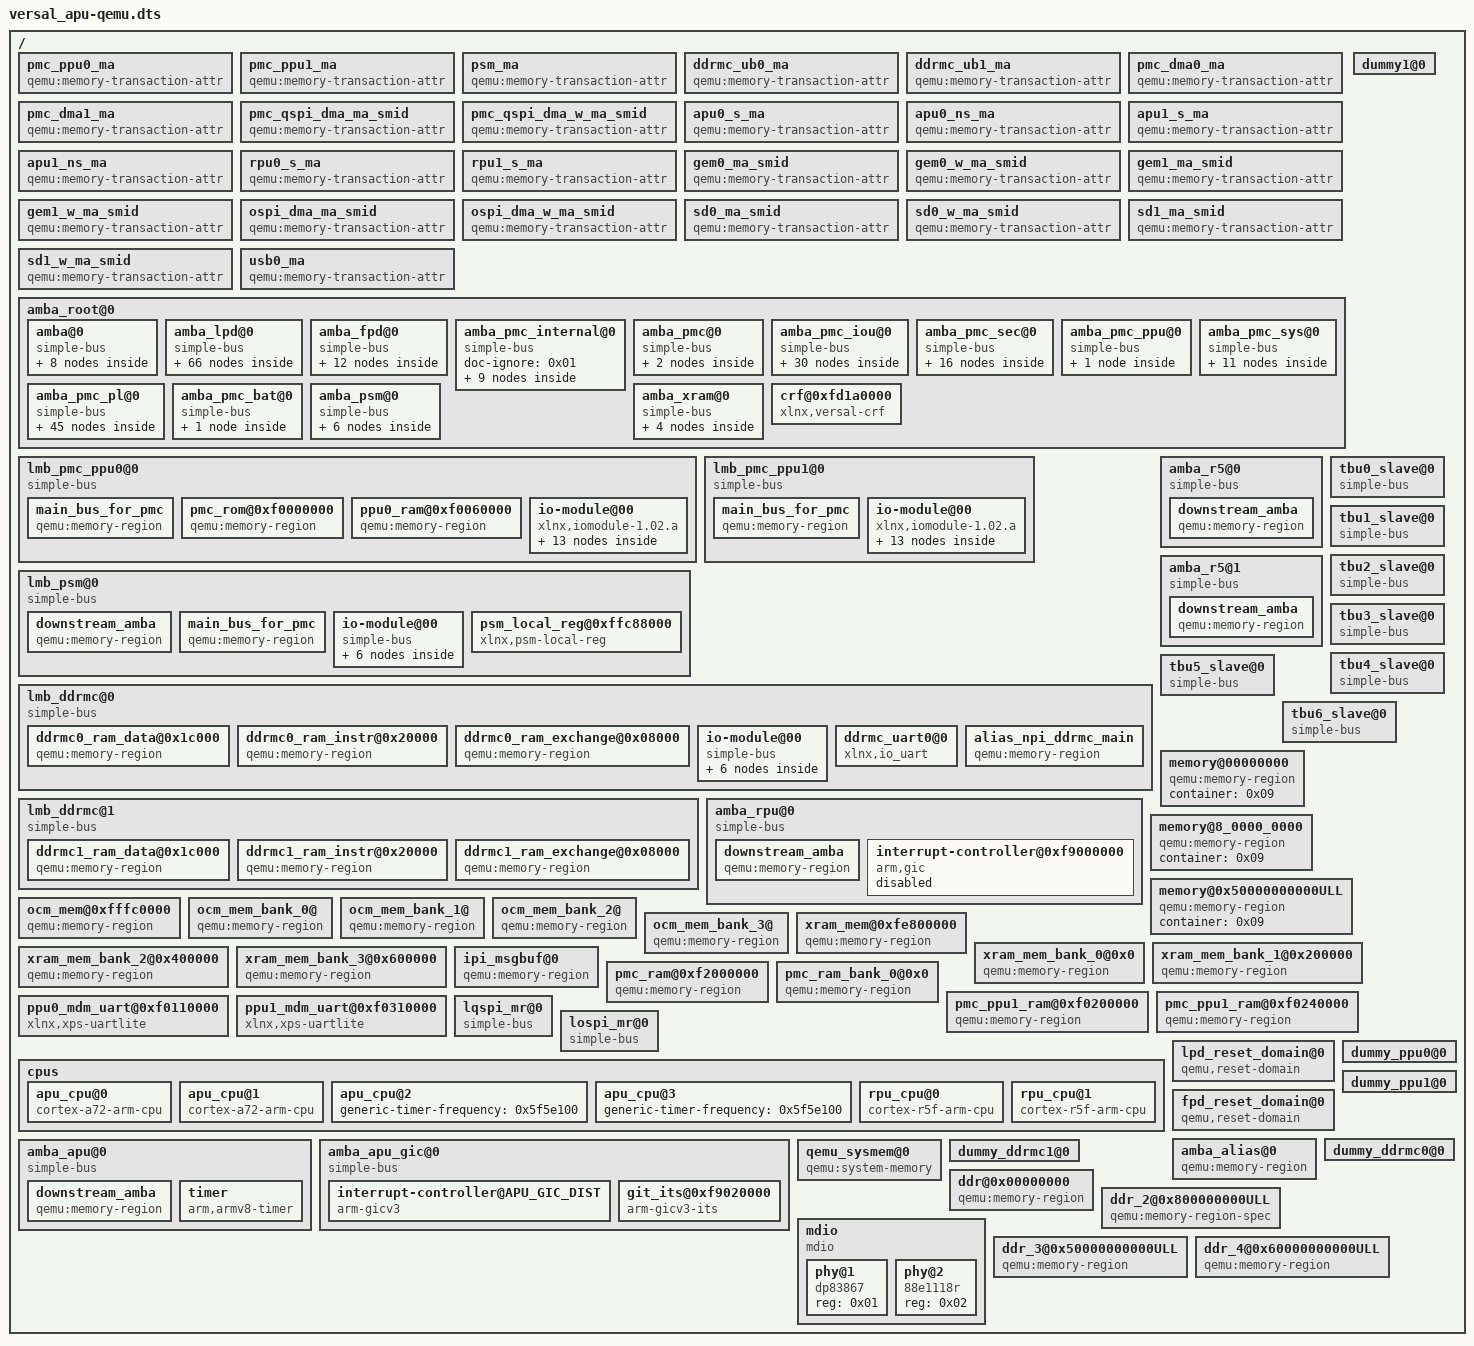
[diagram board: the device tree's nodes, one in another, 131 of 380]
/*
 * Copyright (c) 2025, Advanced Micro Devices, Inc.
 *
 * SPDX-License-Identifier: Apache-2.0
 */

/*
 * NOTE: QEMU EMULATION CONFIGURATION FILE
 *
 * This Device Tree Source (DTS) file is used EXCLUSIVELY for QEMU emulation
 * configuration. It is NOT used by any Zephyr device drivers.
 *
 * Purpose:
 * --------
 * This file provides hardware description for QEMU to emulate the AMD Versal
 * APU platform. QEMU uses this DTS to configure its internal models for:
 *   - Memory regions and address maps
 *   - Interrupt controllers (GIC)
 *   - UART, timers, and other peripherals
 *   - CPU topology and clusters
 *   - Memory transaction attributes
 *   - Inter-processor communication channels
 *
 * File Usage:
 * -----------
 * This file is typically used as:
 *   qemu-system-aarch64 -M arm-generic-fdt -hw-dtb versal_apu-qemu.dtb ...
 *
 * Maintenance Notes:
 * ------------------
 * - Keep this file synchronized with QEMU's AMD Versal machine model
 * - Do not add Zephyr-specific properties here
 * - For Zephyr driver configuration, modify versal_apu.dts instead
 *
 */

/dts-v1/;

/ {
	#address-cells = <0x02>;
	#size-cells = <0x02>;
	#priority-cells = <0x01>;

	pmc_ppu0_ma {
		doc-ignore = <0x01>;
		compatible = "qemu:memory-transaction-attr";
		secure = <0x01>;
		requester-id = <0x246>;
		phandle = <0x8e>;
	};

	pmc_ppu1_ma {
		doc-ignore = <0x01>;
		compatible = "qemu:memory-transaction-attr";
		secure = <0x01>;
		requester-id = <0x247>;
		phandle = <0x8f>;
	};

	psm_ma {
		doc-ignore = <0x01>;
		compatible = "qemu:memory-transaction-attr";
		secure = <0x01>;
		requester-id = <0x238>;
		phandle = <0x90>;
	};

	ddrmc_ub0_ma {
		doc-ignore = <0x01>;
		compatible = "qemu:memory-transaction-attr";
		secure = <0x01>;
		requester-id = <0x00>;
		phandle = <0x91>;
	};

	ddrmc_ub1_ma {
		doc-ignore = <0x01>;
		compatible = "qemu:memory-transaction-attr";
		secure = <0x01>;
		requester-id = <0x00>;
		phandle = <0x92>;
	};

	pmc_dma0_ma {
		doc-ignore = <0x01>;
		compatible = "qemu:memory-transaction-attr";
		secure = <0x01>;
		requester-id = <0x248>;
		phandle = <0x48>;
	};

	pmc_dma1_ma {
		doc-ignore = <0x01>;
		compatible = "qemu:memory-transaction-attr";
		secure = <0x01>;
		requester-id = <0x24b>;
		phandle = <0x49>;
	};

	pmc_qspi_dma_ma_smid {
		doc-ignore = <0x01>;
		compatible = "qemu:memory-transaction-attr";
		requester-id = <0x244>;
		phandle = <0x3d>;
	};

	pmc_qspi_dma_w_ma_smid {
		doc-ignore = <0x01>;
		compatible = "qemu:memory-transaction-attr";
		requester-id = <0x244>;
		phandle = <0x3a>;
	};

	apu0_s_ma {
		doc-ignore = <0x01>;
		compatible = "qemu:memory-transaction-attr";
		secure = <0x01>;
		requester-id = <0x260>;
		phandle = <0x84>;
	};

	apu0_ns_ma {
		doc-ignore = <0x01>;
		compatible = "qemu:memory-transaction-attr";
		secure = <0x00>;
		requester-id = <0x260>;
		phandle = <0x85>;
	};

	apu1_s_ma {
		doc-ignore = <0x01>;
		compatible = "qemu:memory-transaction-attr";
		secure = <0x01>;
		requester-id = <0x261>;
		phandle = <0x86>;
	};

	apu1_ns_ma {
		doc-ignore = <0x01>;
		compatible = "qemu:memory-transaction-attr";
		secure = <0x00>;
		requester-id = <0x261>;
		phandle = <0x87>;
	};

	rpu0_s_ma {
		doc-ignore = <0x01>;
		compatible = "qemu:memory-transaction-attr";
		secure = <0x01>;
		requester-id = <0x200>;
		phandle = <0x88>;
	};

	rpu1_s_ma {
		doc-ignore = <0x01>;
		compatible = "qemu:memory-transaction-attr";
		secure = <0x01>;
		requester-id = <0x204>;
		phandle = <0x89>;
	};

	gem0_ma_smid {
		doc-ignore = <0x01>;
		compatible = "qemu:memory-transaction-attr";
		requester-id = <0x234>;
		phandle = <0x17>;
	};

	gem0_w_ma_smid {
		doc-ignore = <0x01>;
		compatible = "qemu:memory-transaction-attr";
		requester-id = <0x234>;
		phandle = <0x18>;
	};

	gem1_ma_smid {
		doc-ignore = <0x01>;
		compatible = "qemu:memory-transaction-attr";
		requester-id = <0x235>;
		phandle = <0x1c>;
	};

	gem1_w_ma_smid {
		doc-ignore = <0x01>;
		compatible = "qemu:memory-transaction-attr";
		requester-id = <0x235>;
		phandle = <0x1d>;
	};

	ospi_dma_ma_smid {
		doc-ignore = <0x01>;
		compatible = "qemu:memory-transaction-attr";
		requester-id = <0x245>;
		phandle = <0x41>;
	};

	ospi_dma_w_ma_smid {
		doc-ignore = <0x01>;
		compatible = "qemu:memory-transaction-attr";
		requester-id = <0x245>;
		phandle = <0x3b>;
	};

	sd0_ma_smid {
		doc-ignore = <0x01>;
		compatible = "qemu:memory-transaction-attr";
		requester-id = <0x242>;
		phandle = <0x36>;
	};

	sd0_w_ma_smid {
		doc-ignore = <0x01>;
		compatible = "qemu:memory-transaction-attr";
		requester-id = <0x242>;
		phandle = <0x37>;
	};

	sd1_ma_smid {
		doc-ignore = <0x01>;
		compatible = "qemu:memory-transaction-attr";
		requester-id = <0x243>;
		phandle = <0x38>;
	};

	sd1_w_ma_smid {
		doc-ignore = <0x01>;
		compatible = "qemu:memory-transaction-attr";
		requester-id = <0x243>;
		phandle = <0x39>;
	};

	usb0_ma {
		doc-ignore = <0x01>;
		compatible = "qemu:memory-transaction-attr";
		secure = <0x00>;
		requester-id = <0x230>;
		phandle = <0x23>;
	};

	amba_root@0 {
		#address-cells = <0x02>;
		#size-cells = <0x02>;
		#priority-cells = <0x01>;
		#interrupt-cells = <0x01>;
		interrupt-map-mask = <0x00 0x00 0xffff>;
		interrupt-map = <0x00 0x00 0x00 0x01 0x00 0x00 0x04
				 0x00 0x00 0x01 0x01 0x00 0x01 0x04 0x00 0x00 0x02 0x01 0x00 0x02
				 0x04 0x00 0x00 0x03 0x01 0x00 0x03 0x04 0x00 0x00 0x04 0x01 0x00
				 0x04 0x04 0x00 0x00 0x05 0x01 0x00 0x05 0x04 0x00 0x00 0x06 0x01
				 0x00 0x06 0x04 0x00 0x00 0x07 0x01 0x00 0x07 0x04 0x00 0x00 0x08
				 0x01 0x00 0x08 0x04 0x00 0x00 0x09 0x01 0x00 0x09 0x04 0x00 0x00
				 0x09 0x01 0x00 0x09 0x04 0x00 0x00 0x09 0x01 0x00 0x09 0x04 0x00
				 0x00 0x09 0x01 0x00 0x09 0x04 0x00 0x00 0x09 0x01 0x00 0x09 0x04
				 0x00 0x00 0x09 0x01 0x00 0x09 0x04 0x00 0x00 0x09 0x01 0x00 0x09
				 0x04 0x00 0x00 0x09 0x01 0x00 0x09 0x04 0x00 0x00 0x0a 0x01 0x00
				 0x0a 0x04 0x00 0x00 0x0a 0x01 0x00 0x0a 0x04 0x00 0x00 0x0a 0x01
				 0x00 0x0a 0x04 0x00 0x00 0x0a 0x01 0x00 0x0a 0x04 0x00 0x00 0x0a
				 0x01 0x00 0x0a 0x04 0x00 0x00 0x0a 0x01 0x00 0x0a 0x04 0x00 0x00
				 0x0a 0x01 0x00 0x0a 0x04 0x00 0x00 0x0a 0x01 0x00 0x0a 0x04 0x00
				 0x00 0x0a 0x01 0x00 0x0a 0x04 0x00 0x00 0x0a 0x01 0x00 0x0a 0x04
				 0x00 0x00 0x0b 0x01 0x00 0x0b 0x04 0x00 0x00 0x0c 0x01 0x00 0x0c
				 0x04 0x00 0x00 0x0d 0x01 0x00 0x0d 0x04 0x00 0x00 0x0e 0x01 0x00
				 0x0e 0x04 0x00 0x00 0x0f 0x01 0x00 0x0f 0x04 0x00 0x00 0x10 0x01
				 0x00 0x10 0x04 0x00 0x00 0x11 0x01 0x00 0x11 0x04 0x00 0x00 0x12
				 0x01 0x00 0x12 0x04 0x00 0x00 0x13 0x01 0x00 0x13 0x04 0x00 0x00
				 0x14 0x01 0x00 0x14 0x04 0x00 0x00 0x15 0x01 0x00 0x15 0x04 0x00
				 0x00 0x16 0x01 0x00 0x16 0x04 0x00 0x00 0x17 0x01 0x00 0x17 0x04
				 0x00 0x00 0x18 0x01 0x00 0x18 0x04 0x00 0x00 0x19 0x01 0x00 0x19
				 0x04 0x00 0x00 0x1a 0x01 0x00 0x1a 0x04 0x00 0x00 0x1b 0x01 0x00
				 0x1b 0x04 0x00 0x00 0x1c 0x01 0x00 0x1c 0x04 0x00 0x00 0x1d 0x01
				 0x00 0x1d 0x04 0x00 0x00 0x1e 0x01 0x00 0x1e 0x04 0x00 0x00 0x1f
				 0x01 0x00 0x1f 0x04 0x00 0x00 0x20 0x01 0x00 0x20 0x04 0x00 0x00
				 0x21 0x01 0x00 0x21 0x04 0x00 0x00 0x22 0x01 0x00 0x22 0x04 0x00
				 0x00 0x23 0x01 0x00 0x23 0x04 0x00 0x00 0x24 0x01 0x00 0x24 0x04
				 0x00 0x00 0x25 0x01 0x00 0x25 0x04 0x00 0x00 0x26 0x01 0x00 0x26
				 0x04 0x00 0x00 0x27 0x01 0x00 0x27 0x04 0x00 0x00 0x28 0x01 0x00
				 0x28 0x04 0x00 0x00 0x29 0x01 0x00 0x29 0x04 0x00 0x00 0x2a 0x01
				 0x00 0x2a 0x04 0x00 0x00 0x2b 0x01 0x00 0x2b 0x04 0x00 0x00 0x2c
				 0x01 0x00 0x2c 0x04 0x00 0x00 0x2d 0x01 0x00 0x2d 0x04 0x00 0x00
				 0x2e 0x01 0x00 0x2e 0x04 0x00 0x00 0x2f 0x01 0x00 0x2f 0x04 0x00
				 0x00 0x30 0x01 0x00 0x30 0x04 0x00 0x00 0x31 0x01 0x00 0x31 0x04
				 0x00 0x00 0x32 0x01 0x00 0x32 0x04 0x00 0x00 0x33 0x01 0x00 0x33
				 0x04 0x00 0x00 0x34 0x01 0x00 0x34 0x04 0x00 0x00 0x35 0x01 0x00
				 0x35 0x04 0x00 0x00 0x36 0x01 0x00 0x36 0x04 0x00 0x00 0x37 0x01
				 0x00 0x37 0x04 0x00 0x00 0x38 0x01 0x00 0x38 0x04 0x00 0x00 0x39
				 0x01 0x00 0x39 0x04 0x00 0x00 0x3a 0x01 0x00 0x3a 0x04 0x00 0x00
				 0x3b 0x01 0x00 0x3b 0x04 0x00 0x00 0x3c 0x01 0x00 0x3c 0x04 0x00
				 0x00 0x3d 0x01 0x00 0x3d 0x04 0x00 0x00 0x3e 0x01 0x00 0x3e 0x04
				 0x00 0x00 0x3f 0x01 0x00 0x3f 0x04 0x00 0x00 0x40 0x01 0x00 0x40
				 0x04 0x00 0x00 0x41 0x01 0x00 0x41 0x04 0x00 0x00 0x42 0x01 0x00
				 0x42 0x04 0x00 0x00 0x43 0x01 0x00 0x43 0x04 0x00 0x00 0x44 0x01
				 0x00 0x44 0x04 0x00 0x00 0x45 0x01 0x00 0x45 0x04 0x00 0x00 0x46
				 0x01 0x00 0x46 0x04 0x00 0x00 0x47 0x01 0x00 0x47 0x04 0x00 0x00
				 0x48 0x01 0x00 0x48 0x04 0x00 0x00 0x49 0x01 0x00 0x49 0x04 0x00
				 0x00 0x4a 0x01 0x00 0x4a 0x04 0x00 0x00 0x4b 0x01 0x00 0x4b 0x04
				 0x00 0x00 0x4c 0x01 0x00 0x4c 0x04 0x00 0x00 0x4d 0x01 0x00 0x4d
				 0x04 0x00 0x00 0x4e 0x01 0x00 0x4e 0x04 0x00 0x00 0x4f 0x01 0x00
				 0x4f 0x04 0x00 0x00 0x50 0x01 0x00 0x50 0x04 0x00 0x00 0x51 0x01
				 0x00 0x51 0x04 0x00 0x00 0x52 0x01 0x00 0x52 0x04 0x00 0x00 0x53
				 0x01 0x00 0x53 0x04 0x00 0x00 0x54 0x01 0x00 0x54 0x04 0x00 0x00
				 0x55 0x01 0x00 0x55 0x04 0x00 0x00 0x56 0x01 0x00 0x56 0x04 0x00
				 0x00 0x57 0x01 0x00 0x57 0x04 0x00 0x00 0x58 0x01 0x00 0x58 0x04
				 0x00 0x00 0x59 0x01 0x00 0x59 0x04 0x00 0x00 0x5a 0x01 0x00 0x5a
				 0x04 0x00 0x00 0x5b 0x01 0x00 0x5b 0x04 0x00 0x00 0x5c 0x01 0x00
				 0x5c 0x04 0x00 0x00 0x5d 0x01 0x00 0x5d 0x04 0x00 0x00 0x5e 0x01
				 0x00 0x5e 0x04 0x00 0x00 0x5f 0x01 0x00 0x5f 0x04 0x00 0x00 0x60
				 0x01 0x00 0x60 0x04 0x00 0x00 0x61 0x01 0x00 0x61 0x04 0x00 0x00
				 0x62 0x01 0x00 0x62 0x04 0x00 0x00 0x63 0x01 0x00 0x63 0x04 0x00
				 0x00 0x64 0x01 0x00 0x64 0x04 0x00 0x00 0x64 0x01 0x00 0x64 0x04
				 0x00 0x00 0x64 0x01 0x00 0x64 0x04 0x00 0x00 0x64 0x01 0x00 0x64
				 0x04 0x00 0x00 0x64 0x01 0x00 0x64 0x04 0x00 0x00 0x64 0x01 0x00
				 0x64 0x04 0x00 0x00 0x64 0x01 0x00 0x64 0x04 0x00 0x00 0x65 0x01
				 0x00 0x65 0x04 0x00 0x00 0x66 0x01 0x00 0x66 0x04 0x00 0x00 0x67
				 0x01 0x00 0x67 0x04 0x00 0x00 0x68 0x01 0x00 0x68 0x04 0x00 0x00
				 0x69 0x01 0x00 0x69 0x04 0x00 0x00 0x6a 0x01 0x00 0x6a 0x04 0x00
				 0x00 0x6b 0x01 0x00 0x6b 0x04 0x00 0x00 0x6c 0x01 0x00 0x6c 0x04
				 0x00 0x00 0x6d 0x01 0x00 0x6d 0x04 0x00 0x00 0x6e 0x01 0x00 0x6e
				 0x04 0x00 0x00 0x6f 0x01 0x00 0x6f 0x04 0x00 0x00 0x70 0x01 0x00
				 0x70 0x04 0x00 0x00 0x71 0x01 0x00 0x71 0x04 0x00 0x00 0x72 0x01
				 0x00 0x72 0x04 0x00 0x00 0x73 0x01 0x00 0x73 0x04 0x00 0x00 0x74
				 0x01 0x00 0x74 0x04 0x00 0x00 0x75 0x01 0x00 0x75 0x04 0x00 0x00
				 0x76 0x01 0x00 0x76 0x04 0x00 0x00 0x77 0x01 0x00 0x77 0x04 0x00
				 0x00 0x77 0x01 0x00 0x77 0x04 0x00 0x00 0x78 0x01 0x00 0x78 0x04
				 0x00 0x00 0x79 0x01 0x00 0x79 0x04 0x00 0x00 0x79 0x01 0x00 0x79
				 0x04 0x00 0x00 0x79 0x01 0x00 0x79 0x04 0x00 0x00 0x79 0x01 0x00
				 0x79 0x04 0x00 0x00 0x79 0x01 0x00 0x79 0x04 0x00 0x00 0x79 0x01
				 0x00 0x79 0x04 0x00 0x00 0x79 0x01 0x00 0x79 0x04 0x00 0x00 0x79
				 0x01 0x00 0x79 0x04 0x00 0x00 0x79 0x01 0x00 0x79 0x04 0x00 0x00
				 0x7a 0x01 0x00 0x7a 0x04 0x00 0x00 0x7b 0x01 0x00 0x7b 0x04 0x00
				 0x00 0x7c 0x01 0x00 0x7c 0x04 0x00 0x00 0x7d 0x01 0x00 0x7d 0x04
				 0x00 0x00 0x7e 0x01 0x00 0x7e 0x04 0x00 0x00 0x7f 0x01 0x00 0x7f
				 0x04 0x00 0x00 0x80 0x01 0x00 0x80 0x04 0x00 0x00 0x81 0x01 0x00
				 0x81 0x04 0x00 0x00 0x82 0x01 0x00 0x82 0x04 0x00 0x00 0x83 0x01
				 0x00 0x83 0x04 0x00 0x00 0x84 0x01 0x00 0x84 0x04 0x00 0x00 0x84
				 0x01 0x00 0x84 0x04 0x00 0x00 0x85 0x01 0x00 0x85 0x04 0x00 0x00
				 0x86 0x01 0x00 0x86 0x04 0x00 0x00 0x87 0x01 0x00 0x87 0x04 0x00
				 0x00 0x88 0x01 0x00 0x88 0x04 0x00 0x00 0x89 0x01 0x00 0x89 0x04
				 0x00 0x00 0x8a 0x01 0x00 0x8a 0x04 0x00 0x00 0x8b 0x01 0x00 0x8b
				 0x04 0x00 0x00 0x8c 0x01 0x00 0x8c 0x04 0x00 0x00 0x8d 0x01 0x00
				 0x8d 0x04 0x00 0x00 0x8e 0x01 0x00 0x8e 0x04 0x00 0x00 0x8f 0x01
				 0x00 0x8f 0x04 0x00 0x00 0x90 0x01 0x00 0x90 0x04 0x00 0x00 0x91
				 0x01 0x00 0x91 0x04 0x00 0x00 0x92 0x01 0x00 0x92 0x04 0x00 0x00
				 0x93 0x01 0x00 0x93 0x04 0x00 0x00 0x94 0x01 0x00 0x94 0x04 0x00
				 0x00 0x95 0x01 0x00 0x95 0x04 0x00 0x00 0x96 0x01 0x00 0x96 0x04
				 0x00 0x00 0x97 0x01 0x00 0x97 0x04 0x00 0x00 0x98 0x01 0x00 0x98
				 0x04 0x00 0x00 0x99 0x01 0x00 0x99 0x04 0x00 0x00 0x9a 0x01 0x00
				 0x9a 0x04 0x00 0x00 0x9b 0x01 0x00 0x9b 0x04 0x00 0x00 0x9c 0x01
				 0x00 0x9c 0x04 0x00 0x00 0x9d 0x01 0x00 0x9d 0x04 0x00 0x00 0x9e
				 0x01 0x00 0x9e 0x04 0x00 0x00 0xa0 0x01 0x00 0xa0 0x04 0x00 0x00
				 0x00 0x02 0x00 0x00 0x04 0x00 0x00 0x01 0x02 0x00 0x01 0x04 0x00
				 0x00 0x02 0x02 0x00 0x02 0x04 0x00 0x00 0x03 0x02 0x00 0x03 0x04
				 0x00 0x00 0x04 0x02 0x00 0x04 0x04 0x00 0x00 0x05 0x02 0x00 0x05
				 0x04 0x00 0x00 0x06 0x02 0x00 0x06 0x04 0x00 0x00 0x07 0x02 0x00
				 0x07 0x04 0x00 0x00 0x08 0x02 0x00 0x08 0x04 0x00 0x00 0x09 0x02
				 0x00 0x09 0x04 0x00 0x00 0x09 0x02 0x00 0x09 0x04 0x00 0x00 0x09
				 0x02 0x00 0x09 0x04 0x00 0x00 0x09 0x02 0x00 0x09 0x04 0x00 0x00
				 0x09 0x02 0x00 0x09 0x04 0x00 0x00 0x09 0x02 0x00 0x09 0x04 0x00
				 0x00 0x09 0x02 0x00 0x09 0x04 0x00 0x00 0x09 0x02 0x00 0x09 0x04
				 0x00 0x00 0x0a 0x02 0x00 0x0a 0x04 0x00 0x00 0x0a 0x02 0x00 0x0a
				 0x04 0x00 0x00 0x0a 0x02 0x00 0x0a 0x04 0x00 0x00 0x0a 0x02 0x00
				 0x0a 0x04 0x00 0x00 0x0a 0x02 0x00 0x0a 0x04 0x00 0x00 0x0a 0x02
				 0x00 0x0a 0x04 0x00 0x00 0x0a 0x02 0x00 0x0a 0x04 0x00 0x00 0x0a
				 0x02 0x00 0x0a 0x04 0x00 0x00 0x0a 0x02 0x00 0x0a 0x04 0x00 0x00
				 0x0a 0x02 0x00 0x0a 0x04 0x00 0x00 0x0a 0x02 0x00 0x0a 0x04 0x00
				 0x00 0x0b 0x02 0x00 0x0b 0x04 0x00 0x00 0x0c 0x02 0x00 0x0c 0x04
				 0x00 0x00 0x0d 0x02 0x00 0x0d 0x04 0x00 0x00 0x0e 0x02 0x00 0x0e
				 0x04 0x00 0x00 0x0f 0x02 0x00 0x0f 0x04 0x00 0x00 0x10 0x02 0x00
				 0x10 0x04 0x00 0x00 0x11 0x02 0x00 0x11 0x04 0x00 0x00 0x12 0x02
				 0x00 0x12 0x04 0x00 0x00 0x13 0x02 0x00 0x13 0x04 0x00 0x00 0x14
				 0x02 0x00 0x14 0x04 0x00 0x00 0x15 0x02 0x00 0x15 0x04 0x00 0x00
				 0x16 0x02 0x00 0x16 0x04 0x00 0x00 0x17 0x02 0x00 0x17 0x04 0x00
				 0x00 0x18 0x02 0x00 0x18 0x04 0x00 0x00 0x19 0x02 0x00 0x19 0x04
				 0x00 0x00 0x1a 0x02 0x00 0x1a 0x04 0x00 0x00 0x1b 0x02 0x00 0x1b
				 0x04 0x00 0x00 0x1c 0x02 0x00 0x1c 0x04 0x00 0x00 0x1d 0x02 0x00
				 0x1d 0x04 0x00 0x00 0x1e 0x02 0x00 0x1e 0x04 0x00 0x00 0x1f 0x02
				 0x00 0x1f 0x04 0x00 0x00 0x20 0x02 0x00 0x20 0x04 0x00 0x00 0x21
				 0x02 0x00 0x21 0x04 0x00 0x00 0x22 0x02 0x00 0x22 0x04 0x00 0x00
				 0x23 0x02 0x00 0x23 0x04 0x00 0x00 0x24 0x02 0x00 0x24 0x04 0x00
				 0x00 0x25 0x02 0x00 0x25 0x04 0x00 0x00 0x26 0x02 0x00 0x26 0x04
				 0x00 0x00 0x27 0x02 0x00 0x27 0x04 0x00 0x00 0x28 0x02 0x00 0x28
				 0x04 0x00 0x00 0x29 0x02 0x00 0x29 0x04 0x00 0x00 0x2a 0x02 0x00
				 0x2a 0x04 0x00 0x00 0x2b 0x02 0x00 0x2b 0x04 0x00 0x00 0x2c 0x02
				 0x00 0x2c 0x04 0x00 0x00 0x2d 0x02 0x00 0x2d 0x04 0x00 0x00 0x2e
				 0x02 0x00 0x2e 0x04 0x00 0x00 0x2f 0x02 0x00 0x2f 0x04 0x00 0x00
				 0x30 0x02 0x00 0x30 0x04 0x00 0x00 0x31 0x02 0x00 0x31 0x04 0x00
				 0x00 0x32 0x02 0x00 0x32 0x04 0x00 0x00 0x33 0x02 0x00 0x33 0x04
				 0x00 0x00 0x34 0x02 0x00 0x34 0x04 0x00 0x00 0x35 0x02 0x00 0x35
				 0x04 0x00 0x00 0x36 0x02 0x00 0x36 0x04 0x00 0x00 0x37 0x02 0x00
				 0x37 0x04 0x00 0x00 0x38 0x02 0x00 0x38 0x04 0x00 0x00 0x39 0x02
				 0x00 0x39 0x04 0x00 0x00 0x3a 0x02 0x00 0x3a 0x04 0x00 0x00 0x3b
				 0x02 0x00 0x3b 0x04 0x00 0x00 0x3c 0x02 0x00 0x3c 0x04 0x00 0x00
				 0x3d 0x02 0x00 0x3d 0x04 0x00 0x00 0x3e 0x02 0x00 0x3e 0x04 0x00
				 0x00 0x3f 0x02 0x00 0x3f 0x04 0x00 0x00 0x40 0x02 0x00 0x40 0x04
				 0x00 0x00 0x41 0x02 0x00 0x41 0x04 0x00 0x00 0x42 0x02 0x00 0x42
				 0x04 0x00 0x00 0x43 0x02 0x00 0x43 0x04 0x00 0x00 0x44 0x02 0x00
				 0x44 0x04 0x00 0x00 0x45 0x02 0x00 0x45 0x04 0x00 0x00 0x46 0x02
				 0x00 0x46 0x04 0x00 0x00 0x47 0x02 0x00 0x47 0x04 0x00 0x00 0x48
				 0x02 0x00 0x48 0x04 0x00 0x00 0x49 0x02 0x00 0x49 0x04 0x00 0x00
				 0x4a 0x02 0x00 0x4a 0x04 0x00 0x00 0x4b 0x02 0x00 0x4b 0x04 0x00
				 0x00 0x4c 0x02 0x00 0x4c 0x04 0x00 0x00 0x4d 0x02 0x00 0x4d 0x04
				 0x00 0x00 0x4e 0x02 0x00 0x4e 0x04 0x00 0x00 0x4f 0x02 0x00 0x4f
				 0x04 0x00 0x00 0x50 0x02 0x00 0x50 0x04 0x00 0x00 0x51 0x02 0x00
				 0x51 0x04 0x00 0x00 0x52 0x02 0x00 0x52 0x04 0x00 0x00 0x53 0x02
				 0x00 0x53 0x04 0x00 0x00 0x54 0x02 0x00 0x54 0x04 0x00 0x00 0x55
				 0x02 0x00 0x55 0x04 0x00 0x00 0x56 0x02 0x00 0x56 0x04 0x00 0x00
				 0x57 0x02 0x00 0x57 0x04 0x00 0x00 0x58 0x02 0x00 0x58 0x04 0x00
				 0x00 0x59 0x02 0x00 0x59 0x04 0x00 0x00 0x5a 0x02 0x00 0x5a 0x04
				 0x00 0x00 0x5b 0x02 0x00 0x5b 0x04 0x00 0x00 0x5c 0x02 0x00 0x5c
				 0x04 0x00 0x00 0x5d 0x02 0x00 0x5d 0x04 0x00 0x00 0x5e 0x02 0x00
				 0x5e 0x04 0x00 0x00 0x5f 0x02 0x00 0x5f 0x04 0x00 0x00 0x60 0x02
				 0x00 0x60 0x04 0x00 0x00 0x61 0x02 0x00 0x61 0x04 0x00 0x00 0x62
				 0x02 0x00 0x62 0x04 0x00 0x00 0x63 0x02 0x00 0x63 0x04 0x00 0x00
				 0x64 0x02 0x00 0x64 0x04 0x00 0x00 0x64 0x02 0x00 0x64 0x04 0x00
				 0x00 0x64 0x02 0x00 0x64 0x04 0x00 0x00 0x64 0x02 0x00 0x64 0x04
				 0x00 0x00 0x64 0x02 0x00 0x64 0x04 0x00 0x00 0x64 0x02 0x00 0x64
				 0x04 0x00 0x00 0x64 0x02 0x00 0x64 0x04 0x00 0x00 0x65 0x02 0x00
				 0x65 0x04 0x00 0x00 0x66 0x02 0x00 0x66 0x04 0x00 0x00 0x67 0x02
				 0x00 0x67 0x04 0x00 0x00 0x68 0x02 0x00 0x68 0x04 0x00 0x00 0x69
				 0x02 0x00 0x69 0x04 0x00 0x00 0x6a 0x02 0x00 0x6a 0x04 0x00 0x00
				 0x6b 0x02 0x00 0x6b 0x04 0x00 0x00 0x6c 0x02 0x00 0x6c 0x04 0x00
				 0x00 0x6d 0x02 0x00 0x6d 0x04 0x00 0x00 0x6e 0x02 0x00 0x6e 0x04
				 0x00 0x00 0x6f 0x02 0x00 0x6f 0x04 0x00 0x00 0x70 0x02 0x00 0x70
				 0x04 0x00 0x00 0x71 0x02 0x00 0x71 0x04 0x00 0x00 0x72 0x02 0x00
				 0x72 0x04 0x00 0x00 0x73 0x02 0x00 0x73 0x04 0x00 0x00 0x74 0x02
				 0x00 0x74 0x04 0x00 0x00 0x75 0x02 0x00 0x75 0x04 0x00 0x00 0x76
				 0x02 0x00 0x76 0x04 0x00 0x00 0x77 0x02 0x00 0x77 0x04 0x00 0x00
				 0x77 0x02 0x00 0x77 0x04 0x00 0x00 0x78 0x02 0x00 0x78 0x04 0x00
				 0x00 0x79 0x02 0x00 0x79 0x04 0x00 0x00 0x79 0x02 0x00 0x79 0x04
				 0x00 0x00 0x79 0x02 0x00 0x79 0x04 0x00 0x00 0x79 0x02 0x00 0x79
				 0x04 0x00 0x00 0x79 0x02 0x00 0x79 0x04 0x00 0x00 0x79 0x02 0x00
				 0x79 0x04 0x00 0x00 0x79 0x02 0x00 0x79 0x04 0x00 0x00 0x79 0x02
				 0x00 0x79 0x04 0x00 0x00 0x79 0x02 0x00 0x79 0x04 0x00 0x00 0x7a
				 0x02 0x00 0x7a 0x04 0x00 0x00 0x7b 0x02 0x00 0x7b 0x04 0x00 0x00
				 0x7c 0x02 0x00 0x7c 0x04 0x00 0x00 0x7d 0x02 0x00 0x7d 0x04 0x00
				 0x00 0x7e 0x02 0x00 0x7e 0x04 0x00 0x00 0x7f 0x02 0x00 0x7f 0x04
				 0x00 0x00 0x80 0x02 0x00 0x80 0x04 0x00 0x00 0x81 0x02 0x00 0x81
				 0x04 0x00 0x00 0x82 0x02 0x00 0x82 0x04 0x00 0x00 0x83 0x02 0x00
				 0x83 0x04 0x00 0x00 0x84 0x02 0x00 0x84 0x04 0x00 0x00 0x84 0x02
				 0x00 0x84 0x04 0x00 0x00 0x85 0x02 0x00 0x85 0x04 0x00 0x00 0x86
				 0x02 0x00 0x86 0x04 0x00 0x00 0x87 0x02 0x00 0x87 0x04 0x00 0x00
				 0x88 0x02 0x00 0x88 0x04 0x00 0x00 0x89 0x02 0x00 0x89 0x04 0x00
				 0x00 0x8a 0x02 0x00 0x8a 0x04 0x00 0x00 0x8b 0x02 0x00 0x8b 0x04
				 0x00 0x00 0x8c 0x02 0x00 0x8c 0x04 0x00 0x00 0x8d 0x02 0x00 0x8d
				 0x04 0x00 0x00 0x8e 0x02 0x00 0x8e 0x04 0x00 0x00 0x8f 0x02 0x00
				 0x8f 0x04 0x00 0x00 0x90 0x02 0x00 0x90 0x04 0x00 0x00 0x91 0x02
				 0x00 0x91 0x04 0x00 0x00 0x92 0x02 0x00 0x92 0x04 0x00 0x00 0x93
				 0x02 0x00 0x93 0x04 0x00 0x00 0x94 0x02 0x00 0x94 0x04 0x00 0x00
				 0x95 0x02 0x00 0x95 0x04 0x00 0x00 0x96 0x02 0x00 0x96 0x04 0x00
				 0x00 0x97 0x02 0x00 0x97 0x04 0x00 0x00 0x98 0x02 0x00 0x98 0x04
				 0x00 0x00 0x99 0x02 0x00 0x99 0x04 0x00 0x00 0x9a 0x02 0x00 0x9a
				 0x04 0x00 0x00 0x9b 0x02 0x00 0x9b 0x04 0x00 0x00 0x9c 0x02 0x00
				 0x9c 0x04 0x00 0x00 0x9d 0x02 0x00 0x9d 0x04 0x00 0x00 0x9e 0x02
				 0x00 0x9e 0x04 0x00 0x00 0xa0 0x02 0x00 0xa0 0x04 0x00 0x00 0x00
				 0x03 0x00 0x00 0x04 0x00 0x00 0x01 0x03 0x00 0x01 0x04 0x00 0x00
				 0x02 0x03 0x00 0x02 0x04 0x00 0x00 0x03 0x03 0x00 0x03 0x04 0x00
				 0x00 0x04 0x03 0x00 0x04 0x04 0x00 0x00 0x05 0x03 0x00 0x05 0x04
				 0x00 0x00 0x06 0x03 0x00 0x06 0x04 0x00 0x00 0x07 0x03 0x00 0x07
				 0x04 0x00 0x00 0x08 0x03 0x00 0x08 0x04 0x00 0x00 0x09 0x03 0x00
				 0x09 0x04 0x00 0x00 0x09 0x03 0x00 0x09 0x04 0x00 0x00 0x09 0x03
				 0x00 0x09 0x04 0x00 0x00 0x09 0x03 0x00 0x09 0x04 0x00 0x00 0x09
				 0x03 0x00 0x09 0x04 0x00 0x00 0x09 0x03 0x00 0x09 0x04 0x00 0x00
				 0x09 0x03 0x00 0x09 0x04 0x00 0x00 0x09 0x03 0x00 0x09 0x04 0x00
				 0x00 0x0a 0x03 0x00 0x0a 0x04 0x00 0x00 0x0a 0x03 0x00 0x0a 0x04
				 0x00 0x00 0x0a 0x03 0x00 0x0a 0x04 0x00 0x00 0x0a 0x03 0x00 0x0a
				 0x04 0x00 0x00 0x0a 0x03 0x00 0x0a 0x04 0x00 0x00 0x0a 0x03 0x00
				 0x0a 0x04 0x00 0x00 0x0a 0x03 0x00 0x0a 0x04 0x00 0x00 0x0a 0x03
				 0x00 0x0a 0x04 0x00 0x00 0x0a 0x03 0x00 0x0a 0x04 0x00 0x00 0x0a
				 0x03 0x00 0x0a 0x04 0x00 0x00 0x0a 0x03 0x00 0x0a 0x04 0x00 0x00
				 0x0b 0x03 0x00 0x0b 0x04 0x00 0x00 0x0c 0x03 0x00 0x0c 0x04 0x00
				 0x00 0x0d 0x03 0x00 0x0d 0x04 0x00 0x00 0x0e 0x03 0x00 0x0e 0x04
				 0x00 0x00 0x0f 0x03 0x00 0x0f 0x04 0x00 0x00 0x10 0x03 0x00 0x10
				 0x04 0x00 0x00 0x11 0x03 0x00 0x11 0x04 0x00 0x00 0x12 0x03 0x00
				 0x12 0x04 0x00 0x00 0x13 0x03 0x00 0x13 0x04 0x00 0x00 0x14 0x03
				 0x00 0x14 0x04 0x00 0x00 0x15 0x03 0x00 0x15 0x04 0x00 0x00 0x16
				 0x03 0x00 0x16 0x04 0x00 0x00 0x17 0x03 0x00 0x17 0x04 0x00 0x00
				 0x18 0x03 0x00 0x18 0x04 0x00 0x00 0x19 0x03 0x00 0x19 0x04 0x00
				 0x00 0x1a 0x03 0x00 0x1a 0x04 0x00 0x00 0x1b 0x03 0x00 0x1b 0x04
				 0x00 0x00 0x1c 0x03 0x00 0x1c 0x04 0x00 0x00 0x1d 0x03 0x00 0x1d
				 0x04 0x00 0x00 0x1e 0x03 0x00 0x1e 0x04 0x00 0x00 0x1f 0x03 0x00
				 0x1f 0x04 0x00 0x00 0x20 0x03 0x00 0x20 0x04 0x00 0x00 0x21 0x03
				 0x00 0x21 0x04 0x00 0x00 0x22 0x03 0x00 0x22 0x04 0x00 0x00 0x23
				 0x03 0x00 0x23 0x04 0x00 0x00 0x24 0x03 0x00 0x24 0x04 0x00 0x00
				 0x25 0x03 0x00 0x25 0x04 0x00 0x00 0x26 0x03 0x00 0x26 0x04 0x00
				 0x00 0x27 0x03 0x00 0x27 0x04 0x00 0x00 0x28 0x03 0x00 0x28 0x04
				 0x00 0x00 0x29 0x03 0x00 0x29 0x04 0x00 0x00 0x2a 0x03 0x00 0x2a
				 0x04 0x00 0x00 0x2b 0x03 0x00 0x2b 0x04 0x00 0x00 0x2c 0x03 0x00
				 0x2c 0x04 0x00 0x00 0x2d 0x03 0x00 0x2d 0x04 0x00 0x00 0x2e 0x03
				 0x00 0x2e 0x04 0x00 0x00 0x2f 0x03 0x00 0x2f 0x04 0x00 0x00 0x30
				 0x03 0x00 0x30 0x04 0x00 0x00 0x31 0x03 0x00 0x31 0x04 0x00 0x00
				 0x32 0x03 0x00 0x32 0x04 0x00 0x00 0x33 0x03 0x00 0x33 0x04 0x00
				 0x00 0x34 0x03 0x00 0x34 0x04 0x00 0x00 0x35 0x03 0x00 0x35 0x04
				 0x00 0x00 0x36 0x03 0x00 0x36 0x04 0x00 0x00 0x37 0x03 0x00 0x37
				 0x04 0x00 0x00 0x38 0x03 0x00 0x38 0x04 0x00 0x00 0x39 0x03 0x00
				 0x39 0x04 0x00 0x00 0x3a 0x03 0x00 0x3a 0x04 0x00 0x00 0x3b 0x03
				 0x00 0x3b 0x04 0x00 0x00 0x3c 0x03 0x00 0x3c 0x04 0x00 0x00 0x3d
				 0x03 0x00 0x3d 0x04 0x00 0x00 0x3e 0x03 0x00 0x3e 0x04 0x00 0x00
				 0x3f 0x03 0x00 0x3f 0x04 0x00 0x00 0x40 0x03 0x00 0x40 0x04 0x00
				 0x00 0x41 0x03 0x00 0x41 0x04 0x00 0x00 0x42 0x03 0x00 0x42 0x04
				 0x00 0x00 0x43 0x03 0x00 0x43 0x04 0x00 0x00 0x44 0x03 0x00 0x44
				 0x04 0x00 0x00 0x45 0x03 0x00 0x45 0x04 0x00 0x00 0x46 0x03 0x00
				 0x46 0x04 0x00 0x00 0x47 0x03 0x00 0x47 0x04 0x00 0x00 0x48 0x03
				 0x00 0x48 0x04 0x00 0x00 0x49 0x03 0x00 0x49 0x04 0x00 0x00 0x4a
				 0x03 0x00 0x4a 0x04 0x00 0x00 0x4b 0x03 0x00 0x4b 0x04 0x00 0x00
				 0x4c 0x03 0x00 0x4c 0x04 0x00 0x00 0x4d 0x03 0x00 0x4d 0x04 0x00
				 0x00 0x4e 0x03 0x00 0x4e 0x04 0x00 0x00 0x4f 0x03 0x00 0x4f 0x04
				 0x00 0x00 0x50 0x03 0x00 0x50 0x04 0x00 0x00 0x51 0x03 0x00 0x51
				 0x04 0x00 0x00 0x52 0x03 0x00 0x52 0x04 0x00 0x00 0x53 0x03 0x00
				 0x53 0x04 0x00 0x00 0x54 0x03 0x00 0x54 0x04 0x00 0x00 0x55 0x03
				 0x00 0x55 0x04 0x00 0x00 0x56 0x03 0x00 0x56 0x04 0x00 0x00 0x57
				 0x03 0x00 0x57 0x04 0x00 0x00 0x58 0x03 0x00 0x58 0x04 0x00 0x00
				 0x59 0x03 0x00 0x59 0x04 0x00 0x00 0x5a 0x03 0x00 0x5a 0x04 0x00
				 0x00 0x5b 0x03 0x00 0x5b 0x04 0x00 0x00 0x5c 0x03 0x00 0x5c 0x04
				 0x00 0x00 0x5d 0x03 0x00 0x5d 0x04 0x00 0x00 0x5e 0x03 0x00 0x5e
				 0x04 0x00 0x00 0x5f 0x03 0x00 0x5f 0x04 0x00 0x00 0x60 0x03 0x00
				 0x60 0x04 0x00 0x00 0x61 0x03 0x00 0x61 0x04 0x00 0x00 0x62 0x03
				 0x00 0x62 0x04 0x00 0x00 0x63 0x03 0x00 0x63 0x04 0x00 0x00 0x64
				 0x03 0x00 0x64 0x04 0x00 0x00 0x64 0x03 0x00 0x64 0x04 0x00 0x00
				 0x64 0x03 0x00 0x64 0x04 0x00 0x00 0x64 0x03 0x00 0x64 0x04 0x00
				 0x00 0x64 0x03 0x00 0x64 0x04 0x00 0x00 0x64 0x03 0x00 0x64 0x04
				 0x00 0x00 0x64 0x03 0x00 0x64 0x04 0x00 0x00 0x65 0x03 0x00 0x65
				 0x04 0x00 0x00 0x66 0x03 0x00 0x66 0x04 0x00 0x00 0x67 0x03 0x00
				 0x67 0x04 0x00 0x00 0x68 0x03 0x00 0x68 0x04 0x00 0x00 0x69 0x03
				 0x00 0x69 0x04 0x00 0x00 0x6a 0x03 0x00 0x6a 0x04 0x00 0x00 0x6b
				 0x03 0x00 0x6b 0x04 0x00 0x00 0x6c 0x03 0x00 0x6c 0x04 0x00 0x00
				 0x6d 0x03 0x00 0x6d 0x04 0x00 0x00 0x6e 0x03 0x00 0x6e 0x04 0x00
				 0x00 0x6f 0x03 0x00 0x6f 0x04 0x00 0x00 0x70 0x03 0x00 0x70 0x04
				 0x00 0x00 0x71 0x03 0x00 0x71 0x04 0x00 0x00 0x72 0x03 0x00 0x72
				 0x04 0x00 0x00 0x73 0x03 0x00 0x73 0x04 0x00 0x00 0x74 0x03 0x00
				 0x74 0x04 0x00 0x00 0x75 0x03 0x00 0x75 0x04 0x00 0x00 0x76 0x03
				 0x00 0x76 0x04 0x00 0x00 0x77 0x03 0x00 0x77 0x04 0x00 0x00 0x77
				 0x03 0x00 0x77 0x04 0x00 0x00 0x78 0x03 0x00 0x78 0x04 0x00 0x00
				 0x79 0x03 0x00 0x79 0x04 0x00 0x00 0x79 0x03 0x00 0x79 0x04 0x00
				 0x00 0x79 0x03 0x00 0x79 0x04 0x00 0x00 0x79 0x03 0x00 0x79 0x04
				 0x00 0x00 0x79 0x03 0x00 0x79 0x04 0x00 0x00 0x79 0x03 0x00 0x79
				 0x04 0x00 0x00 0x79 0x03 0x00 0x79 0x04 0x00 0x00 0x79 0x03 0x00
				 0x79 0x04 0x00 0x00 0x79 0x03 0x00 0x79 0x04 0x00 0x00 0x7a 0x03
				 0x00 0x7a 0x04 0x00 0x00 0x7b 0x03 0x00 0x7b 0x04 0x00 0x00 0x7c
				 0x03 0x00 0x7c 0x04 0x00 0x00 0x7d 0x03 0x00 0x7d 0x04 0x00 0x00
				 0x7e 0x03 0x00 0x7e 0x04 0x00 0x00 0x7f 0x03 0x00 0x7f 0x04 0x00
				 0x00 0x80 0x03 0x00 0x80 0x04 0x00 0x00 0x81 0x03 0x00 0x81 0x04
				 0x00 0x00 0x82 0x03 0x00 0x82 0x04 0x00 0x00 0x83 0x03 0x00 0x83
				 0x04 0x00 0x00 0x84 0x03 0x00 0x84 0x04 0x00 0x00 0x84 0x03 0x00
				 0x84 0x04 0x00 0x00 0x85 0x03 0x00 0x85 0x04 0x00 0x00 0x86 0x03
				 0x00 0x86 0x04 0x00 0x00 0x87 0x03 0x00 0x87 0x04 0x00 0x00 0x88
				 0x03 0x00 0x88 0x04 0x00 0x00 0x89 0x03 0x00 0x89 0x04 0x00 0x00
				 0x8a 0x03 0x00 0x8a 0x04 0x00 0x00 0x8b 0x03 0x00 0x8b 0x04 0x00
				 0x00 0x8c 0x03 0x00 0x8c 0x04 0x00 0x00 0x8d 0x03 0x00 0x8d 0x04
				 0x00 0x00 0x8e 0x03 0x00 0x8e 0x04 0x00 0x00 0x8f 0x03 0x00 0x8f
				 0x04 0x00 0x00 0x90 0x03 0x00 0x90 0x04 0x00 0x00 0x91 0x03 0x00
				 0x91 0x04 0x00 0x00 0x92 0x03 0x00 0x92 0x04 0x00 0x00 0x93 0x03
				 0x00 0x93 0x04 0x00 0x00 0x94 0x03 0x00 0x94 0x04 0x00 0x00 0x95
				 0x03 0x00 0x95 0x04 0x00 0x00 0x96 0x03 0x00 0x96 0x04 0x00 0x00
				 0x97 0x03 0x00 0x97 0x04 0x00 0x00 0x98 0x03 0x00 0x98 0x04 0x00
				 0x00 0x99 0x03 0x00 0x99 0x04 0x00 0x00 0x9a 0x03 0x00 0x9a 0x04
				 0x00 0x00 0x9b 0x03 0x00 0x9b 0x04 0x00 0x00 0x9c 0x03 0x00 0x9c
				 0x04 0x00 0x00 0x9d 0x03 0x00 0x9d 0x04 0x00 0x00 0x9e 0x03 0x00
				 0x9e 0x04 0x00 0x00 0xa0 0x03 0x00 0xa0 0x04 0x00 0x00 0x00 0x04
				 0x00 0x00 0x04 0x00 0x00 0x01 0x04 0x00 0x01 0x04 0x00 0x00 0x02
				 0x04 0x00 0x02 0x04 0x00 0x00 0x03 0x04 0x00 0x03 0x04 0x00 0x00
				 0x04 0x04 0x00 0x04 0x04 0x00 0x00 0x05 0x04 0x00 0x05 0x04 0x00
				 0x00 0x06 0x04 0x00 0x06 0x04 0x00 0x00 0x07 0x04 0x00 0x07 0x04
				 0x00 0x00 0x08 0x04 0x00 0x08 0x04 0x00 0x00 0x09 0x04 0x00 0x09
				 0x04 0x00 0x00 0x09 0x04 0x00 0x09 0x04 0x00 0x00 0x09 0x04 0x00
				 0x09 0x04 0x00 0x00 0x09 0x04 0x00 0x09 0x04 0x00 0x00 0x09 0x04
				 0x00 0x09 0x04 0x00 0x00 0x09 0x04 0x00 0x09 0x04 0x00 0x00 0x09
				 0x04 0x00 0x09 0x04 0x00 0x00 0x09 0x04 0x00 0x09 0x04 0x00 0x00
				 0x0a 0x04 0x00 0x0a 0x04 0x00 0x00 0x0a 0x04 0x00 0x0a 0x04 0x00
				 0x00 0x0a 0x04 0x00 0x0a 0x04 0x00 0x00 0x0a 0x04 0x00 0x0a 0x04
				 0x00 0x00 0x0a 0x04 0x00 0x0a 0x04 0x00 0x00 0x0a 0x04 0x00 0x0a
				 0x04 0x00 0x00 0x0a 0x04 0x00 0x0a 0x04 0x00 0x00 0x0a 0x04 0x00
				 0x0a 0x04 0x00 0x00 0x0a 0x04 0x00 0x0a 0x04 0x00 0x00 0x0a 0x04
				 0x00 0x0a 0x04 0x00 0x00 0x0a 0x04 0x00 0x0a 0x04 0x00 0x00 0x0b
				 0x04 0x00 0x0b 0x04 0x00 0x00 0x0c 0x04 0x00 0x0c 0x04 0x00 0x00
				 0x0d 0x04 0x00 0x0d 0x04 0x00 0x00 0x0e 0x04 0x00 0x0e 0x04 0x00
				 0x00 0x0f 0x04 0x00 0x0f 0x04 0x00 0x00 0x10 0x04 0x00 0x10 0x04
				 0x00 0x00 0x11 0x04 0x00 0x11 0x04 0x00 0x00 0x12 0x04 0x00 0x12
				 0x04 0x00 0x00 0x13 0x04 0x00 0x13 0x04 0x00 0x00 0x14 0x04 0x00
				 0x14 0x04 0x00 0x00 0x15 0x04 0x00 0x15 0x04 0x00 0x00 0x16 0x04
				 0x00 0x16 0x04 0x00 0x00 0x17 0x04 0x00 0x17 0x04 0x00 0x00 0x18
				 0x04 0x00 0x18 0x04 0x00 0x00 0x19 0x04 0x00 0x19 0x04 0x00 0x00
				 0x1a 0x04 0x00 0x1a 0x04 0x00 0x00 0x1b 0x04 0x00 0x1b 0x04 0x00
				 0x00 0x1c 0x04 0x00 0x1c 0x04 0x00 0x00 0x1d 0x04 0x00 0x1d 0x04
				 0x00 0x00 0x1e 0x04 0x00 0x1e 0x04 0x00 0x00 0x1f 0x04 0x00 0x1f
				 0x04 0x00 0x00 0x20 0x04 0x00 0x20 0x04 0x00 0x00 0x21 0x04 0x00
				 0x21 0x04 0x00 0x00 0x22 0x04 0x00 0x22 0x04 0x00 0x00 0x23 0x04
				 0x00 0x23 0x04 0x00 0x00 0x24 0x04 0x00 0x24 0x04 0x00 0x00 0x25
				 0x04 0x00 0x25 0x04 0x00 0x00 0x26 0x04 0x00 0x26 0x04 0x00 0x00
				 0x27 0x04 0x00 0x27 0x04 0x00 0x00 0x28 0x04 0x00 0x28 0x04 0x00
				 0x00 0x29 0x04 0x00 0x29 0x04 0x00 0x00 0x2a 0x04 0x00 0x2a 0x04
				 0x00 0x00 0x2b 0x04 0x00 0x2b 0x04 0x00 0x00 0x2c 0x04 0x00 0x2c
				 0x04 0x00 0x00 0x2d 0x04 0x00 0x2d 0x04 0x00 0x00 0x2e 0x04 0x00
				 0x2e 0x04 0x00 0x00 0x2f 0x04 0x00 0x2f 0x04 0x00 0x00 0x30 0x04
				 0x00 0x30 0x04 0x00 0x00 0x31 0x04 0x00 0x31 0x04 0x00 0x00 0x32
				 0x04 0x00 0x32 0x04 0x00 0x00 0x33 0x04 0x00 0x33 0x04 0x00 0x00
				 0x34 0x04 0x00 0x34 0x04 0x00 0x00 0x35 0x04 0x00 0x35 0x04 0x00
				 0x00 0x36 0x04 0x00 0x36 0x04 0x00 0x00 0x37 0x04 0x00 0x37 0x04
				 0x00 0x00 0x38 0x04 0x00 0x38 0x04 0x00 0x00 0x39 0x04 0x00 0x39
				 0x04 0x00 0x00 0x3a 0x04 0x00 0x3a 0x04 0x00 0x00 0x3b 0x04 0x00
				 0x3b 0x04 0x00 0x00 0x3c 0x04 0x00 0x3c 0x04 0x00 0x00 0x3d 0x04
				 0x00 0x3d 0x04 0x00 0x00 0x3e 0x04 0x00 0x3e 0x04 0x00 0x00 0x3f
				 0x04 0x00 0x3f 0x04 0x00 0x00 0x40 0x04 0x00 0x40 0x04 0x00 0x00
				 0x41 0x04 0x00 0x41 0x04 0x00 0x00 0x42 0x04 0x00 0x42 0x04 0x00
				 0x00 0x43 0x04 0x00 0x43 0x04 0x00 0x00 0x44 0x04 0x00 0x44 0x04
				 0x00 0x00 0x45 0x04 0x00 0x45 0x04 0x00 0x00 0x46 0x04 0x00 0x46
				 0x04 0x00 0x00 0x47 0x04 0x00 0x47 0x04 0x00 0x00 0x48 0x04 0x00
				 0x48 0x04 0x00 0x00 0x49 0x04 0x00 0x49 0x04 0x00 0x00 0x4a 0x04
				 0x00 0x4a 0x04 0x00 0x00 0x4b 0x04 0x00 0x4b 0x04 0x00 0x00 0x4c
				 0x04 0x00 0x4c 0x04 0x00 0x00 0x4d 0x04 0x00 0x4d 0x04 0x00 0x00
				 0x4e 0x04 0x00 0x4e 0x04 0x00 0x00 0x4f 0x04 0x00 0x4f 0x04 0x00
				 0x00 0x50 0x04 0x00 0x50 0x04 0x00 0x00 0x51 0x04 0x00 0x51 0x04
				 0x00 0x00 0x52 0x04 0x00 0x52 0x04 0x00 0x00 0x53 0x04 0x00 0x53
				 0x04 0x00 0x00 0x54 0x04 0x00 0x54 0x04 0x00 0x00 0x55 0x04 0x00
				 0x55 0x04 0x00 0x00 0x56 0x04 0x00 0x56 0x04 0x00 0x00 0x57 0x04
				 0x00 0x57 0x04 0x00 0x00 0x58 0x04 0x00 0x58 0x04 0x00 0x00 0x59
				 0x04 0x00 0x59 0x04 0x00 0x00 0x5a 0x04 0x00 0x5a 0x04 0x00 0x00
				 0x5b 0x04 0x00 0x5b 0x04 0x00 0x00 0x5c 0x04 0x00 0x5c 0x04 0x00
				 0x00 0x5d 0x04 0x00 0x5d 0x04 0x00 0x00 0x5e 0x04 0x00 0x5e 0x04
				 0x00 0x00 0x5f 0x04 0x00 0x5f 0x04 0x00 0x00 0x60 0x04 0x00 0x60
				 0x04 0x00 0x00 0x61 0x04 0x00 0x61 0x04 0x00 0x00 0x62 0x04 0x00
				 0x62 0x04 0x00 0x00 0x63 0x04 0x00 0x63 0x04 0x00 0x00 0x64 0x04
				 0x00 0x64 0x04 0x00 0x00 0x64 0x04 0x00 0x64 0x04 0x00 0x00 0x64
				 0x04 0x00 0x64 0x04 0x00 0x00 0x64 0x04 0x00 0x64 0x04 0x00 0x00
				 0x64 0x04 0x00 0x64 0x04 0x00 0x00 0x64 0x04 0x00 0x64 0x04 0x00
				 0x00 0x64 0x04 0x00 0x64 0x04 0x00 0x00 0x65 0x04 0x00 0x65 0x04
				 0x00 0x00 0x66 0x04 0x00 0x66 0x04 0x00 0x00 0x67 0x04 0x00 0x67
				 0x04 0x00 0x00 0x68 0x04 0x00 0x68 0x04 0x00 0x00 0x69 0x04 0x00
				 0x69 0x04 0x00 0x00 0x6a 0x04 0x00 0x6a 0x04 0x00 0x00 0x6b 0x04
				 0x00 0x6b 0x04 0x00 0x00 0x6c 0x04 0x00 0x6c 0x04 0x00 0x00 0x6d
				 0x04 0x00 0x6d 0x04 0x00 0x00 0x6e 0x04 0x00 0x6e 0x04 0x00 0x00
				 0x6f 0x04 0x00 0x6f 0x04 0x00 0x00 0x70 0x04 0x00 0x70 0x04 0x00
				 0x00 0x71 0x04 0x00 0x71 0x04 0x00 0x00 0x72 0x04 0x00 0x72 0x04
				 0x00 0x00 0x73 0x04 0x00 0x73 0x04 0x00 0x00 0x74 0x04 0x00 0x74
				 0x04 0x00 0x00 0x75 0x04 0x00 0x75 0x04 0x00 0x00 0x76 0x04 0x00
				 0x76 0x04 0x00 0x00 0x77 0x04 0x00 0x77 0x04 0x00 0x00 0x77 0x04
				 0x00 0x77 0x04 0x00 0x00 0x78 0x04 0x00 0x78 0x04 0x00 0x00 0x79
				 0x04 0x00 0x79 0x04 0x00 0x00 0x79 0x04 0x00 0x79 0x04 0x00 0x00
				 0x79 0x04 0x00 0x79 0x04 0x00 0x00 0x79 0x04 0x00 0x79 0x04 0x00
				 0x00 0x79 0x04 0x00 0x79 0x04 0x00 0x00 0x79 0x04 0x00 0x79 0x04
				 0x00 0x00 0x79 0x04 0x00 0x79 0x04 0x00 0x00 0x79 0x04 0x00 0x79
				 0x04 0x00 0x00 0x79 0x04 0x00 0x79 0x04 0x00 0x00 0x7a 0x04 0x00
				 0x7a 0x04 0x00 0x00 0x7b 0x04 0x00 0x7b 0x04 0x00 0x00 0x7c 0x04
				 0x00 0x7c 0x04 0x00 0x00 0x7d 0x04 0x00 0x7d 0x04 0x00 0x00 0x7e
				 0x04 0x00 0x7e 0x04 0x00 0x00 0x7f 0x04 0x00 0x7f 0x04 0x00 0x00
				 0x80 0x04 0x00 0x80 0x04 0x00 0x00 0x81 0x04 0x00 0x81 0x04 0x00
				 0x00 0x82 0x04 0x00 0x82 0x04 0x00 0x00 0x83 0x04 0x00 0x83 0x04
				 0x00 0x00 0x84 0x04 0x00 0x84 0x04 0x00 0x00 0x84 0x04 0x00 0x84
				 0x04 0x00 0x00 0x85 0x04 0x00 0x85 0x04 0x00 0x00 0x86 0x04 0x00
				 0x86 0x04 0x00 0x00 0x87 0x04 0x00 0x87 0x04 0x00 0x00 0x88 0x04
				 0x00 0x88 0x04 0x00 0x00 0x89 0x04 0x00 0x89 0x04 0x00 0x00 0x8a
				 0x04 0x00 0x8a 0x04 0x00 0x00 0x8b 0x04 0x00 0x8b 0x04 0x00 0x00
				 0x8c 0x04 0x00 0x8c 0x04 0x00 0x00 0x8d 0x04 0x00 0x8d 0x04 0x00
				 0x00 0x8e 0x04 0x00 0x8e 0x04 0x00 0x00 0x8f 0x04 0x00 0x8f 0x04
				 0x00 0x00 0x90 0x04 0x00 0x90 0x04 0x00 0x00 0x91 0x04 0x00 0x91
				 0x04 0x00 0x00 0x92 0x04 0x00 0x92 0x04 0x00 0x00 0x93 0x04 0x00
				 0x93 0x04 0x00 0x00 0x94 0x04 0x00 0x94 0x04 0x00 0x00 0x95 0x04
				 0x00 0x95 0x04 0x00 0x00 0x96 0x04 0x00 0x96 0x04 0x00 0x00 0x97
				 0x04 0x00 0x97 0x04 0x00 0x00 0x98 0x04 0x00 0x98 0x04 0x00 0x00
				 0x99 0x04 0x00 0x99 0x04 0x00 0x00 0x9a 0x04 0x00 0x9a 0x04 0x00
				 0x00 0x9b 0x04 0x00 0x9b 0x04 0x00 0x00 0x9c 0x04 0x00 0x9c 0x04
				 0x00 0x00 0x9d 0x04 0x00 0x9d 0x04 0x00 0x00 0x9e 0x04 0x00 0x9e
				 0x04 0x00 0x00 0xa0 0x04 0x00 0xa0 0x04 0x00 0x00 0x1d 0x05 0x12
				 0x93>;

		amba@0 {
			#address-cells = <0x02>;
			#size-cells = <0x02>;
			#priority-cells = <0x01>;
			compatible = "simple-bus";
			ranges;
			phandle = <0x09>;

			downstream_amba_lpd {
				compatible = "qemu:memory-region";
				alias = <0x06>;
				reg = <0x00 0x00 0xffffffff 0xffffffff 0xffffffff>;
			};

			downstream_amba_fpd {
				compatible = "qemu:memory-region";
				alias = <0x07>;
				reg = <0x00 0x00 0xffffffff 0xffffffff 0xffffffff>;
			};

			downstream_amba_pmc_internal {
				compatible = "qemu:memory-region";
				alias = <0x08>;
				reg = <0x00 0x00 0xffffffff 0xffffffff 0xffffffff>;
			};

			xmpu_ocm@0 {
				compatible = "xlnx,versal-xmpu";
				interrupts = <0x44>;
				reg-extended = <0x09 0x00 0xff980000 0x00 0x10000 0x00 0x09 0x00
						0xfffc0000 0x00 0x40000 0x02>;
				protected-mr = <0x0a>;
				mr-0 = <0x09>;
				protected-base = <0xfffc0000>;
				phandle = <0x94>;
			};

			xmpu_ocm2@0 {
				compatible = "xlnx,versal-xmpu";
				interrupts = <0x44>;
				reg-extended = <0x09 0x00 0xff970000 0x00 0x10000 0x00 0x0b 0x00
						0xfe800000 0x00 0x800000 0x02>;
				protected-mr = <0x0c>;
				mr-0 = <0x06>;
				protected-base = <0xfe800000>;
				phandle = <0x95>;
			};

			loader_write_cpu0_0x1@0xF1110880 {
				compatible = "loader";
				addr = <0xf1110880>;
				data = <0x01>;
				data-len = <0x04>;
				cpu-num = <0x00>;
				attrs-debug = <0x01>;
				attrs-secure = <0x00>;
				attrs-requester-id = <0x00>;
				phandle = <0x96>;
			};

			loader_write_cpu0_0x5@0xFD1A0050 {
				compatible = "loader";
				addr = <0xfd1a0050>;
				data = <0x05>;
				data-len = <0x04>;
				cpu-num = <0x00>;
				attrs-debug = <0x01>;
				attrs-secure = <0x00>;
				attrs-requester-id = <0x00>;
				phandle = <0x97>;
			};

			loader_write_cpu0_0xFF@0xF111010C {
				compatible = "loader";
				addr = <0xf111010c>;
				data = <0xff>;
				data-len = <0x04>;
				cpu-num = <0x00>;
				attrs-debug = <0x01>;
				attrs-secure = <0x00>;
				attrs-requester-id = <0x00>;
				phandle = <0x98>;
			};
		};

		amba_lpd@0 {
			#address-cells = <0x02>;
			#size-cells = <0x02>;
			#priority-cells = <0x01>;
			compatible = "simple-bus";
			ranges;
			phandle = <0x06>;

			downstream_amba_psm {
				compatible = "qemu:memory-region";
				alias = <0x0d>;
				reg = <0x00 0x00 0xffffffff 0xffffffff 0xffffffff>;
			};

			downstream_amba_xram {
				compatible = "qemu:memory-region";
				alias = <0x0b>;
				reg = <0x00 0x00 0xffffffff 0xffffffff 0xffffffff>;
			};

			smmu@0xfd800000 {
				compatible = "arm,mmu-500";
				reg-extended = <0x06 0x00 0xfd800000 0x00 0x800000 0x00 0x0e 0x00
						0x00 0xffffffff 0xffffffff 0x00 0x0f 0x00 0x00
						0xffffffff 0xffffffff 0x00 0x10 0x00 0x00 0xffffffff
						0xffffffff 0x00 0x11 0x00 0x00 0xffffffff 0xffffffff
						0x00 0x12 0x00 0x00 0xffffffff 0xffffffff 0x00 0x13
						0x00 0x00 0xffffffff 0xffffffff 0x00 0x14 0x00 0x00
						0xffffffff 0xffffffff 0x00>;
				interrupt-parent = <0x15>;
				interrupts = <0x00 0x01 0x02 0x03 0x04 0x05 0x06 0x07 0x08 0x09
					      0x0a 0x0b 0x0c 0x0d 0x0e 0x0f 0x10 0x11 0x12 0x13
					      0x14 0x15 0x16 0x17 0x18 0x19 0x1a 0x1b 0x1c 0x1d
					      0x1e 0x1f 0x20 0x21>;
				dma = <0x09>;
				mr-0 = <0x09>;
				mr-1 = <0x09>;
				mr-2 = <0x09>;
				mr-3 = <0x09>;
				mr-4 = <0x09>;
				mr-5 = <0x09>;
				mr-6 = <0x09>;
				num-smr = <0x40>;
				num-cb = <0x20>;
				num-pages = <0x20>;
				version = <0x24>;
				phandle = <0x99>;
			};

			smmu0@0xfd5f0000 {
				compatible = "xlnx,smmu-reg";
				reg = <0x00 0xfd5f0000 0x00 0x10000 0x00>;
				interrupt-controller;
				interrupts = <0x6b>;
				phandle = <0x15>;
			};

			xppu_lpd@0xff990000 {
				compatible = "xlnx,versal-xppu";
				reg-extended = <0x06 0x00 0xff990000 0x00 0x10000 0x00 0x16 0x00
						0xff000000 0x00 0xe00000 0x02 0x16 0x00 0xfe000000
						0x00 0x1000000 0x02 0x09 0x00 0xe0000000 0x00
						0x10000000 0x02>;
				mr = <0x06>;
				interrupts = <0x33>;
				phandle = <0x9a>;
			};

			ethernet@0xff0c0000 {
				#address-cells = <0x01>;
				#size-cells = <0x00>;
				#priority-cells = <0x00>;
				compatible = "cdns,gem";
				interrupts = <0x38 0x38>;
				dma = <0x0e>;
				memattr = <0x17>;
				memattr-write = <0x18>;
				reg = <0x00 0xff0c0000 0x00 0x10000 0x00>;
				num-priority-queues = <0x02>;
				reset-gpios = <0x19 0x01>;
				power-gpios = <0x1a 0x15>;
				mdio = <0x1b>;
				phandle = <0x9b>;
			};

			ethernet@0xff0d0000 {
				#address-cells = <0x01>;
				#size-cells = <0x00>;
				#priority-cells = <0x00>;
				compatible = "cdns,gem";
				interrupts = <0x3a 0x3a>;
				dma = <0x0e>;
				memattr = <0x1c>;
				memattr-write = <0x1d>;
				reg = <0x00 0xff0d0000 0x00 0x10000 0x00>;
				num-priority-queues = <0x02>;
				reset-gpios = <0x19 0x02>;
				power-gpios = <0x1a 0x16>;
				mdio = <0x1b>;
				phandle = <0x9c>;
			};

			serial@0xff000000 {
				compatible = "pl011";
				interrupts = <0x12>;
				reg = <0x00 0xff000000 0x00 0x10000 0x00>;
				reset-gpios = <0x19 0x05>;
				chardev = "con";
				phandle = <0x9d>;
			};

			serial@0xff010000 {
				compatible = "pl011";
				interrupts = <0x13>;
				reg = <0x00 0xff010000 0x00 0x10000 0x00>;
				reset-gpios = <0x19 0x06>;
				chardev = "serial3";
				phandle = <0x9e>;
			};

			canfdbus@0 {
				compatible = "can-bus";
				phandle = <0x1e>;
			};

			can@0xff060000 {
				compatible = "xlnx,versal-canfd";
				rx-fifo0 = <0x40>;
				rx-fifo1 = <0x40>;
				enable-rx-fifo1 = <0x01>;
				canfdbus = <0x1e>;
				interrupts = <0x14>;
				reg = <0x00 0xff060000 0x00 0x10000 0x00>;
				reset-gpios = <0x19 0x09>;
				phandle = <0x9f>;
			};

			can@0xff070000 {
				compatible = "xlnx,versal-canfd";
				rx-fifo0 = <0x40>;
				rx-fifo1 = <0x40>;
				enable-rx-fifo1 = <0x01>;
				canfdbus = <0x1e>;
				interrupts = <0x15>;
				reg = <0x00 0xff070000 0x00 0x10000 0x00>;
				reset-gpios = <0x19 0x0a>;
				phandle = <0xa0>;
			};

			crl@0xff5e0000 {
				compatible = "xlnx,versal-crl";
				reg = <0x00 0xff5e0000 0x00 0x300000 0x00>;
				gpio-controller;
				#gpio-cells = <0x01>;
				phandle = <0x19>;
			};

			slcr@0xff080000 {
				compatible = "xlnx,versal-lpd-iou-slcr";
				reg = <0x00 0xff080000 0x00 0x20000 0x00>;
				phandle = <0xa1>;
			};

			rpu_ctrl@0xff9a0000 {
				compatible = "xlnx,versal-rpu";
				reg-extended = <0x06 0x00 0xff9a0000 0x00 0x10000 0x00
						0x1f 0x00 0x00 0x00 0x80000 0x00
						0x09 0x00 0xffe00000 0x00 0x60000 0x00
						0x20 0x00 0x00 0x00 0x80000 0x00
						0x09 0x00 0xffe90000 0x00 0x50000 0x00>;
				rpu0 = <0x21>;
				rpu1 = <0x22>;
				gpio-controller;
				#gpio-cells = <0x01>;
				gpios = <0x19 0x20 0x19 0x21 0x1a 0x2a 0x1a 0x2b>;
				phandle = <0x6c>;
			};

			ipi@0xff300000 {
				compatible = "xlnx,versal-ipi";
				reg = <0x00 0xff300000 0x00 0x100000 0x00>;
				interrupts = <0x1d 0x1b 0x1e 0x1f 0x20 0x21 0x22 0x23 0x24 0x1c
					      0x0a>;
				reset-gpios = <0x19 0x19>;
				phandle = <0xa2>;
			};

			spi@0xff040000 {
				compatible = "cdns,spi-r1p6";
				interrupts = <0x10>;
				num-ss-bits = <0x04>;
				reg = <0x00 0xff040000 0x00 0x10000 0x00>;
				#address-cells = <0x01>;
				#size-cells = <0x00>;
				#bus-cells = <0x01>;
				reset-gpios = <0x19 0x07>;
				phandle = <0xa3>;

				spi0_flash0@0 {
					#address-cells = <0x01>;
					#size-cells = <0x01>;
					#priority-cells = <0x00>;
					#bus-cells = <0x01>;
					compatible = "m25p80\0st,m25p80";
					spi-max-frequency = <0x2faf080>;
					reg = <0x00 0x00>;
					blockdev-node-name = "spi0_flash0";
					phandle = <0xa4>;

					spi0_flash0@0x00000000 {
						label = "spi0_flash0";
						reg = <0x00 0x100000>;
					};
				};
			};

			spi@0xff050000 {
				compatible = "cdns,spi-r1p6";
				interrupts = <0x11>;
				num-ss-bits = <0x04>;
				reg = <0x00 0xff050000 0x00 0x10000 0x00>;
				#address-cells = <0x01>;
				#size-cells = <0x00>;
				#bus-cells = <0x01>;
				reset-gpios = <0x19 0x08>;
				phandle = <0xa5>;

				spi1_flash0@0 {
					#address-cells = <0x01>;
					#size-cells = <0x01>;
					#priority-cells = <0x00>;
					#bus-cells = <0x01>;
					compatible = "m25p80\0st,m25p80";
					spi-max-frequency = <0x2faf080>;
					reg = <0x00 0x00>;
					blockdev-node-name = "spi1_flash0";
					phandle = <0xa6>;

					spi1_flash0@0x00000000 {
						label = "spi1_flash0";
						reg = <0x00 0x100000>;
					};
				};
			};

			usb2@USB2_0_XHCI {
				compatible = "usb_dwc3";
				reg = <0x00 0xfe20c100 0x00 0x600 0x00 0x00 0xfe200000 0x00
				       0x100000 0x00>;
				interrupts = <0x16 0x17 0x18 0x19>;
				dma = <0x0e>;
				memattr = <0x23>;
				reset-gpios = <0x19 0x04>;
				intrs = <0x04>;
				slots = <0x02>;
				phandle = <0xa7>;
			};

			timer@0xff0e0000 {
				compatible = "xlnx,ps7-ttc-1.00.a";
				interrupts = <0x25 0x26 0x27>;
				reg = <0x00 0xff0e0000 0x00 0x10000 0x00>;
				width = <0x20>;
				reset-gpios = <0x19 0x12>;
				phandle = <0xa8>;
			};

			timer@0xff0f0000 {
				compatible = "xlnx,ps7-ttc-1.00.a";
				interrupts = <0x28 0x29 0x2a>;
				reg = <0x00 0xff0f0000 0x00 0x10000 0x00>;
				width = <0x20>;
				reset-gpios = <0x19 0x13>;
				phandle = <0xa9>;
			};

			timer@0xff100000 {
				compatible = "xlnx,ps7-ttc-1.00.a";
				interrupts = <0x2b 0x2c 0x2d>;
				reg = <0x00 0xff100000 0x00 0x10000 0x00>;
				width = <0x20>;
				reset-gpios = <0x19 0x14>;
				phandle = <0xaa>;
			};

			timer@0xff110000 {
				compatible = "xlnx,ps7-ttc-1.00.a";
				interrupts = <0x2e 0x2f 0x30>;
				reg = <0x00 0xff110000 0x00 0x10000 0x00>;
				width = <0x20>;
				reset-gpios = <0x19 0x15>;
				phandle = <0xab>;
			};

			adma0mattr {
				compatible = "qemu:memory-transaction-attr";
				requester-id = <0x210>;
				phandle = <0x24>;
			};

			dma-controller@0xffa80000 {
				compatible = "xlnx,zdma";
				reg = <0x00 0xffa80000 0x00 0x10000 0x00>;
				bus-width = <0x80>;
				has-parity = <0x01>;
				interrupts = <0x3c>;
				#stream-id-cells = <0x01>;
				dma = <0x0e>;
				memattr = <0x24>;
				reset-gpios = <0x19 0x00>;
				#gpio-cells = <0x01>;
				gpio-names = "memattr-secure";
				gpios = <0x25 0x00>;
				phandle = <0xac>;
			};

			adma1mattr {
				compatible = "qemu:memory-transaction-attr";
				requester-id = <0x212>;
				phandle = <0x26>;
			};

			dma-controller@0xffa90000 {
				compatible = "xlnx,zdma";
				reg = <0x00 0xffa90000 0x00 0x10000 0x00>;
				bus-width = <0x80>;
				has-parity = <0x01>;
				interrupts = <0x3d>;
				#stream-id-cells = <0x01>;
				dma = <0x0e>;
				memattr = <0x26>;
				reset-gpios = <0x19 0x00>;
				#gpio-cells = <0x01>;
				gpio-names = "memattr-secure";
				gpios = <0x25 0x01>;
				phandle = <0xad>;
			};

			adma2mattr {
				compatible = "qemu:memory-transaction-attr";
				requester-id = <0x214>;
				phandle = <0x27>;
			};

			dma-controller@0xffaa0000 {
				compatible = "xlnx,zdma";
				reg = <0x00 0xffaa0000 0x00 0x10000 0x00>;
				bus-width = <0x80>;
				has-parity = <0x01>;
				interrupts = <0x3e>;
				#stream-id-cells = <0x01>;
				dma = <0x0e>;
				memattr = <0x27>;
				reset-gpios = <0x19 0x00>;
				#gpio-cells = <0x01>;
				gpio-names = "memattr-secure";
				gpios = <0x25 0x02>;
				phandle = <0xae>;
			};

			adma3mattr {
				compatible = "qemu:memory-transaction-attr";
				requester-id = <0x216>;
				phandle = <0x28>;
			};

			dma-controller@0xffab0000 {
				compatible = "xlnx,zdma";
				reg = <0x00 0xffab0000 0x00 0x10000 0x00>;
				bus-width = <0x80>;
				has-parity = <0x01>;
				interrupts = <0x3f>;
				#stream-id-cells = <0x01>;
				dma = <0x0e>;
				memattr = <0x28>;
				reset-gpios = <0x19 0x00>;
				#gpio-cells = <0x01>;
				gpio-names = "memattr-secure";
				gpios = <0x25 0x03>;
				phandle = <0xaf>;
			};

			adma4mattr {
				compatible = "qemu:memory-transaction-attr";
				requester-id = <0x218>;
				phandle = <0x29>;
			};

			dma-controller@0xffac0000 {
				compatible = "xlnx,zdma";
				reg = <0x00 0xffac0000 0x00 0x10000 0x00>;
				bus-width = <0x80>;
				has-parity = <0x01>;
				interrupts = <0x40>;
				#stream-id-cells = <0x01>;
				dma = <0x0e>;
				memattr = <0x29>;
				reset-gpios = <0x19 0x00>;
				#gpio-cells = <0x01>;
				gpio-names = "memattr-secure";
				gpios = <0x25 0x04>;
				phandle = <0xb0>;
			};

			adma5mattr {
				compatible = "qemu:memory-transaction-attr";
				requester-id = <0x21a>;
				phandle = <0x2a>;
			};

			dma-controller@0xffad0000 {
				compatible = "xlnx,zdma";
				reg = <0x00 0xffad0000 0x00 0x10000 0x00>;
				bus-width = <0x80>;
				has-parity = <0x01>;
				interrupts = <0x41>;
				#stream-id-cells = <0x01>;
				dma = <0x0e>;
				memattr = <0x2a>;
				reset-gpios = <0x19 0x00>;
				#gpio-cells = <0x01>;
				gpio-names = "memattr-secure";
				gpios = <0x25 0x05>;
				phandle = <0xb1>;
			};

			adma6mattr {
				compatible = "qemu:memory-transaction-attr";
				requester-id = <0x21c>;
				phandle = <0x2b>;
			};

			dma-controller@0xffae0000 {
				compatible = "xlnx,zdma";
				reg = <0x00 0xffae0000 0x00 0x10000 0x00>;
				bus-width = <0x80>;
				has-parity = <0x01>;
				interrupts = <0x42>;
				#stream-id-cells = <0x01>;
				dma = <0x0e>;
				memattr = <0x2b>;
				reset-gpios = <0x19 0x00>;
				#gpio-cells = <0x01>;
				gpio-names = "memattr-secure";
				gpios = <0x25 0x06>;
				phandle = <0xb2>;
			};

			adma7mattr {
				compatible = "qemu:memory-transaction-attr";
				requester-id = <0x21e>;
				phandle = <0x2c>;
			};

			dma-controller@0xffaf0000 {
				compatible = "xlnx,zdma";
				reg = <0x00 0xffaf0000 0x00 0x10000 0x00>;
				bus-width = <0x80>;
				has-parity = <0x01>;
				interrupts = <0x43>;
				#stream-id-cells = <0x01>;
				dma = <0x0e>;
				memattr = <0x2c>;
				reset-gpios = <0x19 0x00>;
				#gpio-cells = <0x01>;
				gpio-names = "memattr-secure";
				gpios = <0x25 0x07>;
				phandle = <0xb3>;
			};

			afi_fm@0xff9b0000 {
				compatible = "xlnx,versal-afi-fm";
				reg = <0x00 0xff9b0000 0x00 0x10000 0x00>;
			};

			lpd_i2c_wrapper {
				ps_i2c@0xff020000 {
					#address-cells = <0x01>;
					#size-cells = <0x00>;
					compatible = "xlnx,ps7-i2c-1.00.a\0cdns,i2c-r1p10";
					interrupts = <0x0e>;
					reg-extended = <0x06 0x00 0xff020000 0x00 0x10000 0x00>;
					reset-gpios = <0x19 0x0b>;
					phandle = <0xb4>;
				};

				ps_i2c@0xff030000 {
					#address-cells = <0x01>;
					#size-cells = <0x00>;
					compatible = "xlnx,ps7-i2c-1.00.a\0cdns,i2c-r1p10";
					interrupts = <0x0f>;
					reg-extended = <0x06 0x00 0xff030000 0x00 0x10000 0x00>;
					reset-gpios = <0x19 0x0c>;
					phandle = <0xb5>;

					i2cswitch@74 {
						#address-cells = <0x01>;
						#size-cells = <0x00>;
						compatible = "nxp,pca9548";
						reg = <0x74>;

						i2c@0 {
							#address-cells = <0x01>;
							#size-cells = <0x00>;
							reg = <0x00>;

							eeprom@54 {
								compatible = "at,24c08";
								reg = <0x54>;
							};
						};
					};
				};
			};

			ocm_ctrl@OCM {
				compatible = "xlnx,zynqmp-ocmc";
				interrupts = <0x0a>;
				memsize = <0x40000>;
				reg = <0x00 0xff960000 0x00 0x10000 0x00>;
				reset-gpios = <0x19 0x18>;
				phandle = <0xb6>;
			};

			xram_slcr@0xff950000 {
				compatible = "xlnx,xram_slcr";
				reg = <0x00 0xff950000 0x00 0x10000 0x00>;
			};

			lpd_slcr@0xff410000 {
				compatible = "xlnx,versal-lpd-slcr";
				reg = <0x00 0xff410000 0x00 0x100000 0x00>;
				phandle = <0xb7>;
			};

			lpd_slcr_secure@0xff510000 {
				compatible = "xlnx,versal-lpd-slcr-secure";
				reg = <0x00 0xff510000 0x00 0x40000 0x00>;
				gpio-controller;
				#gpio-cells = <0x01>;
				phandle = <0x25>;
			};

			lpd_iou_slcr_secure@0xff0a0000 {
				compatible = "xlnx,versal-lpd-iou-slcr-secure";
				reg = <0x00 0xff0a0000 0x00 0x10000 0x00>;
				memattr-gem0 = <0x17>;
				memattr-write-gem0 = <0x18>;
				memattr-gem1 = <0x1c>;
				memattr-write-gem1 = <0x1d>;
				phandle = <0xb8>;
			};

			wwdt@0xff120000 {
				compatible = "xlnx,versal-wwdt";
				reg = <0x00 0xff120000 0x00 0x10000 0x00>;
				interrupts = <0x31 0x45 0x46 0x47>;
				pclk = <0x5f5e100>;
				reset-gpios = <0x19 0x17>;
				phandle = <0xb9>;
			};

			lpd_gpio@0xff0b0000 {
				#gpio-cells = <0x01>;
				compatible = "xlnx,zynqmp-gpio";
				gpio-controller;
				interrupts = <0x0d>;
				reg = <0x00 0xff0b0000 0x00 0x10000 0x00>;
				reset-gpios = <0x19 0x11>;
				phandle = <0xba>;
			};

			intlpd@0xfe600000 {
				compatible = "xlnx-intlpd-config";
				reg = <0x00 0xfe600000 0x00 0x200000 0x00>;
				interrupts = <0x34>;
				phandle = <0xbb>;
			};

			virtio_mmio_0 {
				compatible = "virtio-mmio";
				reg = <0x00 0xa0000000 0x00 0x200 0x00>;
				interrupts = <0x6f>;
			};

			virtio_mmio_1 {
				compatible = "virtio-mmio";
				reg = <0x00 0xa0000200 0x00 0x200 0x00>;
				interrupts = <0x70>;
			};

			virtio_mmio_2 {
				compatible = "virtio-mmio";
				reg = <0x00 0xa0000400 0x00 0x200 0x00>;
				interrupts = <0x71>;
			};

			virtio_mmio_3 {
				compatible = "virtio-mmio";
				reg = <0x00 0xa0000600 0x00 0x200 0x00>;
				interrupts = <0x72>;
			};

			virtio_mmio_4 {
				compatible = "virtio-mmio";
				reg = <0x00 0xa0000800 0x00 0x200 0x00>;
				interrupts = <0x73>;
			};

			virtio_mmio_5 {
				compatible = "virtio-mmio";
				reg = <0x00 0xa0000a00 0x00 0x200 0x00>;
				interrupts = <0x74>;
			};

			virtio_mmio_6 {
				compatible = "virtio-mmio";
				reg = <0x00 0xa0000c00 0x00 0x200 0x00>;
				interrupts = <0x75>;
			};

			virtio_mmio_7 {
				compatible = "virtio-mmio";
				reg = <0x00 0xa0000e00 0x00 0x200 0x00>;
				interrupts = <0x76>;
			};
		};

		amba_fpd@0 {
			#address-cells = <0x02>;
			#size-cells = <0x02>;
			#priority-cells = <0x01>;
			compatible = "simple-bus";
			ranges;
			phandle = <0x07>;

			apu_ctrl@0xfd5c0000 {
				compatible = "xlnx,versal-apu-ctrl";
				reg = <0x00 0xfd5c0000 0x00 0x10000 0x00>;
				cpu0 = <0x2d>;
				cpu1 = <0x2e>;
				#gpio-cells = <0x01>;
				phandle = <0x7a>;
			};

			afi_fm@0xfd360000 {
				compatible = "xlnx,versal-afi-fm";
				reg = <0x00 0xfd360000 0x00 0x10000 0x00>;
			};

			afi_fm@0xfd380000 {
				compatible = "xlnx,versal-afi-fm";
				reg = <0x00 0xfd380000 0x00 0x10000 0x00>;
			};

			cci_reg@0xfd5e0000 {
				compatible = "xlnx,cci_reg";
				reg = <0x00 0xfd5e0000 0x00 0x100000 0x00>;
			};

			cci500@0xfd000000 {
				compatible = "xlnx,cci500";
				reg = <0x00 0xfd000000 0x00 0x100000 0x00>;
			};

			cpm_crcpm@0xfca00000 {
				compatible = "xlnx,versal_cpm_crcpm";
				reg = <0x00 0xfca00000 0x00 0x10000 0x00>;
			};

			cpm_pcsr@0xfcff0000 {
				compatible = "xlnx,versal_cpm_pcsr";
				reg = <0x00 0xfcff0000 0x00 0x10000 0x00>;
			};

			cpm_slcr_secure@0xfca20000 {
				compatible = "xlnx.cpm_slcr_secure";
				reg = <0x00 0xfca20000 0x00 0x10000 0x00>;
			};

			fpd_slcr@0xfd610000 {
				compatible = "xlnx,versal-fpd-slcr";
				interrupts = <0x64>;
				reg = <0x00 0xfd610000 0x00 0x10000 0x00>;
			};

			fpd_slcr_secure@0xfd610000 {
				compatible = "xlnx,versal-fpd-slcr-secure";
				interrupts = <0x64>;
				reg = <0x00 0xfd690000 0x00 0x10000 0x00>;
			};

			watchdog@0xfd4d0000 {
				compatible = "xlnx,versal-wwdt";
				reg = <0x00 0xfd4d0000 0x00 0x10000 0x00>;
				interrupts = <0x64 0x6d 0x6c 0x6e>;
				pclk = <0x5f5e100>;
				reset-gpios = <0x2f 0x1b>;
				phandle = <0xbc>;
			};

			intfpd@0xfd370000 {
				compatible = "xlnx-intfpd-config";
				reg = <0x00 0xfd370000 0x00 0x10000 0x00>;
				interrupts = <0x64>;
				phandle = <0xbd>;
			};
		};

		amba_pmc_internal@0 {
			doc-ignore = <0x01>;
			#address-cells = <0x02>;
			#size-cells = <0x02>;
			#priority-cells = <0x01>;
			compatible = "simple-bus";
			ranges;
			phandle = <0x08>;

			downstream_amba_pmc_ppu {
				compatible = "qemu:memory-region";
				alias = <0x30>;
				reg = <0x00 0x00 0xffffffff 0xffffffff 0xffffffff>;
			};

			downstream_amba_pmc_iou {
				compatible = "qemu:memory-region";
				alias = <0x16>;
				reg = <0x00 0x00 0xffffffff 0xffffffff 0xffffffff>;
			};

			downstream_amba_pmc_sec {
				compatible = "qemu:memory-region";
				alias = <0x31>;
				reg = <0x00 0x00 0xffffffff 0xffffffff 0xffffffff>;
			};

			downstream_amba_pmc_sys {
				compatible = "qemu:memory-region";
				alias = <0x32>;
				reg = <0x00 0x00 0xffffffff 0xffffffff 0xffffffff>;
			};

			downstream_amba_pmc_pl {
				compatible = "qemu:memory-region";
				alias = <0x33>;
				reg = <0x00 0x00 0xffffffff 0xffffffff 0xffffffff>;
			};

			downstream_amba_pmc_bat {
				compatible = "qemu:memory-region";
				alias = <0x34>;
				reg = <0x00 0x00 0xffffffff 0xffffffff 0xffffffff>;
			};

			xmpu_pmc@0 {
				compatible = "xlnx,versal-xmpu";
				interrupts = <0x87>;
				reg-extended = <0x08 0x00 0xf12f0000 0x00 0x10000 0x00 0x08 0x00
						0xf2000000 0x00 0x20000 0x02>;
				protected-mr = <0x35>;
				mr-0 = <0x08>;
				protected-base = <0xf2000000>;
				phandle = <0xbe>;
			};

			xppu_pmc_npi@0xf1300000 {
				compatible = "xlnx,versal-xppu";
				reg-extended = <0x08 0x00 0xf1300000 0x00 0x10000 0x00 0x08 0x00
						0xf6000000 0x00 0x1000000 0x02 0x08 0x00 0xf7000000
						0x00 0x1000000 0x02>;
				mr = <0x33>;
				interrupts = <0x86>;
				phandle = <0xbf>;
			};

			xppu_pmc@0xf1310000 {
				compatible = "xlnx,versal-xppu";
				reg-extended = <0x08 0x00 0xf1310000 0x00 0x10000 0x00 0x09 0x00
						0xf1000000 0x00 0x1000000 0x02 0x09 0x00 0xf0000000
						0x00 0x1000000 0x02 0x09 0x00 0xc0000000 0x00
						0x20000000 0x02>;
				mr = <0x08>;
				interrupts = <0x86>;
				phandle = <0xc0>;
			};
		};

		amba_pmc@0 {
			#address-cells = <0x02>;
			#size-cells = <0x02>;
			#priority-cells = <0x01>;
			compatible = "simple-bus";
			ranges;
			phandle = <0x3c>;

			downstream_amba {
				compatible = "qemu:memory-region";
				alias = <0x09>;
				reg = <0x00 0x00 0xffffffff 0xffffffff 0xffffffff>;
			};

			downstream_amba_pmc_internal {
				compatible = "qemu:memory-region";
				alias = <0x08>;
				reg = <0x00 0x00 0xffffffff 0xffffffff 0xffffffff>;
			};
		};

		amba_pmc_iou@0 {
			#address-cells = <0x02>;
			#size-cells = <0x02>;
			#priority-cells = <0x01>;
			compatible = "simple-bus";
			ranges;
			doc-name = "PMC IOU";
			doc-status = "partial";
			phandle = <0x16>;

			pmc_iou_slcr@0xf1060000 {
				doc-status = "partial";
				compatible = "xlnx,versal-pmc-iou-slcr";
				reg = <0x00 0xf1060000 0x00 0x1000 0x00>;
				interrupts = <0x79>;
				gpio-controller;
				#gpio-cells = <0x02>;
				phandle = <0x45>;
			};

			pmc_iou_slcr_secure@0xf1070000 {
				compatible = "xlnx,versal-pmc-iou-slcr-secure";
				reg = <0x00 0xf1070000 0x00 0x10000 0x00>;
				interrupts = <0x79>;
				memattr-sd0 = <0x36>;
				memattr-write-sd0 = <0x37>;
				memattr-sd1 = <0x38>;
				memattr-write-sd1 = <0x39>;
				memattr-write-qspi = <0x3a>;
				memattr-write-ospi = <0x3b>;
				phandle = <0xc1>;
			};

			pmc_qspi_dma@QSPI_DMA {
				doc-status = "complete";
				compatible = "zynqmp,csu-dma";
				interrupts = <0x7d>;
				#stream-id-cells = <0x01>;
				reg = <0x00 0xf1030800 0x00 0x800 0x00>;
				dma = <0x3c>;
				memattr = <0x3d>;
				memattr-write = <0x3a>;
				is-dst = <0x01>;
				reset-gpios = <0x3e 0x00>;
				phandle = <0x3f>;
			};

			pmc_qspi@0xf1030000 {
				doc-status = "complete";
				#address-cells = <0x01>;
				#size-cells = <0x00>;
				#bus-cells = <0x01>;
				compatible = "xlnx,usmp-gqspi\0cdns,spi-r1p6";
				stream-connected-dma = <0x3f>;
				dma = <0x3c>;
				interrupts = <0x7d>;
				num-ss-bits = <0x02>;
				reg-extended = <0x16 0x00 0xf1030000 0x00 0x1000 0x00 0x40 0x00 0x00
						0x00 0x20000000 0x00>;
				speed-hz = <0x989680>;
				xlnx,fb-clk = <0x01>;
				xlnx,qspi-clk-freq-hz = <0xbebc200>;
				xlnx,qspi-mode = <0x02>;
				reset-gpios = <0x3e 0x00>;
				phandle = <0xc2>;

				qspi_flash_lcs_lb@0 {
					#address-cells = <0x01>;
					#size-cells = <0x01>;
					#priority-cells = <0x00>;
					#bus-cells = <0x01>;
					compatible = "m25qu02gcbb\0st,m25p80";
					spi-max-frequency = <0x2faf080>;
					reg = <0x00 0x00>;
					drive-index = <0x00>;
					phandle = <0xc3>;

					qspi_flash_lcs_lb@0x00000000 {
						label = "qspi_flash_lcs_lb";
						reg = <0x00 0x2000000>;
					};
				};

				qspi_flash_lcs_ub@0 {
					#address-cells = <0x01>;
					#size-cells = <0x01>;
					#priority-cells = <0x00>;
					#bus-cells = <0x01>;
					compatible = "m25qu02gcbb\0st,m25p80";
					spi-max-frequency = <0x2faf080>;
					reg = <0x02 0x01>;
					drive-index = <0x01>;
					phandle = <0xc4>;

					qspi_flash_lcs_ub@0x00000000 {
						label = "qspi_flash_lcs_ub";
						reg = <0x00 0x2000000>;
					};
				};

				qspi_flash_ucs_lb@0 {
					#address-cells = <0x01>;
					#size-cells = <0x01>;
					#priority-cells = <0x00>;
					#bus-cells = <0x01>;
					compatible = "m25qu02gcbb\0st,m25p80";
					spi-max-frequency = <0x2faf080>;
					reg = <0x01 0x00>;
					drive-index = <0x02>;
					phandle = <0xc5>;

					qspi_flash_ucs_lb@0x00000000 {
						label = "qspi_flash_ucs_lb";
						reg = <0x00 0x2000000>;
					};
				};

				qspi_flash_ucs_ub@0 {
					#address-cells = <0x01>;
					#size-cells = <0x01>;
					#priority-cells = <0x00>;
					#bus-cells = <0x01>;
					compatible = "m25qu02gcbb\0st,m25p80";
					spi-max-frequency = <0x2faf080>;
					reg = <0x03 0x01>;
					drive-index = <0x03>;
					phandle = <0xc6>;

					qspi_flash_ucs_ub@0x00000000 {
						label = "qspi_flash_ucs_ub";
						reg = <0x00 0x2000000>;
					};
				};
			};

			ospi_dst_dma@0 {
				doc-status = "complete";
				compatible = "zynqmp,csu-dma";
				interrupts = <0x7c>;
				reg = <0x00 0xf1011800 0x00 0x800 0x00>;
				dma = <0x3c>;
				memattr = <0x41>;
				memattr-write = <0x3b>;
				is-dst = <0x01>;
				reset-gpios = <0x3e 0x01>;
				phandle = <0x43>;
			};

			ospi_src_dma@0 {
				doc-status = "complete";
				compatible = "zynqmp,csu-dma";
				interrupts = <0x7c>;
				reg = <0x00 0xf1011000 0x00 0x800 0x00>;
				dma = <0x42>;
				memattr = <0x41>;
				memattr-write = <0x3b>;
				stream-connected-dma = <0x43>;
				reset-gpios = <0x3e 0x01>;
				phandle = <0x44>;
			};

			spi@0xf1010000 {
				doc-status = "complete";
				#address-cells = <0x01>;
				#size-cells = <0x00>;
				#bus-cells = <0x01>;
				compatible = "xlnx,versal-ospi";
				reg-extended = <0x16 0x00 0xf1010000 0x00 0x1000 0x00 0x42 0x00 0x00
						0x00 0x20000000 0x00>;
				dma-src = <0x44>;
				interrupts = <0x7c>;
				reset-gpios = <0x3e 0x01>;
				gpios = <0x45 0x03 0x00>;
				phandle = <0xc7>;

				ospi_flash_lcs_lb@0 {
					#address-cells = <0x01>;
					#size-cells = <0x01>;
					#priority-cells = <0x00>;
					#bus-cells = <0x01>;
					compatible = "mt35xu02gbba";
					spi-max-frequency = <0x2faf080>;
					reg = <0x00 0x00>;
					drive-index = <0x04>;
					phandle = <0xc8>;

					ospi_flash_lcs_lb@0x00000000 {
						label = "ospi_flash_lcs_lb";
						reg = <0x00 0x2000000>;
					};
				};

				ospi_flash_lcs_ub@0 {
					#address-cells = <0x01>;
					#size-cells = <0x01>;
					#priority-cells = <0x00>;
					#bus-cells = <0x01>;
					compatible = "mt35xu01gbba\0st,m25p80";
					spi-max-frequency = <0x2faf080>;
					reg = <0x01 0x00>;
					drive-index = <0x05>;
					phandle = <0xc9>;

					ospi_flash_lcs_ub@0x00000000 {
						label = "ospi_flash_lcs_ub";
						reg = <0x00 0x2000000>;
					};
				};

				ospi_flash_ucs_lb@0 {
					#address-cells = <0x01>;
					#size-cells = <0x01>;
					#priority-cells = <0x00>;
					#bus-cells = <0x01>;
					compatible = "mt35xu01gbba\0st,m25p80";
					spi-max-frequency = <0x2faf080>;
					reg = <0x02 0x00>;
					drive-index = <0x06>;
					phandle = <0xca>;

					ospi_flash_ucs_lb@0x00000000 {
						label = "ospi_flash_ucs_lb";
						reg = <0x00 0x2000000>;
					};
				};

				ospi_flash_ucs_ub@0 {
					#address-cells = <0x01>;
					#size-cells = <0x01>;
					#priority-cells = <0x00>;
					#bus-cells = <0x01>;
					compatible = "mt35xu01gbba\0st,m25p80";
					spi-max-frequency = <0x2faf080>;
					reg = <0x03 0x00>;
					drive-index = <0x07>;
					phandle = <0xcb>;

					ospi_flash_ucs_ub@0x00000000 {
						label = "ospi_flash_ucs_ub";
						reg = <0x00 0x2000000>;
					};
				};
			};

			gpio_mr_mux@0xc0000000 {
				doc-status = "complete";
				compatible = "gpio-mr-mux";
				reg = <0x00 0xc0000000 0x00 0x20000000 0x00>;
				gpios = <0x45 0x02 0x00 0x45 0x03 0x00>;
				mr-size = <0x20000000>;
				mr0 = <0x40>;
				mr1 = <0x42>;
				mr2 = <0x40>;
				mr3 = <0x42>;
				phandle = <0xcc>;
			};

			pmc_gpio@0xf1020000 {
				#gpio-cells = <0x01>;
				compatible = "xlnx,zynqmp-gpio";
				gpio-controller;
				interrupts = <0x7a>;
				reg = <0x00 0xf1020000 0x00 0x10000 0x00>;
				reset-gpios = <0x3e 0x05>;
				phandle = <0xcd>;
			};

			mmc@0xf1040000 {
				doc-status = "complete";
				compatible = "xilinx,zynqmp-sdhci\0generic-sdhci";
				drive-index = <0x00>;
				reg = <0x00 0xf1040000 0x00 0x10000 0x00>;
				interrupts = <0x7e>;
				dma = <0x0e>;
				memattr = <0x36>;
				memattr-write = <0x37>;
				gpios = <0x45 0x00 0x00>;
				gpio-names = "SLOTTYPE";
				reset-gpios = <0x3e 0x08>;
				is-mmc = <0x00>;
				xlnx,has-cd = <0x01>;
				xlnx,has-power = <0x00>;
				xlnx,has-wp = <0x01>;
				xlnx,sdio-clk-freq-hz = <0x2faf080>;
				phandle = <0xce>;
			};

			mmc@0xf1050000 {
				doc-status = "complete";
				compatible = "xilinx,zynqmp-sdhci\0generic-sdhci";
				drive-index = <0x01>;
				reg = <0x00 0xf1050000 0x00 0x10000 0x00>;
				interrupts = <0x80>;
				dma = <0x0e>;
				memattr = <0x38>;
				memattr-write = <0x39>;
				gpios = <0x45 0x01 0x00>;
				gpio-names = "SLOTTYPE";
				reset-gpios = <0x3e 0x03>;
				is-mmc = <0x00>;
				xlnx,has-cd = <0x01>;
				xlnx,has-power = <0x00>;
				xlnx,has-wp = <0x01>;
				xlnx,sdio-clk-freq-hz = <0x2faf080>;
				phandle = <0xcf>;
			};

			pmc_tap@0xf11a0000 {
				doc-status = "complete";
				doc-comments = "Just a stub.";
				compatible = "xlnx,pmc-tap";
				interrupts-extended = <0x46 0x1e>;
				interrupt-names = "sec-dbg-int";
				reg = <0x00 0xf11a0000 0x00 0x80000 0x00>;
				idcode = <0x14ca8093>;
				phandle = <0xd0>;
			};

			pmc_i2c_wrapper {
				pmc_i2c@0xf1000000 {
					compatible = "xlnx,ps7-i2c-1.00.a\0cdns,i2c-r1p10";
					interrupts = <0x7b>;
					reg-extended = <0x16 0x00 0xf1000000 0x00 0x10000 0x00>;
					#address-cells = <0x01>;
					#size-cells = <0x00>;
					reset-gpios = <0x3e 0x04>;
					phandle = <0xd1>;
				};
			};
		};

		amba_pmc_sec@0 {
			#address-cells = <0x02>;
			#size-cells = <0x02>;
			#priority-cells = <0x01>;
			compatible = "simple-bus";
			ranges;
			doc-name = "PMC Secure";
			doc-status = "in-progress";
			phandle = <0x31>;

			trng@0xf1230000 {
				doc-status = "complete";
				compatible = "xlnx,versal-trng";
				reg = <0x00 0xf1230000 0x00 0x1000 0x00>;
				interrupts = <0x8d>;
			};

			pmc_dma0_src@0 {
				doc-status = "complete";
				compatible = "zynqmp,csu-dma";
				stream-connected-dma0 = <0x47>;
				reg = <0x00 0xf11c0000 0x00 0x800 0x00>;
				dma = <0x3c>;
				memattr = <0x48>;
				dma-width = <0x10>;
				interrupts = <0x83>;
				reset-gpios = <0x3e 0x13>;
				phandle = <0xd2>;
			};

			pmc_dma0_dst@0 {
				doc-status = "complete";
				compatible = "zynqmp,csu-dma";
				reg = <0x00 0xf11c0800 0x00 0x800 0x00>;
				dma = <0x3c>;
				memattr = <0x48>;
				is-dst = <0x01>;
				dma-width = <0x10>;
				interrupts = <0x83>;
				reset-gpios = <0x3e 0x13>;
				phandle = <0x4a>;
			};

			pmc_dma1_src@0 {
				doc-status = "complete";
				compatible = "zynqmp,csu-dma";
				stream-connected-dma1 = <0x47>;
				reg = <0x00 0xf11d0000 0x00 0x800 0x00>;
				dma = <0x3c>;
				memattr = <0x49>;
				dma-width = <0x10>;
				interrupts = <0x84>;
				reset-gpios = <0x3e 0x14>;
				phandle = <0xd3>;
			};

			pmc_dma1_dst@0 {
				doc-status = "complete";
				compatible = "zynqmp,csu-dma";
				reg = <0x00 0xf11d0800 0x00 0x800 0x00>;
				dma = <0x3c>;
				memattr = <0x49>;
				is-dst = <0x01>;
				dma-width = <0x10>;
				interrupts = <0x84>;
				reset-gpios = <0x3e 0x14>;
				phandle = <0x4b>;
			};

			pmc_stream_switch@0 {
				doc-status = "complete";
				compatible = "versal,pmc-sss";
				reg-extended = <0x32 0x00 0xf1110500 0x00 0x04 0x01>;
				stream-connected-dma0 = <0x4a>;
				stream-connected-dma1 = <0x4b>;
				stream-connected-aes = <0x4c>;
				stream-connected-sha = <0x4d>;
				stream-connected-sbi = <0x4e>;
				phandle = <0x47>;
			};

			pmc_sha@0xf1210000 {
				doc-status = "complete";
				compatible = "zynqmp,csu-sha3";
				reg = <0x00 0xf1210000 0x00 0x100 0x00>;
				interrupts = <0x8c>;
				phandle = <0x4d>;
			};

			pmc_aes@0xf11e0000 {
				doc-status = "in-progress";
				#gpio-cells = <0x01>;
				gpio-controller;
				compatible = "xlnx,versal-aes";
				stream-connected-aes = <0x47>;
				reg = <0x00 0xf11e0000 0x00 0x100 0x00>;
				interrupts = <0x89>;
				gpios = <0x4f 0x00 0x4f 0x01>;
				gpio-names = "busy\0done";
				aes-core = <0x4f>;
				phandle = <0x4c>;

				xlnx_aes@0 {
					#gpio-cells = <0x01>;
					compatible = "xlnx-aes";
					gpios = <0x4c 0x00>;
					gpio-names = "reset";
					phandle = <0x4f>;
				};
			};

			pmc_rsa@0xf1200000 {
				doc-status = "complete";
				compatible = "xlnx,versal-ecdsa-rsa";
				reg = <0x00 0xf1200000 0x00 0x6c 0x00>;
				interrupts = <0x8a>;
				phandle = <0xd4>;
			};

			xlnx_pmc_efuse_cache@0xf1250000 {
				doc-status = "complete";
				compatible = "xlnx,pmc-efuse-cache";
				reg = <0x00 0xf1250000 0x00 0xc00 0x00>;
				efuse = <0x50>;
				phandle = <0x55>;
			};

			pmc_puf_ctrl@0 {
				compatible = "xlnx,versal-puf-ctrl";
				zynqmp-aes-key-sink-puf = <0x4c>;
				efuse = <0x50>;
				reg = <0x00 0xf1150000 0x00 0x10000 0x00>;
				#gpio-cells = <0x01>;
				gpio-controller;
				phandle = <0x53>;
			};

			pmc_efuse@0xf1240000 {
				doc-status = "complete";
				compatible = "xlnx,versal-efuse";
				#gpio-cells = <0x02>;
				zynqmp-aes-key-sink-efuses = <0x4c>;
				zynqmp-aes-key-sink-efuses-user0 = <0x4c>;
				zynqmp-aes-key-sink-efuses-user1 = <0x4c>;
				reg = <0x00 0xf1240000 0x00 0x64 0x00>;
				interrupts = <0x8b>;
				efuse = <0x50>;
				phandle = <0xd5>;

				xlnx_efuse@0 {
					doc-ignore = <0x01>;
					compatible = "xlnx,efuse";
					efuse-nr = <0x03>;
					efuse-size = <0x2000>;
					init-factory-extidcode = <0x01>;
					phandle = <0x50>;
				};
			};

			pmc_bbram@0xf11f0000 {
				doc-status = "partial";
				doc-limitations = "Missing AES key connections.";
				compatible = "xlnx,bbram-ctrl";
				reg = <0x00 0xf11f0000 0x00 0x50 0x00>;
				interrupts = <0x79>;
				zynqmp-aes-key-sink-bbram = <0x4c>;
				crc-zpads = <0x00>;
				phandle = <0x54>;
			};

			pmc_sbi@0xf1220000 {
				doc-status = "complete";
				compatible = "pmc,slave-boot";
				reg = <0x00 0xf1220000 0x00 0x10000 0x00 0x00 0xf2100000
				       0x00 0x10000 0x00>;
				interrupts = <0x88>;
				stream-connected-sbi = <0x47>;
				reset-gpios = <0x3e 0x12>;
				phandle = <0x4e>;
			};
		};

		amba_pmc_ppu@0 {
			#address-cells = <0x02>;
			#size-cells = <0x02>;
			#priority-cells = <0x01>;
			compatible = "simple-bus";
			ranges;
			phandle = <0x30>;

			pmc_gic_proxy@0 {
				doc-status = "complete";
				#interrupt-cells = <0x03>;
				interrupt-controller;
				compatible = "xlnx,zynqmp-gicp";
				reg = <0x00 0xf1140000 0x00 0x100 0x00>;
				interrupt-parent = <0x51>;
				interrupts = <0x10>;
				phandle = <0x03>;
			};
		};

		amba_pmc_sys@0 {
			#address-cells = <0x02>;
			#size-cells = <0x02>;
			#priority-cells = <0x01>;
			compatible = "simple-bus";
			ranges;
			doc-name = "PMC System";
			doc-status = "partial";
			phandle = <0x32>;

			pmc_clk_rst@0xf1260000 {
				doc-status = "partial";
				compatible = "xlnx,pmc-clk-rst";
				reg = <0x00 0xf1260000 0x00 0x80000 0x00>;
				interrupts = <0x79>;
				gpio-controller;
				#gpio-cells = <0x01>;
				phandle = <0x3e>;
			};

			pmc_int@0xf1330000 {
				doc-status = "partial";
				compatible = "xlnx,versal-pmc-int";
				reg = <0x00 0xf1330000 0x00 0x280000 0x00>;
				interrupts = <0x85>;
				phandle = <0xd6>;
			};

			pmc_reset_domain@0 {
				compatible = "qemu,reset-device";
				gpios = <0x3e 0x02>;
			};

			pmc_global@0xf1110000 {
				doc-status = "partial";
				#gpio-cells = <0x01>;
				gpio-controller;
				interrupts-extended = <0x51 0x1f 0x51 0x1e 0x51 0x1d
						       0x51 0x1c 0x51 0x1b 0x51 0x17
						       0x51 0x16 0x52 0x00 0x46 0x10
						       0x46 0x11 0x46 0x12 0x46 0x13
						       0x46 0x14 0x46 0x15 0x46 0x16
						       0x46 0x17 0x46 0x18 0x46 0x19
						       0x46 0x1a 0x46 0x1b 0x52 0x00
						       0x46 0x1d>;
				reg = <0x00 0xf1110000 0x00 0x50000 0x00>;
				gpios = <0x53 0x00>;
				bbram = <0x54>;
				efuse = <0x55>;
				compatible = "xlnx,pmc_global";
				phandle = <0x56>;
			};

			pmc_err_mng@0xF1130000 {
				compatible = "xlnx,PmcErrMngmnt";
				reg = <0x00 0xf1130000 0x00 0x10000 0x00>;
				interrupts = <0x79>;
				phandle = <0xd7>;
			};

			pmc_stream_zero@ {
				compatible = "xlnx,pmc-stream-zero";
				reg = <0x00 0xf1110518 0x00 0x04 0x01>;
				stream-connected-pzm = <0x47>;
				phandle = <0xd8>;
			};

			pmc_analog@0xf1160000 {
				compatible = "xlnx,pmc-analog";
				reg = <0x00 0xf1160000 0x00 0x40000 0x00>;
				interrupts-extended = <0x03 0x00 0x9f 0x00>;
				tamper-sink = <0x56>;
			};

			pmc_sysmon@0xf1270000 {
				compatible = "xlnx,pmc-sysmon";
				reg = <0x00 0xf1270000 0x00 0x30000 0x00>;
				interrupts = <0x90 0x91>;
				reset-gpios = <0x3e 0x15>;
				efuse = <0x55>;
				ams-sats = <0x57 0x58>;
				tamper-sink = <0x56>;
				phandle = <0xd9>;
			};

			pmc_ams_sat@0 {
				compatible = "xlnx,ams-sat";
				reg = <0x00 0xf1280000 0x00 0x10000 0x01>;
				phandle = <0x57>;
			};

			pmc_ams_sat@1 {
				compatible = "xlnx,ams-sat";
				reg = <0x00 0xf1290000 0x00 0x10000 0x01>;
				phandle = <0x58>;
			};

			versal_pmc_tamper@ {
				compatible = "xlnx,pmc_tamper";
				reg-extended = <0x32 0x00 0xf1110530 0x00 0x38 0x01 0x59 0x00
						0xf0041100 0x00 0x38 0x02>;
				phandle = <0xda>;
			};
		};

		amba_pmc_pl@0 {
			#address-cells = <0x02>;
			#size-cells = <0x02>;
			#priority-cells = <0x01>;
			compatible = "simple-bus";
			ranges;
			doc-name = "PMC PL";
			doc-status = "partial";
			phandle = <0x33>;

			noc_npi_nir@0xf6000000 {
				compatible = "xlnx.npi-nir";
				reg = <0x00 0xf6000000 0x00 0x10000 0x01>;
				phandle = <0xdb>;
			};

			npi_ddrmc_ub0@0xf6110000 {
				doc-limitations = "Only the uB rst is supported";
				compatible = "xlnx,versal-ddrmc-ub";
				reg = <0x00 0xf6110000 0x00 0x40000 0x01>;
				reset-gpios = <0x3e 0x0f>;
				#gpio-cells = <0x01>;
				gpio-controller;
				phandle = <0xdc>;
			};

			npi_ddrmc_main0@0xf6150000 {
				doc-limitations = "Just a stub";
				compatible = "xlnx,versal-ddrmc-main";
				reg = <0x00 0xf6150000 0x00 0x10000 0x01>;
				reset-gpios = <0x3e 0x0f>;
				phandle = <0x81>;
			};

			npi_ddrmc_noc0@0xf6070000 {
				doc-limitations = "Just a stub";
				compatible = "xlnx,versal-ddrmc-noc";
				reg = <0x00 0xf6070000 0x00 0x20000 0xffffffff>;
				reset-gpios = <0x3e 0x0f>;
				phandle = <0xdd>;
			};

			npi_ddrmc_ub1@0xf6280000 {
				doc-limitations = "Only the uB rst is supported";
				compatible = "xlnx,versal-ddrmc-ub";
				reg = <0x00 0xf6280000 0x00 0x40000 0x01>;
				reset-gpios = <0x3e 0x0f>;
				#gpio-cells = <0x01>;
				gpio-controller;
				phandle = <0xde>;
			};

			npi_ddrmc_main1@0xf62c0000 {
				doc-limitations = "Just a stub";
				compatible = "xlnx,versal-ddrmc-main";
				reg = <0x00 0xf62c0000 0x00 0x10000 0x01>;
				reset-gpios = <0x3e 0x0f>;
				phandle = <0xdf>;
			};

			npi_ddrmc_noc1@0xf6210000 {
				doc-limitations = "Just a stub";
				compatible = "xlnx,versal-ddrmc-noc";
				reg = <0x00 0xf6210000 0x00 0x20000 0xffffffff>;
				reset-gpios = <0x3e 0x0f>;
				phandle = <0xe0>;
			};

			npi_ddrmc_ub2@0xf63f0000 {
				doc-limitations = "Only the uB rst is supported";
				compatible = "xlnx,versal-ddrmc-ub";
				reg = <0x00 0xf63f0000 0x00 0x40000 0x01>;
				reset-gpios = <0x3e 0x0f>;
				#gpio-cells = <0x01>;
				gpio-controller;
				phandle = <0xe1>;
			};

			npi_ddrmc_main2@0xf6430000 {
				doc-limitations = "Just a stub";
				compatible = "xlnx,versal-ddrmc-main";
				reg = <0x00 0xf6430000 0x00 0x10000 0x01>;
				reset-gpios = <0x3e 0x0f>;
				phandle = <0xe2>;
			};

			npi_ddrmc_noc2@0xf6380000 {
				doc-limitations = "Just a stub";
				compatible = "xlnx,versal-ddrmc-noc";
				reg = <0x00 0xf6380000 0x00 0x20000 0xffffffff>;
				reset-gpios = <0x3e 0x0f>;
				phandle = <0xe3>;
			};

			npi_ddrmc_ub3@0xf6560000 {
				doc-limitations = "Only the uB rst is supported";
				compatible = "xlnx,versal-ddrmc-ub";
				reg = <0x00 0xf6560000 0x00 0x40000 0x01>;
				reset-gpios = <0x3e 0x0f>;
				#gpio-cells = <0x01>;
				gpio-controller;
				phandle = <0xe4>;
			};

			npi_ddrmc_main3@0xf65a0000 {
				doc-limitations = "Just a stub";
				compatible = "xlnx,versal-ddrmc-main";
				reg = <0x00 0xf65a0000 0x00 0x10000 0x01>;
				reset-gpios = <0x3e 0x0f>;
				phandle = <0xe5>;
			};

			npi_ddrmc_noc3@0xf64f0000 {
				doc-limitations = "Just a stub";
				compatible = "xlnx,versal-ddrmc-noc";
				reg = <0x00 0xf64f0000 0x00 0x20000 0xffffffff>;
				reset-gpios = <0x3e 0x0f>;
				phandle = <0xe6>;
			};

			npi_ddrmc_xmpu0@0xf6070000 {
				compatible = "xlnx,versal-ddrmc-xmpu";
				reg-extended = <0x33 0x00 0xf6080000 0x00 0x10000
						0x01 0x09 0x00 0x00 0x00
						0x80000000 0x00>;
				protected-mr = <0x5a>;
				mr-0 = <0x09>;
				protected-base = <0x00>;
				regs-variant = "ddrmc";
				phandle = <0xe7>;
			};

			npi_me@0xf70a0000 {
				compatible = "xlnx,me-npi";
				reg = <0x00 0xf70a0000 0x00 0x10000 0x01>;
				reset-gpios = <0x3e 0x0f>;
				phandle = <0xe8>;
			};

			noc_npi_devs@0 {
				compatible = "xlnx,noc-npi-dev";
				reg = <0x00 0xf6000000 0x00 0x2000000 0x00>;
				phandle = <0xe9>;
			};

			cfu@0xf12b0000 {
				doc-status = "partial";
				doc-comments = "Stub";
				doc-limitations = "No way to extract CFRAME data.";
				compatible = "xlnx,versal-cfu";
				reg = <0x00 0xf12b0000 0x00 0x1000 0x00 0x00 0xf12c0000 0x00
				       0x1000 0x00 0x00 0xf1f80000 0x00 0x40000 0x00>;
				interrupts = <0x78>;
				chardev = "pmc-cfu";
				dma = <0x3c>;
				cframe0 = <0x5b>;
				cframe1 = <0x5c>;
				cframe2 = <0x5d>;
				cframe3 = <0x5e>;
				cframe4 = <0x5f>;
				cframe5 = <0x60>;
				cframe6 = <0x61>;
				cframe7 = <0x62>;
				cframe8 = <0x63>;
				cframe9 = <0x64>;
				cframe10 = <0x65>;
				cframe11 = <0x66>;
				cframe12 = <0x67>;
				cframe13 = <0x68>;
				cframe14 = <0x69>;
				phandle = <0x6a>;
			};

			cfu_fdro@0xf12c2000 {
				compatible = "xlnx,versal-cfu-fdro";
				reg = <0x00 0xf12c2000 0x00 0x1000 0x00>;
				phandle = <0x6b>;
			};

			cfu_sfr@0xf12c1000 {
				compatible = "xlnx,versal-cfu-sfr";
				reg = <0x00 0xf12c1000 0x00 0x1000 0x00>;
				cfu = <0x6a>;
				phandle = <0xea>;
			};

			cframe0_reg@0xf12d0000 {
				compatible = "xlnx.cframe_reg";
				reg = <0x00 0xf12d0000 0x00 0x1000 0x00 0x00 0xf12d1000 0x00
				       0x1000 0x00>;
				interrupts = <0x79>;
				cfu-fdro = <0x6b>;
				blktype0-frames = <0x853f>;
				blktype1-frames = <0xdc8>;
				blktype2-frames = <0x3200>;
				blktype3-frames = <0x0b>;
				blktype4-frames = <0x05>;
				blktype5-frames = <0x01>;
				blktype6-frames = <0x01>;
				phandle = <0x5b>;
			};

			cframe1_reg@0xf12d2000 {
				compatible = "xlnx.cframe_reg";
				reg = <0x00 0xf12d2000 0x00 0x1000 0x00 0x00 0xf12d3000 0x00
				       0x1000 0x00>;
				interrupts = <0x79>;
				cfu-fdro = <0x6b>;
				blktype0-frames = <0x9662>;
				blktype1-frames = <0xf01>;
				blktype2-frames = <0x3c01>;
				blktype3-frames = <0x0d>;
				blktype4-frames = <0x07>;
				blktype5-frames = <0x03>;
				blktype6-frames = <0x01>;
				phandle = <0x5c>;
			};

			cframe2_reg@0xf12d4000 {
				compatible = "xlnx.cframe_reg";
				reg = <0x00 0xf12d4000 0x00 0x1000 0x00 0x00 0xf12d5000 0x00
				       0x1000 0x00>;
				interrupts = <0x79>;
				cfu-fdro = <0x6b>;
				blktype0-frames = <0x9662>;
				blktype1-frames = <0xf01>;
				blktype2-frames = <0x3c01>;
				blktype3-frames = <0x0d>;
				blktype4-frames = <0x07>;
				blktype5-frames = <0x03>;
				blktype6-frames = <0x01>;
				phandle = <0x5d>;
			};

			cframe3_reg@0xf12d6000 {
				compatible = "xlnx.cframe_reg";
				reg = <0x00 0xf12d6000 0x00 0x1000 0x00 0x00 0xf12d7000 0x00
				       0x1000 0x00>;
				interrupts = <0x79>;
				cfu-fdro = <0x6b>;
				blktype0-frames = <0x9662>;
				blktype1-frames = <0xf01>;
				blktype2-frames = <0x3c01>;
				blktype3-frames = <0x0d>;
				blktype4-frames = <0x07>;
				blktype5-frames = <0x03>;
				blktype6-frames = <0x01>;
				phandle = <0x5e>;
			};

			cframe4_reg@0xf12d8000 {
				compatible = "xlnx.cframe_reg";
				reg = <0x00 0xf12d8000 0x00 0x1000 0x00 0x00 0xf12d9000 0x00
				       0x1000 0x00>;
				interrupts = <0x79>;
				cfu-fdro = <0x6b>;
				phandle = <0x5f>;
			};

			cframe5_reg@0xf12da000 {
				compatible = "xlnx.cframe_reg";
				reg = <0x00 0xf12da000 0x00 0x1000 0x00 0x00 0xf12db000 0x00
				       0x1000 0x00>;
				interrupts = <0x79>;
				cfu-fdro = <0x6b>;
				phandle = <0x60>;
			};

			cframe6_reg@0xf12dc000 {
				compatible = "xlnx.cframe_reg";
				reg = <0x00 0xf12dc000 0x00 0x1000 0x00 0x00 0xf12dd000 0x00
				       0x1000 0x00>;
				interrupts = <0x79>;
				cfu-fdro = <0x6b>;
				phandle = <0x61>;
			};

			cframe7_reg@0xf12de000 {
				compatible = "xlnx.cframe_reg";
				reg = <0x00 0xf12de000 0x00 0x1000 0x00 0x00 0xf12df000 0x00
				       0x1000 0x00>;
				interrupts = <0x79>;
				cfu-fdro = <0x6b>;
				phandle = <0x62>;
			};

			cframe8_reg@0xf12e0000 {
				compatible = "xlnx.cframe_reg";
				reg = <0x00 0xf12e0000 0x00 0x1000 0x00 0x00 0xf12e1000 0x00
				       0x1000 0x00>;
				interrupts = <0x79>;
				cfu-fdro = <0x6b>;
				phandle = <0x63>;
			};

			cframe9_reg@0xf12e2000 {
				compatible = "xlnx.cframe_reg";
				reg = <0x00 0xf12e2000 0x00 0x1000 0x00 0x00 0xf12e3000 0x00
				       0x1000 0x00>;
				interrupts = <0x79>;
				cfu-fdro = <0x6b>;
				phandle = <0x64>;
			};

			cframe10_reg@0xf12e4000 {
				compatible = "xlnx.cframe_reg";
				reg = <0x00 0xf12e4000 0x00 0x1000 0x00 0x00 0xf12e5000 0x00
				       0x1000 0x00>;
				interrupts = <0x79>;
				cfu-fdro = <0x6b>;
				phandle = <0x65>;
			};

			cframe11_reg@0xf12e6000 {
				compatible = "xlnx.cframe_reg";
				reg = <0x00 0xf12e6000 0x00 0x1000 0x00 0x00 0xf12e7000 0x00
				       0x1000 0x00>;
				interrupts = <0x79>;
				cfu-fdro = <0x6b>;
				phandle = <0x66>;
			};

			cframe12_reg@0xf12e8000 {
				compatible = "xlnx.cframe_reg";
				reg = <0x00 0xf12e8000 0x00 0x1000 0x00 0x00 0xf12e9000 0x00
				       0x1000 0x00>;
				interrupts = <0x79>;
				cfu-fdro = <0x6b>;
				phandle = <0x67>;
			};

			cframe13_reg@0xf12ea000 {
				compatible = "xlnx.cframe_reg";
				reg = <0x00 0xf12ea000 0x00 0x1000 0x00 0x00 0xf12eb000 0x00
				       0x1000 0x00>;
				interrupts = <0x79>;
				cfu-fdro = <0x6b>;
				phandle = <0x68>;
			};

			cframe14_reg@0xf12ec000 {
				compatible = "xlnx.cframe_reg";
				reg = <0x00 0xf12ec000 0x00 0x1000 0x00 0x00 0xf12ed000 0x00
				       0x1000 0x00>;
				interrupts = <0x79>;
				cfu-fdro = <0x6b>;
				phandle = <0x69>;
			};

			cframe_bcast_reg@0xf12ee000 {
				compatible = "xlnx.cframe-bcast-reg";
				reg = <0x00 0xf12ee000 0x00 0x1000 0x00 0x00 0xf12ef000 0x00
				       0x1000 0x00>;
				cframe0 = <0x5b>;
				cframe1 = <0x5c>;
				cframe2 = <0x5d>;
				cframe3 = <0x5e>;
				cframe4 = <0x5f>;
				cframe5 = <0x60>;
				cframe6 = <0x61>;
				cframe7 = <0x62>;
				cframe8 = <0x63>;
				cframe9 = <0x64>;
				cframe10 = <0x65>;
				cframe11 = <0x66>;
				cframe12 = <0x67>;
				cframe13 = <0x68>;
				cframe14 = <0x69>;
				phandle = <0xeb>;
			};

			npi_gty0@0xf6890000 {
				doc-limitations = "Just a stub";
				compatible = "xlnx,versal-gty-npi";
				reg = <0x00 0xf6890000 0x00 0x20000 0xffffffff>;
				reset-gpios = <0x3e 0x0f>;
				phandle = <0xec>;
			};

			npi_gty1@0xf68f0000 {
				doc-limitations = "Just a stub";
				compatible = "xlnx,versal-gty-npi";
				reg = <0x00 0xf68f0000 0x00 0x20000 0xffffffff>;
				reset-gpios = <0x3e 0x0f>;
				phandle = <0xed>;
			};

			npi_gty2@0xf6940000 {
				doc-limitations = "Just a stub";
				compatible = "xlnx,versal-gty-npi";
				reg = <0x00 0xf6940000 0x00 0x20000 0xffffffff>;
				reset-gpios = <0x3e 0x0f>;
				phandle = <0xee>;
			};

			npi_gty3@0xf6990000 {
				doc-limitations = "Just a stub";
				compatible = "xlnx,versal-gty-npi";
				reg = <0x00 0xf6990000 0x00 0x20000 0xffffffff>;
				reset-gpios = <0x3e 0x0f>;
				phandle = <0xef>;
			};

			npi_gty4@0xf69e0000 {
				doc-limitations = "Just a stub";
				compatible = "xlnx,versal-gty-npi";
				reg = <0x00 0xf69e0000 0x00 0x20000 0xffffffff>;
				reset-gpios = <0x3e 0x0f>;
				phandle = <0xf0>;
			};

			npi_gty5@0xf6a30000 {
				doc-limitations = "Just a stub";
				compatible = "xlnx,versal-gty-npi";
				reg = <0x00 0xf6a30000 0x00 0x20000 0xffffffff>;
				reset-gpios = <0x3e 0x0f>;
				phandle = <0xf1>;
			};

			npi_gty6@0xf6a90000 {
				doc-limitations = "Just a stub";
				compatible = "xlnx,versal-gty-npi";
				reg = <0x00 0xf6a90000 0x00 0x20000 0xffffffff>;
				reset-gpios = <0x3e 0x0f>;
				phandle = <0xf2>;
			};

			npi_gty7@0xf70e0000 {
				doc-limitations = "Just a stub";
				compatible = "xlnx,versal-gty-npi";
				reg = <0x00 0xf70e0000 0x00 0x20000 0xffffffff>;
				reset-gpios = <0x3e 0x0f>;
				phandle = <0xf3>;
			};

			npi_gty8@0xf7150000 {
				doc-limitations = "Just a stub";
				compatible = "xlnx,versal-gty-npi";
				reg = <0x00 0xf7150000 0x00 0x20000 0xffffffff>;
				reset-gpios = <0x3e 0x0f>;
				phandle = <0xf4>;
			};

			npi_gty9@0xf71b0000 {
				doc-limitations = "Just a stub";
				compatible = "xlnx,versal-gty-npi";
				reg = <0x00 0xf71b0000 0x00 0x20000 0xffffffff>;
				reset-gpios = <0x3e 0x0f>;
				phandle = <0xf5>;
			};
		};

		amba_pmc_bat@0 {
			#address-cells = <0x02>;
			#size-cells = <0x02>;
			#priority-cells = <0x01>;
			compatible = "simple-bus";
			ranges;
			doc-name = "PMC BAT";
			doc-status = "partial";
			phandle = <0x34>;

			rtc@0xf12a0000 {
				doc-status = "complete";
				doc-comments = "Versal PMC RTC";
				compatible = "xlnx,zynqmp-rtc";
				interrupts = <0x79 0x8e 0x8f>;
				reg = <0x00 0xf12a0000 0x00 0x10000 0x00>;
				xlnx,version = "2.0.0";
				phandle = <0xf6>;
			};
		};

		amba_psm@0 {
			#address-cells = <0x02>;
			#size-cells = <0x02>;
			#priority-cells = <0x01>;
			compatible = "simple-bus";
			ranges;
			phandle = <0x0d>;

			psm_ram_instr@0xffc00000 {
				device_type = "memory";
				compatible = "qemu:memory-region";
				qemu,ram = <0x01>;
				reg = <0x00 0xffc00000 0x00 0x20000 0x01>;
				phandle = <0xf7>;
			};

			psm_ram_data@0xffc20000 {
				device_type = "memory";
				compatible = "qemu:memory-region";
				qemu,ram = <0x01>;
				reg = <0x00 0xffc20000 0x00 0x20000 0x01>;
				phandle = <0xf8>;
			};

			psm_gic_proxy@0 {
				doc-status = "complete";
				#interrupt-cells = <0x03>;
				interrupt-controller;
				compatible = "xlnx,zynqmp-gicp";
				reg = <0x00 0xffc92000 0x00 0x100 0x00>;
				interrupt-parent = <0x05>;
				interrupts = <0x16>;
				phandle = <0x04>;
			};

			psm_global_reg@0xffc90000 {
				compatible = "xlnx,psm-global-reg";
				reg = <0x00 0xffc90000 0x00 0xf000 0x00>;
				interrupt-parent = <0x05>;
				interrupts = <0x1c 0x1e 0x1a 0x1b 0x1f 0x18>;
				#gpio-cells = <0x01>;
				gpios = <0x1a 0x20 0x1a 0x21 0x1a 0x22 0x1a 0x23 0x1a 0x24
					 0x1a 0x25 0x1a 0x26 0x1a 0x27 0x1a 0x28 0x1a 0x29
					 0x1a 0x2a 0x1a 0x2b 0x1a 0x2c 0x1a 0x2d 0x1a 0x2e
					 0x1a 0x2f 0x1a 0x30 0x1a 0x31 0x1a 0x32 0x1a 0x33
					 0x1a 0x34 0x1a 0x35 0x1a 0x36 0x1a 0x37 0x1a 0x38
					 0x1a 0x39 0x1a 0x3a 0x1a 0x3b 0x1a 0x3c 0x1a 0x3d
					 0x1a 0x3e 0x1a 0x3f 0x1a 0x40 0x1a 0x41 0x1a 0x42
					 0x1a 0x43 0x1a 0x44 0x1a 0x45 0x1a 0x46 0x1a 0x47
					 0x1a 0x48 0x1a 0x49 0x1a 0x4a 0x1a 0x4b 0x1a 0x4c
					 0x1a 0x4d 0x1a 0x4e 0x1a 0x4f 0x1a 0x50 0x1a 0x51
					 0x1a 0x52 0x1a 0x53 0x1a 0x54 0x1a 0x55 0x1a 0x56
					 0x1a 0x57 0x1a 0x58 0x1a 0x59 0x1a 0x5a 0x1a 0x5b
					 0x1a 0x5c 0x1a 0x5d 0x1a 0x5e 0x1a 0x5f 0x1a 0x60
					 0x1a 0x61 0x1a 0x62 0x1a 0x63 0x6c 0x08 0x6c 0x09
					 0x01 0x00 0x01 0x01>;
				phandle = <0xf9>;
			};

			psm_err_mng@0xffc90000 {
				compatible = "xlnx,psm-err-mng";
				reg = <0x00 0xffc91000 0x00 0x100 0x00>;
				phandle = <0xfa>;
			};

			psm_reset_domain@0 {
				compatible = "qemu,reset-domain";
				mr0 = <0x6d>;
				mr1 = <0x0d>;
				reset-gpios = <0x3e 0x07>;
			};
		};

		amba_xram@0 {
			#address-cells = <0x02>;
			#size-cells = <0x02>;
			#priority-cells = <0x01>;
			compatible = "simple-bus";
			ranges;
			phandle = <0x0b>;

			xram_ctrl_0 {
				compatible = "xlnx,versal-xramc";
				reg = <0x00 0xff8e0000 0x00 0x10000 0x00>;
				interrupts = <0x4f>;
				alloc-ram = <0x00>;
			};

			xram_ctrl_1 {
				compatible = "xlnx,versal-xramc";
				reg = <0x00 0xff8f0000 0x00 0x10000 0x00>;
				interrupts = <0x4f>;
				alloc-ram = <0x00>;
			};

			xram_ctrl_2 {
				compatible = "xlnx,versal-xramc";
				reg = <0x00 0xff900000 0x00 0x10000 0x00>;
				interrupts = <0x4f>;
				alloc-ram = <0x00>;
			};

			xram_ctrl_3 {
				compatible = "xlnx,versal-xramc";
				reg = <0x00 0xff910000 0x00 0x10000 0x00>;
				interrupts = <0x4f>;
				alloc-ram = <0x00>;
			};
		};

		crf@0xfd1a0000 {
			compatible = "xlnx,versal-crf";
			reg-extended = <0x07 0x00 0xfd1a0000 0x00 0x140000 0x00>;
			gpio-controller;
			#gpio-cells = <0x01>;
			phandle = <0x2f>;
		};
	};

	lmb_pmc_ppu0@0 {
		#address-cells = <0x02>;
		#size-cells = <0x02>;
		#priority-cells = <0x01>;
		compatible = "simple-bus";
		ranges;
		doc-name = "LMB PPU0";
		doc-status = "complete";
		phandle = <0x59>;

		main_bus_for_pmc {
			compatible = "qemu:memory-region";
			alias = <0x3c>;
			reg = <0x00 0x00 0xffffffff 0xffffffff 0x00>;
		};

		pmc_rom@0xf0000000 {
			reg = <0x00 0xf0000000 0x00 0x20000 0x01>;
			compatible = "qemu:memory-region";
			container = <0x59>;
			qemu,ram = <0x01>;
			read-only;
			phandle = <0xfb>;
		};

		ppu0_ram@0xf0060000 {
			reg = <0x00 0xf0060000 0x00 0x8000 0x01>;
			compatible = "qemu:memory-region";
			container = <0x59>;
			qemu,ram = <0x01>;
			phandle = <0xfc>;
		};

		io-module@00 {
			doc-status = "complete";
			#address-cells = <0x02>;
			#size-cells = <0x01>;
			#priority-cells = <0x00>;
			compatible = "xlnx,iomodule-1.02.a\0syscon\0simple-bus";
			container = <0x59>;
			priority = <0xffffffff>;
			xlnx,freq = <0x47868c0>;
			xlnx,instance = "iomodule_1";
			xlnx,io-mask = <0xfffe0000>;
			xlnx,lmb-awidth = <0x20>;
			xlnx,lmb-dwidth = <0x20>;
			xlnx,mask = <0xffffff80>;
			xlnx,use-io-bus = <0x01>;
			phandle = <0xfd>;

			pmc_ppu0_intc@0C {
				#interrupt-cells = <0x01>;
				compatible = "xlnx,io-intc-1.02.a\0xlnx,io_intc";
				interrupt-controller;
				interrupts-extended = <0x6e 0x00>;
				reg = <0x00 0xf008000c 0x04 0x00 0xf0080030 0x10 0x00
				       0xf0080080 0x7c>;
				xlnx,intc-addr-width = <0x20>;
				xlnx,intc-base-vectors = <0x00>;
				xlnx,intc-has-fast = <0x00>;
				xlnx,intc-intr-size = <0x10>;
				xlnx,intc-level-edge = <0x00>;
				xlnx,intc-positive = <0xffff>;
				xlnx,intc-use-ext-intr = <0x01>;
				phandle = <0x46>;
			};

			pmc_ppu0_gpi@20 {
				#gpio-cells = <0x01>;
				gpio-controller;
				compatible = "xlnx,io-gpi-1.02.a\0xlnx,io_gpi";
				interrupt-parent = <0x46>;
				interrupts = <0x0b>;
				reg = <0x00 0xf0080020 0x04>;
				xlnx,gpi-interrupt = <0x01>;
				xlnx,gpi-size = <0x20>;
				xlnx,use-gpi = <0x01>;
				phandle = <0xfe>;
			};

			pmc_ppu0_gpi@24 {
				#gpio-cells = <0x01>;
				gpio-controller;
				compatible = "xlnx,io-gpi-1.02.a\0xlnx,io_gpi";
				interrupt-parent = <0x46>;
				interrupts = <0x0c>;
				reg = <0x00 0xf0080024 0x04>;
				xlnx,gpi-interrupt = <0x01>;
				xlnx,gpi-size = <0x20>;
				xlnx,use-gpi = <0x01>;
				phandle = <0xff>;
			};

			pmc_ppu0_gpi@28 {
				#gpio-cells = <0x01>;
				gpio-controller;
				compatible = "xlnx,io-gpi-1.02.a\0xlnx,io_gpi";
				interrupt-parent = <0x46>;
				interrupts = <0x0d>;
				reg = <0x00 0xf0080028 0x04>;
				xlnx,gpi-interrupt = <0x01>;
				xlnx,gpi-size = <0x20>;
				xlnx,use-gpi = <0x01>;
				phandle = <0x100>;
			};

			pmc_ppu0_gpi@2c {
				#gpio-cells = <0x01>;
				gpio-controller;
				compatible = "xlnx,io-gpi-1.02.a\0xlnx,io_gpi";
				interrupt-parent = <0x46>;
				interrupts = <0x0e>;
				reg = <0x00 0xf008002c 0x04>;
				xlnx,gpi-interrupt = <0x01>;
				xlnx,gpi-size = <0x20>;
				xlnx,use-gpi = <0x01>;
				phandle = <0x101>;
			};

			pmc_ppu0_gpo@10 {
				#gpio-cells = <0x01>;
				gpio-controller;
				compatible = "xlnx,io-gpo-1.02.a\0xlnx,io_gpo";
				reg = <0x00 0xf0080010 0x04>;
				xlnx,gpo-init = <0x00>;
				xlnx,gpo-size = <0x09>;
				xlnx,use-gpo = <0x01>;
				phandle = <0x6f>;
			};

			pmc_ppu0_gpo@14 {
				#gpio-cells = <0x01>;
				gpio-controller;
				compatible = "xlnx,io-gpo-1.02.a\0xlnx,io_gpo";
				reg = <0x00 0xf0080014 0x04>;
				xlnx,gpo-init = <0x00>;
				xlnx,gpo-size = <0x20>;
				xlnx,use-gpo = <0x01>;
				phandle = <0x102>;
			};

			pmc_ppu0_gpo@18 {
				#gpio-cells = <0x01>;
				gpio-controller;
				compatible = "xlnx,io-gpo-1.02.a\0xlnx,io_gpo";
				reg = <0x00 0xf0080018 0x04>;
				xlnx,gpo-init = <0x00>;
				xlnx,gpo-size = <0x20>;
				xlnx,use-gpo = <0x01>;
				phandle = <0x103>;
			};

			pmc_ppu0_gpo@1c {
				#gpio-cells = <0x01>;
				gpio-controller;
				compatible = "xlnx,io-gpo-1.02.a\0xlnx,io_gpo";
				reg = <0x00 0xf008001c 0x04>;
				xlnx,gpo-init = <0x00>;
				xlnx,gpo-size = <0x20>;
				xlnx,use-gpo = <0x01>;
				phandle = <0x104>;
			};

			pmc_ppu0_pit@40 {
				compatible = "xlnx,io-pit-1.02.a\0xlnx,io_pit";
				interrupt-parent = <0x46>;
				interrupts = <0x03>;
				reg = <0x00 0xf0080040 0x0c>;
				xlnx,pit-interrupt = <0x01>;
				xlnx,pit-prescaler = <0x09>;
				xlnx,pit-readable = <0x01>;
				xlnx,pit-size = <0x20>;
				xlnx,use-pit = <0x01>;
				frequency = <0x1b6b0b00>;
				gpios = <0x6f 0x01 0x70 0x00>;
				gpio-names = "ps_config\0ps_hit_in";
				gpio-controller;
				#gpio-cells = <0x01>;
				phandle = <0x105>;
			};

			pmc_ppu0_pit@50 {
				compatible = "xlnx,io-pit-1.02.a\0xlnx,io_pit";
				interrupt-parent = <0x46>;
				interrupts = <0x04>;
				reg = <0x00 0xf0080050 0x0c>;
				xlnx,pit-interrupt = <0x01>;
				xlnx,pit-prescaler = <0x09>;
				xlnx,pit-readable = <0x01>;
				xlnx,pit-size = <0x20>;
				xlnx,use-pit = <0x01>;
				frequency = <0x1b6b0b00>;
				gpio-controller;
				#gpio-cells = <0x01>;
				phandle = <0x70>;
			};

			pmc_ppu0_pit@60 {
				compatible = "xlnx,io-pit-1.02.a\0xlnx,io_pit";
				interrupt-parent = <0x46>;
				interrupts = <0x05>;
				reg = <0x00 0xf0080060 0x0c>;
				xlnx,pit-interrupt = <0x01>;
				xlnx,pit-prescaler = <0x09>;
				xlnx,pit-readable = <0x01>;
				xlnx,pit-size = <0x20>;
				xlnx,use-pit = <0x01>;
				frequency = <0x1b6b0b00>;
				gpios = <0x6f 0x06 0x71 0x00>;
				gpio-names = "ps_config\0ps_hit_in";
				gpio-controller;
				#gpio-cells = <0x01>;
				phandle = <0x106>;
			};

			pmc_ppu0_pit@70 {
				compatible = "xlnx,io-pit-1.02.a\0xlnx,io_pit";
				interrupt-parent = <0x46>;
				interrupts = <0x06>;
				reg = <0x00 0xf0080070 0x0c>;
				xlnx,pit-interrupt = <0x01>;
				xlnx,pit-prescaler = <0x09>;
				xlnx,pit-readable = <0x01>;
				xlnx,pit-size = <0x20>;
				xlnx,use-pit = <0x01>;
				frequency = <0x1b6b0b00>;
				gpio-controller;
				#gpio-cells = <0x01>;
				phandle = <0x71>;
			};
		};
	};

	lmb_pmc_ppu1@0 {
		#address-cells = <0x02>;
		#size-cells = <0x02>;
		#priority-cells = <0x01>;
		compatible = "simple-bus";
		ranges;
		doc-name = "LMB PPU1";
		doc-status = "complete";
		phandle = <0x72>;

		main_bus_for_pmc {
			compatible = "qemu:memory-region";
			alias = <0x3c>;
			reg = <0x00 0x00 0xffffffff 0xffffffff 0x00>;
		};

		io-module@00 {
			doc-status = "complete";
			#address-cells = <0x02>;
			#size-cells = <0x01>;
			#priority-cells = <0x00>;
			compatible = "xlnx,iomodule-1.02.a\0syscon\0simple-bus";
			container = <0x72>;
			priority = <0xffffffff>;
			xlnx,freq = <0x47868c0>;
			xlnx,instance = "iomodule_1";
			xlnx,io-mask = <0xfffe0000>;
			xlnx,lmb-awidth = <0x20>;
			xlnx,lmb-dwidth = <0x20>;
			xlnx,mask = <0xffffff80>;
			xlnx,use-io-bus = <0x01>;
			phandle = <0x107>;

			pmc_ppu1_intc@0C {
				#interrupt-cells = <0x01>;
				compatible = "xlnx,io-intc-1.02.a\0xlnx,io_intc";
				interrupt-controller;
				interrupts-extended = <0x73 0x00>;
				reg = <0x00 0xf028000c 0x04 0x00 0xf0280030 0x10 0x00
				       0xf0280080 0x7c>;
				xlnx,intc-addr-width = <0x20>;
				xlnx,intc-base-vectors = <0x00>;
				xlnx,intc-has-fast = <0x00>;
				xlnx,intc-intr-size = <0x10>;
				xlnx,intc-level-edge = <0x00>;
				xlnx,intc-positive = <0xffff>;
				xlnx,intc-use-ext-intr = <0x01>;
				phandle = <0x51>;
			};

			pmc_ppu1_gpi@20 {
				#gpio-cells = <0x01>;
				gpio-controller;
				compatible = "xlnx,io-gpi-1.02.a\0xlnx,io_gpi";
				interrupt-parent = <0x51>;
				interrupts = <0x0b>;
				reg = <0x00 0xf0280020 0x04>;
				xlnx,gpi-interrupt = <0x01>;
				xlnx,gpi-size = <0x20>;
				xlnx,use-gpi = <0x01>;
				phandle = <0x108>;
			};

			pmc_ppu1_gpi@24 {
				#gpio-cells = <0x01>;
				gpio-controller;
				compatible = "xlnx,io-gpi-1.02.a\0xlnx,io_gpi";
				interrupt-parent = <0x51>;
				interrupts = <0x0c>;
				reg = <0x00 0xf0280024 0x04>;
				xlnx,gpi-interrupt = <0x01>;
				xlnx,gpi-size = <0x20>;
				xlnx,use-gpi = <0x01>;
				phandle = <0x109>;
			};

			pmc_ppu1_gpi@28 {
				#gpio-cells = <0x01>;
				gpio-controller;
				compatible = "xlnx,io-gpi-1.02.a\0xlnx,io_gpi";
				interrupt-parent = <0x51>;
				interrupts = <0x0d>;
				reg = <0x00 0xf0280028 0x04>;
				xlnx,gpi-interrupt = <0x01>;
				xlnx,gpi-size = <0x20>;
				xlnx,use-gpi = <0x01>;
				phandle = <0x10a>;
			};

			pmc_ppu1_gpi@2c {
				#gpio-cells = <0x01>;
				gpio-controller;
				compatible = "xlnx,io-gpi-1.02.a\0xlnx,io_gpi";
				interrupt-parent = <0x51>;
				interrupts = <0x0e>;
				reg = <0x00 0xf028002c 0x04>;
				xlnx,gpi-interrupt = <0x01>;
				xlnx,gpi-size = <0x20>;
				xlnx,use-gpi = <0x01>;
				phandle = <0x10b>;
			};

			pmc_ppu1_gpo@10 {
				#gpio-cells = <0x01>;
				gpio-controller;
				compatible = "xlnx,io-gpo-1.02.a\0xlnx,io_gpo";
				reg = <0x00 0xf0280010 0x04>;
				xlnx,gpo-init = <0x00>;
				xlnx,gpo-size = <0x09>;
				xlnx,use-gpo = <0x01>;
				phandle = <0x74>;
			};

			pmc_ppu1_gpo@14 {
				#gpio-cells = <0x01>;
				gpio-controller;
				compatible = "xlnx,io-gpo-1.02.a\0xlnx,io_gpo";
				reg = <0x00 0xf0280014 0x04>;
				xlnx,gpo-init = <0x00>;
				xlnx,gpo-size = <0x20>;
				xlnx,use-gpo = <0x01>;
				phandle = <0x10c>;
			};

			pmc_ppu1_gpo@18 {
				#gpio-cells = <0x01>;
				gpio-controller;
				compatible = "xlnx,io-gpo-1.02.a\0xlnx,io_gpo";
				reg = <0x00 0xf0280018 0x04>;
				xlnx,gpo-init = <0x00>;
				xlnx,gpo-size = <0x20>;
				xlnx,use-gpo = <0x01>;
				phandle = <0x10d>;
			};

			pmc_ppu1_gpo@1c {
				#gpio-cells = <0x01>;
				gpio-controller;
				compatible = "xlnx,io-gpo-1.02.a\0xlnx,io_gpo";
				reg = <0x00 0xf028001c 0x04>;
				xlnx,gpo-init = <0x00>;
				xlnx,gpo-size = <0x20>;
				xlnx,use-gpo = <0x01>;
				phandle = <0x10e>;
			};

			pmc_ppu1_pit@40 {
				compatible = "xlnx,io-pit-1.02.a\0xlnx,io_pit";
				interrupt-parent = <0x51>;
				interrupts = <0x03>;
				reg = <0x00 0xf0280040 0x0c>;
				xlnx,pit-interrupt = <0x01>;
				xlnx,pit-prescaler = <0x09>;
				xlnx,pit-readable = <0x01>;
				xlnx,pit-size = <0x20>;
				xlnx,use-pit = <0x01>;
				frequency = <0x5f5e100>;
				gpios = <0x74 0x01 0x75 0x00>;
				gpio-names = "ps_config\0ps_hit_in";
				gpio-controller;
				#gpio-cells = <0x01>;
				phandle = <0x10f>;
			};

			pmc_ppu1_pit@50 {
				compatible = "xlnx,io-pit-1.02.a\0xlnx,io_pit";
				interrupt-parent = <0x51>;
				interrupts = <0x04>;
				reg = <0x00 0xf0280050 0x0c>;
				xlnx,pit-interrupt = <0x01>;
				xlnx,pit-prescaler = <0x09>;
				xlnx,pit-readable = <0x01>;
				xlnx,pit-size = <0x20>;
				xlnx,use-pit = <0x01>;
				frequency = <0x5f5e100>;
				gpio-controller;
				#gpio-cells = <0x01>;
				phandle = <0x75>;
			};

			pmc_ppu1_pit@60 {
				compatible = "xlnx,io-pit-1.02.a\0xlnx,io_pit";
				interrupt-parent = <0x51>;
				interrupts = <0x05>;
				reg = <0x00 0xf0280060 0x0c>;
				xlnx,pit-interrupt = <0x01>;
				xlnx,pit-prescaler = <0x09>;
				xlnx,pit-readable = <0x01>;
				xlnx,pit-size = <0x20>;
				xlnx,use-pit = <0x01>;
				frequency = <0x5f5e100>;
				gpios = <0x74 0x06 0x76 0x00>;
				gpio-names = "ps_config\0ps_hit_in";
				gpio-controller;
				#gpio-cells = <0x01>;
				windows-frequency = <0x13d620>;
				phandle = <0x110>;
			};

			pmc_ppu1_pit@70 {
				compatible = "xlnx,io-pit-1.02.a\0xlnx,io_pit";
				interrupt-parent = <0x51>;
				interrupts = <0x06>;
				reg = <0x00 0xf0280070 0x0c>;
				xlnx,pit-interrupt = <0x01>;
				xlnx,pit-prescaler = <0x09>;
				xlnx,pit-readable = <0x01>;
				xlnx,pit-size = <0x20>;
				xlnx,use-pit = <0x01>;
				frequency = <0x5f5e100>;
				gpio-controller;
				#gpio-cells = <0x01>;
				phandle = <0x76>;
			};
		};
	};

	lmb_psm@0 {
		#address-cells = <0x02>;
		#size-cells = <0x02>;
		#priority-cells = <0x01>;
		compatible = "simple-bus";
		ranges;
		doc-name = "LMB PPU0";
		doc-status = "in-progress";
		phandle = <0x6d>;

		downstream_amba {
			compatible = "qemu:memory-region";
			alias = <0x09>;
			reg = <0x00 0x00 0xffffffff 0xffffffff 0xffffffff>;
		};

		main_bus_for_pmc {
			compatible = "qemu:memory-region";
			alias = <0x0d>;
			reg = <0x00 0x00 0xffffffff 0xffffffff 0x00>;
		};

		io-module@00 {
			doc-status = "complete";
			#address-cells = <0x02>;
			#size-cells = <0x01>;
			#priority-cells = <0x00>;
			compatible = "simple-bus";
			priority = <0xffffffff>;
			container = <0x6d>;
			phandle = <0x111>;

			psm0_intc@0C {
				#interrupt-cells = <0x01>;
				compatible = "xlnx,io-intc-1.02.a\0xlnx,io_intc";
				interrupt-controller;
				interrupts-extended = <0x6e 0x00>;
				reg = <0x00 0xffc8000c 0x04 0x00 0xffc80030 0x10 0x00
				       0xffc80080 0x7c>;
				xlnx,intc-addr-width = <0x20>;
				xlnx,intc-base-vectors = <0x00>;
				xlnx,intc-has-fast = <0x00>;
				xlnx,intc-intr-size = <0x10>;
				xlnx,intc-level-edge = <0x00>;
				xlnx,intc-positive = <0xffff>;
				xlnx,intc-use-ext-intr = <0x01>;
				phandle = <0x05>;
			};

			psm0_gpo@10 {
				#gpio-cells = <0x01>;
				gpio-controller;
				compatible = "xlnx,io-gpo-1.02.a\0xlnx,io_gpo";
				reg = <0x00 0xffc80010 0x04>;
				xlnx,gpo-init = <0x00>;
				xlnx,gpo-size = <0x03>;
				xlnx,use-gpo = <0x01>;
				phandle = <0x77>;
			};

			psm0_pit@40 {
				compatible = "xlnx,io-pit-1.02.a\0xlnx,io_pit";
				interrupt-parent = <0x05>;
				interrupts = <0x03>;
				reg = <0x00 0xffc80040 0x0c>;
				xlnx,pit-interrupt = <0x01>;
				xlnx,pit-prescaler = <0x09>;
				xlnx,pit-readable = <0x01>;
				xlnx,pit-size = <0x20>;
				xlnx,use-pit = <0x01>;
				frequency = <0x1b6b0b00>;
				gpios = <0x77 0x01 0x78 0x00>;
				gpio-names = "ps_config\0ps_hit_in";
				gpio-controller;
				#gpio-cells = <0x01>;
				phandle = <0x112>;
			};

			psm0_pit@50 {
				compatible = "xlnx,io-pit-1.02.a\0xlnx,io_pit";
				interrupt-parent = <0x05>;
				interrupts = <0x04>;
				reg = <0x00 0xffc80050 0x0c>;
				xlnx,pit-interrupt = <0x01>;
				xlnx,pit-prescaler = <0x09>;
				xlnx,pit-readable = <0x01>;
				xlnx,pit-size = <0x20>;
				xlnx,use-pit = <0x01>;
				frequency = <0x1b6b0b00>;
				gpio-controller;
				#gpio-cells = <0x01>;
				phandle = <0x78>;
			};

			psm0_pit@60 {
				compatible = "xlnx,io-pit-1.02.a\0xlnx,io_pit";
				interrupt-parent = <0x05>;
				interrupts = <0x05>;
				reg = <0x00 0xffc80060 0x0c>;
				xlnx,pit-interrupt = <0x01>;
				xlnx,pit-prescaler = <0x09>;
				xlnx,pit-readable = <0x01>;
				xlnx,pit-size = <0x20>;
				xlnx,use-pit = <0x01>;
				frequency = <0x1b6b0b00>;
				gpios = <0x77 0x06 0x79 0x00>;
				gpio-names = "ps_config\0ps_hit_in";
				gpio-controller;
				#gpio-cells = <0x01>;
				phandle = <0x113>;
			};

			psm0_pit@70 {
				compatible = "xlnx,io-pit-1.02.a\0xlnx,io_pit";
				interrupt-parent = <0x05>;
				interrupts = <0x06>;
				reg = <0x00 0xffc80070 0x0c>;
				xlnx,pit-interrupt = <0x01>;
				xlnx,pit-prescaler = <0x09>;
				xlnx,pit-readable = <0x01>;
				xlnx,pit-size = <0x20>;
				xlnx,use-pit = <0x01>;
				frequency = <0x1b6b0b00>;
				gpio-controller;
				#gpio-cells = <0x01>;
				phandle = <0x79>;
			};
		};

		psm_local_reg@0xffc88000 {
			gpio-controller;
			#gpio-cells = <0x01>;
			compatible = "xlnx,psm-local-reg";
			reg = <0x00 0xffc88000 0x00 0x8000 0x00>;
			gpios = <0x7a 0x00 0x7a 0x01 0x7a 0x02 0x7a 0x03>;
			phandle = <0x1a>;
		};
	};

	lmb_ddrmc@0 {
		#address-cells = <0x02>;
		#size-cells = <0x02>;
		#priority-cells = <0x01>;
		compatible = "simple-bus";
		ranges;
		doc-name = "LMB DDRMC0";
		doc-status = "partial";
		phandle = <0x7b>;

		ddrmc0_ram_data@0x1c000 {
			reg = <0x00 0x1c000 0x00 0x4000 0x01>;
			compatible = "qemu:memory-region";
			qemu,ram = <0x01>;
			phandle = <0x114>;
		};

		ddrmc0_ram_instr@0x20000 {
			reg = <0x00 0x20000 0x00 0x20000 0x01>;
			compatible = "qemu:memory-region";
			qemu,ram = <0x01>;
			phandle = <0x115>;
		};

		ddrmc0_ram_exchange@0x08000 {
			reg = <0x00 0x8000 0x00 0x8000 0x01>;
			compatible = "qemu:memory-region";
			qemu,ram = <0x01>;
			phandle = <0x116>;
		};

		io-module@00 {
			doc-status = "complete";
			#address-cells = <0x02>;
			#size-cells = <0x01>;
			#priority-cells = <0x00>;
			compatible = "simple-bus";
			container = <0x7b>;
			priority = <0xffffffff>;
			phandle = <0x117>;

			ddrmc0_intc@0C {
				#interrupt-cells = <0x01>;
				compatible = "xlnx,io-intc-1.02.a\0xlnx,io_intc";
				interrupt-controller;
				interrupts-extended = <0x7c 0x00>;
				reg = <0x00 0x1b00c 0x04 0x00 0x1b030 0x10 0x00 0x1b080 0x7c>;
				xlnx,intc-addr-width = <0x20>;
				xlnx,intc-base-vectors = <0x00>;
				xlnx,intc-has-fast = <0x00>;
				xlnx,intc-intr-size = <0x10>;
				xlnx,intc-level-edge = <0x00>;
				xlnx,intc-positive = <0xffff>;
				xlnx,intc-use-ext-intr = <0x01>;
				phandle = <0x7d>;
			};

			ddrmc0_gpo@10 {
				#gpio-cells = <0x01>;
				gpio-controller;
				compatible = "xlnx,io-gpo-1.02.a\0xlnx,io_gpo";
				reg = <0x00 0x1b010 0x04>;
				xlnx,gpo-init = <0x00>;
				xlnx,gpo-size = <0x03>;
				xlnx,use-gpo = <0x01>;
				phandle = <0x7e>;
			};

			ddrmc0_pit@40 {
				compatible = "xlnx,io-pit-1.02.a\0xlnx,io_pit";
				interrupt-parent = <0x7d>;
				interrupts = <0x03>;
				reg = <0x00 0x1b040 0x0c>;
				xlnx,pit-interrupt = <0x01>;
				xlnx,pit-prescaler = <0x09>;
				xlnx,pit-readable = <0x01>;
				xlnx,pit-size = <0x20>;
				xlnx,use-pit = <0x01>;
				frequency = <0x1b6b0b00>;
				gpios = <0x7e 0x01 0x7f 0x00>;
				gpio-names = "ps_config\0ps_hit_in";
				gpio-controller;
				#gpio-cells = <0x01>;
				phandle = <0x118>;
			};

			ddrmc0_pit@50 {
				compatible = "xlnx,io-pit-1.02.a\0xlnx,io_pit";
				interrupt-parent = <0x7d>;
				interrupts = <0x04>;
				reg = <0x00 0x1b050 0x0c>;
				xlnx,pit-interrupt = <0x01>;
				xlnx,pit-prescaler = <0x09>;
				xlnx,pit-readable = <0x01>;
				xlnx,pit-size = <0x20>;
				xlnx,use-pit = <0x01>;
				frequency = <0x1b6b0b00>;
				gpio-controller;
				#gpio-cells = <0x01>;
				phandle = <0x7f>;
			};

			ddrmc0_pit@60 {
				compatible = "xlnx,io-pit-1.02.a\0xlnx,io_pit";
				interrupt-parent = <0x7d>;
				interrupts = <0x05>;
				reg = <0x00 0x1b060 0x0c>;
				xlnx,pit-interrupt = <0x01>;
				xlnx,pit-prescaler = <0x09>;
				xlnx,pit-readable = <0x01>;
				xlnx,pit-size = <0x20>;
				xlnx,use-pit = <0x01>;
				frequency = <0x1b6b0b00>;
				gpios = <0x7e 0x06 0x80 0x00>;
				gpio-names = "ps_config\0ps_hit_in";
				gpio-controller;
				#gpio-cells = <0x01>;
				phandle = <0x119>;
			};

			ddrmc0_pit@70 {
				compatible = "xlnx,io-pit-1.02.a\0xlnx,io_pit";
				interrupt-parent = <0x7d>;
				interrupts = <0x06>;
				reg = <0x00 0x1b070 0x0c>;
				xlnx,pit-interrupt = <0x01>;
				xlnx,pit-prescaler = <0x09>;
				xlnx,pit-readable = <0x01>;
				xlnx,pit-size = <0x20>;
				xlnx,use-pit = <0x01>;
				frequency = <0x1b6b0b00>;
				gpio-controller;
				#gpio-cells = <0x01>;
				phandle = <0x80>;
			};
		};

		ddrmc_uart0@0 {
			compatible = "xlnx,io_uart";
			reg = <0x00 0x1b000 0x0c 0x1b04c 0x04>;
			xlnx,use-uart-rx = <0x01>;
			xlnx,use-uart-tx = <0x01>;
			chardev = "ddrmc-uart0\0serial1";
			phandle = <0x11a>;
		};

		alias_npi_ddrmc_main {
			compatible = "qemu:memory-region";
			alias = <0x81>;
			reg = <0x00 0x00 0x00 0x8000 0x00>;
		};
	};

	lmb_ddrmc@1 {
		#address-cells = <0x02>;
		#size-cells = <0x02>;
		#priority-cells = <0x01>;
		compatible = "simple-bus";
		ranges;
		phandle = <0x11b>;

		ddrmc1_ram_data@0x1c000 {
			reg = <0x00 0x1c000 0x00 0x4000 0x01>;
			compatible = "qemu:memory-region";
			qemu,ram = <0x01>;
			phandle = <0x11c>;
		};

		ddrmc1_ram_instr@0x20000 {
			reg = <0x00 0x20000 0x00 0x20000 0x01>;
			compatible = "qemu:memory-region";
			qemu,ram = <0x01>;
			phandle = <0x11d>;
		};

		ddrmc1_ram_exchange@0x08000 {
			reg = <0x00 0x8000 0x00 0x8000 0x01>;
			compatible = "qemu:memory-region";
			qemu,ram = <0x01>;
			phandle = <0x11e>;
		};
	};

	amba_rpu@0 {
		#address-cells = <0x02>;
		#size-cells = <0x02>;
		#priority-cells = <0x01>;
		compatible = "simple-bus";
		ranges;
		phandle = <0x82>;

		downstream_amba {
			compatible = "qemu:memory-region";
			alias = <0x09>;
			reg = <0x00 0x00 0xffffffff 0xffffffff 0xffffffff>;
		};

		interrupt-controller@0xf9000000 {
			#address-cells = <0x00>;
			#interrupt-cells = <0x03>;
			#size-cells = <0x00>;
			compatible = "arm,gic";
			reg = <0x00 0xf9000000 0x00 0x1000 0x00 0x00 0xf9001000 0x00 0x1000
			       0x00>;
			status = "disabled";
			interrupt-controller;
			num-irq = <0x100>;
			num-cpu = <0x02>;
			interrupts-extended = <0x21 0x00 0x22 0x00>;
			phandle = <0x02>;
		};
	};

	amba_r5@0 {
		#address-cells = <0x02>;
		#size-cells = <0x02>;
		#priority-cells = <0x01>;
		compatible = "simple-bus";
		ranges;
		phandle = <0x1f>;

		downstream_amba {
			compatible = "qemu:memory-region";
			alias = <0x82>;
			reg = <0x00 0x00 0xffffffff 0xffffffff 0x00>;
		};
	};

	amba_r5@1 {
		#address-cells = <0x02>;
		#size-cells = <0x02>;
		#priority-cells = <0x01>;
		compatible = "simple-bus";
		ranges;
		phandle = <0x20>;

		downstream_amba {
			compatible = "qemu:memory-region";
			alias = <0x82>;
			reg = <0x00 0x00 0xffffffff 0xffffffff 0x00>;
		};
	};

	dummy1@0 {
		doc-ignore = <0x01>;
		interrupt-controller;
		#interrupt-cells = <0x01>;
		gpio-controller;
		#gpio-cells = <0x01>;
		phandle = <0x52>;
	};

	tbu0_slave@0 {
		#address-cells = <0x02>;
		#size-cells = <0x02>;
		#priority-cells = <0x01>;
		compatible = "simple-bus";
		ranges;
		phandle = <0x0e>;
	};

	tbu1_slave@0 {
		#address-cells = <0x02>;
		#size-cells = <0x02>;
		#priority-cells = <0x01>;
		compatible = "simple-bus";
		ranges;
		phandle = <0x0f>;
	};

	tbu2_slave@0 {
		#address-cells = <0x02>;
		#size-cells = <0x02>;
		#priority-cells = <0x01>;
		compatible = "simple-bus";
		ranges;
		phandle = <0x10>;
	};

	tbu3_slave@0 {
		#address-cells = <0x02>;
		#size-cells = <0x02>;
		#priority-cells = <0x01>;
		compatible = "simple-bus";
		ranges;
		phandle = <0x11>;
	};

	tbu4_slave@0 {
		#address-cells = <0x02>;
		#size-cells = <0x02>;
		#priority-cells = <0x01>;
		compatible = "simple-bus";
		ranges;
		phandle = <0x12>;
	};

	tbu5_slave@0 {
		#address-cells = <0x02>;
		#size-cells = <0x02>;
		#priority-cells = <0x01>;
		compatible = "simple-bus";
		ranges;
		phandle = <0x13>;
	};

	tbu6_slave@0 {
		#address-cells = <0x02>;
		#size-cells = <0x02>;
		#priority-cells = <0x01>;
		compatible = "simple-bus";
		ranges;
		phandle = <0x14>;
	};

	memory@00000000 {
		compatible = "qemu:memory-region";
		device_type = "memory";
		container = <0x09>;
		phandle = <0x8b>;
	};

	memory@8_0000_0000 {
		compatible = "qemu:memory-region";
		device_type = "memory";
		container = <0x09>;
		phandle = <0x8c>;
	};

	memory@0x50000000000ULL {
		compatible = "qemu:memory-region";
		device_type = "memory";
		container = <0x09>;
		phandle = <0x8d>;
	};

	ocm_mem@0xfffc0000 {
		compatible = "qemu:memory-region";
		phandle = <0x0a>;
	};

	ocm_mem_bank_0@ {
		compatible = "qemu:memory-region";
		container = <0x0a>;
		qemu,ram = <0x01>;
		reg = <0x00 0x00 0x00 0x10000 0x00>;
		phandle = <0x11f>;
	};

	ocm_mem_bank_1@ {
		compatible = "qemu:memory-region";
		container = <0x0a>;
		qemu,ram = <0x01>;
		reg = <0x00 0x10000 0x00 0x10000 0x00>;
		phandle = <0x120>;
	};

	ocm_mem_bank_2@ {
		compatible = "qemu:memory-region";
		container = <0x0a>;
		qemu,ram = <0x01>;
		reg = <0x00 0x20000 0x00 0x10000 0x00>;
		phandle = <0x121>;
	};

	ocm_mem_bank_3@ {
		compatible = "qemu:memory-region";
		container = <0x0a>;
		qemu,ram = <0x01>;
		reg = <0x00 0x30000 0x00 0x10000 0x00>;
		phandle = <0x122>;
	};

	xram_mem@0xfe800000 {
		compatible = "qemu:memory-region";
		phandle = <0x0c>;
	};

	xram_mem_bank_0@0x0 {
		compatible = "qemu:memory-region";
		container = <0x0c>;
		qemu,ram = <0x01>;
		reg = <0x00 0x00 0x00 0x200000 0x00>;
		phandle = <0x123>;
	};

	xram_mem_bank_1@0x200000 {
		compatible = "qemu:memory-region";
		container = <0x0c>;
		qemu,ram = <0x01>;
		reg = <0x00 0x200000 0x00 0x200000 0x00>;
		phandle = <0x124>;
	};

	xram_mem_bank_2@0x400000 {
		compatible = "qemu:memory-region";
		container = <0x0c>;
		qemu,ram = <0x01>;
		reg = <0x00 0x400000 0x00 0x200000 0x00>;
		phandle = <0x125>;
	};

	xram_mem_bank_3@0x600000 {
		compatible = "qemu:memory-region";
		container = <0x0c>;
		qemu,ram = <0x01>;
		reg = <0x00 0x600000 0x00 0x200000 0x00>;
		phandle = <0x126>;
	};

	ipi_msgbuf@0 {
		compatible = "qemu:memory-region";
		device_type = "memory";
		container = <0x06>;
		qemu,ram = <0x01>;
		reg = <0x00 0xff3f0000 0x00 0x1000 0x00>;
		phandle = <0x127>;
	};

	pmc_ram@0xf2000000 {
		compatible = "qemu:memory-region";
		phandle = <0x35>;
	};

	pmc_ram_bank_0@0x0 {
		compatible = "qemu:memory-region";
		container = <0x35>;
		qemu,ram = <0x01>;
		reg = <0x00 0x00 0x00 0x20000 0x00>;
		phandle = <0x128>;
	};

	pmc_ppu1_ram@0xf0200000 {
		compatible = "qemu:memory-region";
		container = <0x09>;
		qemu,ram = <0x01>;
		reg = <0x00 0xf0200000 0x00 0x40000 0x00>;
		phandle = <0x129>;
	};

	pmc_ppu1_ram@0xf0240000 {
		compatible = "qemu:memory-region";
		container = <0x09>;
		qemu,ram = <0x01>;
		reg = <0x00 0xf0240000 0x00 0x20000 0x00>;
		phandle = <0x12a>;
	};

	ppu0_mdm_uart@0xf0110000 {
		doc-status = "complete";
		compatible = "xlnx,xps-uartlite";
		reg-extended = <0x59 0x00 0xf0110000 0x00 0x10 0x01>;
		chardev = "serial0";
	};

	ppu1_mdm_uart@0xf0310000 {
		doc-status = "complete";
		compatible = "xlnx,xps-uartlite";
		reg-extended = <0x72 0x00 0xf0310000 0x00 0x10 0x01>;
		chardev = "serial1";
	};

	lqspi_mr@0 {
		#address-cells = <0x02>;
		#size-cells = <0x02>;
		#priority-cells = <0x01>;
		compatible = "simple-bus";
		ranges;
		phandle = <0x40>;
	};

	lospi_mr@0 {
		#address-cells = <0x02>;
		#size-cells = <0x02>;
		#priority-cells = <0x01>;
		compatible = "simple-bus";
		ranges;
		phandle = <0x42>;
	};

	cpus {
		#address-cells = <0x01>;
		#size-cells = <0x00>;

		apu_cpu@0 {
			compatible = "cortex-a72-arm-cpu";
			device_type = "cpu";
			arm,ccsidr0 = <0x701fe00a>;
			arm,ccsidr1 = <0x201fe012>;
			reg = <0x00>;
			core-count = <0x02>;
			arm,reset-hivecs = <0x01>;
			arm,rvbar = <0xffff0000>;
			arm,reset-cbar = <0xf9040000>;
			mr = <0x83>;
			memory = <0x83>;
			qemu,halt = <0x01>;
			gpios = <0x1a 0x18>;
			gpio-names = "wfi";
			reset-gpios = <0x2f 0x00>;
			power-gpios = <0x1a 0x00>;
			memattr_s = <0x84>;
			memattr_ns = <0x85>;
			gdb-id = "Cortex-A72 #0";
			#interrupt-cells = <0x01>;
			generic-timer-frequency = <0x5f5e100>;
			phandle = <0x2d>;
		};

		apu_cpu@1 {
			compatible = "cortex-a72-arm-cpu";
			device_type = "cpu";
			arm,ccsidr0 = <0x701fe00a>;
			arm,ccsidr1 = <0x201fe012>;
			reg = <0x01>;
			core-count = <0x02>;
			arm,reset-hivecs = <0x01>;
			arm,rvbar = <0xffff0000>;
			arm,reset-cbar = <0xf9040000>;
			mr = <0x83>;
			memory = <0x83>;
			qemu,halt = <0x01>;
			gpios = <0x1a 0x19>;
			gpio-names = "wfi";
			reset-gpios = <0x2f 0x01>;
			power-gpios = <0x1a 0x04>;
			memattr_s = <0x86>;
			memattr_ns = <0x87>;
			direct-lnx-start-powered-off = <0x01>;
			start-powered-off = <0x00>;
			gdb-id = "Cortex-A72 #1";
			#interrupt-cells = <0x01>;
			generic-timer-frequency = <0x5f5e100>;
			phandle = <0x2e>;
		};

		apu_cpu@2 {
			#interrupt-cells = <0x01>;
			generic-timer-frequency = <0x5f5e100>;
			phandle = <0x12b>;
		};

		apu_cpu@3 {
			#interrupt-cells = <0x01>;
			generic-timer-frequency = <0x5f5e100>;
			phandle = <0x12c>;
		};

		rpu_cpu@0 {
			compatible = "cortex-r5f-arm-cpu";
			device_type = "cpu";
			arm,tcmtr = <0x10001>;
			arm,ctr = <0x8003c003>;
			arm,clidr = <0x9200003>;
			arm,ccsidr0 = <0xf01fe019>;
			arm,ccsidr1 = <0xf01fe019>;
			arm,mp-affinity = <0x100>;
			arm,id_pfr0 = <0x131>;
			arm,reset-hivecs = <0x01>;
			#interrupt-cells = <0x01>;
			memory = <0x1f>;
			qemu,halt = <0x01>;
			memattr_ns = <0x88>;
			gdb-id = "Cortex-R5 #0";
			gpios = <0x19 0x20 0x6c 0x00 0x6c 0x02 0x6c 0x04>;
			gpio-names = "reset\0halt\0wfi\0vinithi";
			phandle = <0x21>;
		};

		rpu_cpu@1 {
			compatible = "cortex-r5f-arm-cpu";
			device_type = "cpu";
			arm,tcmtr = <0x10001>;
			arm,ctr = <0x8003c003>;
			arm,clidr = <0x9200003>;
			arm,ccsidr0 = <0xf01fe019>;
			arm,ccsidr1 = <0xf01fe019>;
			arm,mp-affinity = <0x101>;
			arm,id_pfr0 = <0x131>;
			arm,reset-hivecs = <0x01>;
			#interrupt-cells = <0x01>;
			memory = <0x20>;
			qemu,halt = <0x01>;
			memattr_ns = <0x89>;
			gdb-id = "Cortex-R5 #1";
			gpios = <0x19 0x21 0x6c 0x01 0x6c 0x03 0x6c 0x05>;
			gpio-names = "reset\0halt\0wfi\0vinithi";
			phandle = <0x22>;
		};
	};

	amba_apu@0 {
		#address-cells = <0x02>;
		#size-cells = <0x02>;
		#priority-cells = <0x01>;
		compatible = "simple-bus";
		ranges;
		phandle = <0x83>;

		downstream_amba {
			compatible = "qemu:memory-region";
			alias = <0x09>;
			reg = <0x00 0x00 0xffffffff 0xffffffff 0xffffffff>;
		};

		timer {
			compatible = "arm,armv8-timer";
			interrupt-parent = <0x01>;
			interrupts = <0x01 0x0d 0xff01 0x01 0x0e 0xff01 0x01 0x0b 0xff01 0x01 0x0a
				      0xff01>;
			clock-frequency = <0x5f5e100>;
		};
	};

	amba_apu_gic@0 {
		#address-cells = <0x02>;
		#size-cells = <0x02>;
		#priority-cells = <0x01>;
		compatible = "simple-bus";
		ranges;
		container = <0x07>;
		priority = <0xffffffff>;
		phandle = <0x12d>;

		interrupt-controller@APU_GIC_DIST {
			#address-cells = <0x00>;
			#size-cells = <0x00>;
			#interrupt-cells = <0x03>;
			compatible = "arm-gicv3";
			reg = <0x00 0xf9000000 0x00 0x10000 0x00 0x00 0xf9080000 0x00
			       0x80000 0x00>;
			interrupt-controller;
			interrupts-extended = <0x2d 0x00 0x2e 0x00 0x2d 0x01
					       0x2e 0x01 0x2d 0x02 0x2e 0x02
					       0x2d 0x03 0x2e 0x03 0x01 0x01
					       0x09 0x104 0x01 0x01 0x09 0x204
					       0x01 0x01 0x09 0x404 0x01 0x01
					       0x09 0x804>;
			num-cpu = <0x02>;
			num-irq = <0xe0>;
			has-security-extensions = <0x01>;
			has-lpi = <0x01>;
			sysmem = <0x09>;
			gpio-controller;
			#gpio-cells = <0x01>;
			phandle = <0x01>;
		};

		git_its@0xf9020000 {
			compatible = "arm-gicv3-its";
			reg = <0x00 0xf9020000 0x00 0x20000 0x00>;
			parent-gicv3 = <0x01>;
		};
	};

	lpd_reset_domain@0 {
		compatible = "qemu,reset-domain";
		mr0 = <0x06>;
		reset-gpios = <0x3e 0x07 0x3e 0x0a>;
	};

	fpd_reset_domain@0 {
		compatible = "qemu,reset-domain";
		mr0 = <0x07>;
		reset-gpios = <0x3e 0x07 0x3e 0x0a 0x19 0x1c 0x19 0x1d>;
	};

	amba_alias@0 {
		compatible = "qemu:memory-region";
		container = <0x8a>;
		alias = <0x09>;
		reg = <0x00 0x00 0xffffffff 0xffffffff 0x01>;
		phandle = <0x12e>;
	};

	qemu_sysmem@0 {
		#address-cells = <0x02>;
		#size-cells = <0x02>;
		#priority-cells = <0x01>;
		compatible = "qemu:system-memory";
		phandle = <0x8a>;
	};

	dummy_ppu0@0 {
		#interrupt-cells = <0x01>;
		phandle = <0x6e>;
	};

	dummy_ppu1@0 {
		#interrupt-cells = <0x01>;
		phandle = <0x73>;
	};

	dummy_ddrmc0@0 {
		#interrupt-cells = <0x01>;
		phandle = <0x7c>;
	};

	dummy_ddrmc1@0 {
		#interrupt-cells = <0x01>;
		phandle = <0x12f>;
	};

	ddr@0x00000000 {
		compatible = "qemu:memory-region";
		container = <0x8b>;
		qemu,ram = <0x01>;
		reg = <0x00 0x00 0x00 0x80000000 0x00>;
		phandle = <0x5a>;
	};

	ddr_2@0x800000000ULL {
		compatible = "qemu:memory-region-spec";
		container = <0x8c>;
		qemu,ram = <0x01>;
		reg = <0x08 0x00 0x08 0x00 0x00>;
		phandle = <0x130>;
	};

	mdio {
		#address-cells = <0x01>;
		#size-cells = <0x00>;
		#priority-cells = <0x00>;
		compatible = "mdio";
		phandle = <0x1b>;

		phy@1 {
			compatible = "dp83867";
			device_type = "ethernet-phy";
			reg = <0x01>;
			phandle = <0x131>;
		};

		phy@2 {
			compatible = "88e1118r";
			device_type = "ethernet-phy";
			reg = <0x02>;
			phandle = <0x132>;
		};
	};

	ddr_3@0x50000000000ULL {
		compatible = "qemu:memory-region";
		container = <0x8d>;
		qemu,ram = <0x01>;
		reg = <0x500 0x00 0x02 0x00 0x00>;
		phandle = <0x133>;
	};

	ddr_4@0x60000000000ULL {
		compatible = "qemu:memory-region";
		container = <0x8d>;
		qemu,ram = <0x01>;
		reg = <0x600 0x00 0x01 0x00 0x00>;
		phandle = <0x134>;
	};

	__symbols__ {
		pmc_ppu0_memattr = "/pmc_ppu0_ma";
		pmc_ppu1_memattr = "/pmc_ppu1_ma";
		psm_memattr = "/psm_ma";
		ddrmc_ub0_memattr = "/ddrmc_ub0_ma";
		ddrmc_ub1_memattr = "/ddrmc_ub1_ma";
		pmc_dma0_memattr = "/pmc_dma0_ma";
		pmc_dma1_memattr = "/pmc_dma1_ma";
		pmc_qspi_dma_memattr_smid = "/pmc_qspi_dma_ma_smid";
		pmc_qspi_dma_w_memattr_smid = "/pmc_qspi_dma_w_ma_smid";
		apu0_s_memattr = "/apu0_s_ma";
		apu0_ns_memattr = "/apu0_ns_ma";
		apu1_s_memattr = "/apu1_s_ma";
		apu1_ns_memattr = "/apu1_ns_ma";
		rpu0_s_memattr = "/rpu0_s_ma";
		rpu1_s_memattr = "/rpu1_s_ma";
		gem0_memattr_smid = "/gem0_ma_smid";
		gem0_w_memattr_smid = "/gem0_w_ma_smid";
		gem1_memattr_smid = "/gem1_ma_smid";
		gem1_w_memattr_smid = "/gem1_w_ma_smid";
		ospi_dma_memattr_smid = "/ospi_dma_ma_smid";
		ospi_dma_w_memattr_smid = "/ospi_dma_w_ma_smid";
		sd0_memattr_smid = "/sd0_ma_smid";
		sd0_w_memattr_smid = "/sd0_w_ma_smid";
		sd1_memattr_smid = "/sd1_ma_smid";
		sd1_w_memattr_smid = "/sd1_w_ma_smid";
		usb0_memattr = "/usb0_ma";
		amba_root = "/amba_root@0";
		amba = "/amba_root@0/amba@0";
		xmpu_ocm = "/amba_root@0/amba@0/xmpu_ocm@0";
		xmpu_ocm2 = "/amba_root@0/amba@0/xmpu_ocm2@0";
		loader_write_0xF1110880 = "/amba_root@0/amba@0/loader_write_cpu0_0x1@0xF1110880";
		loader_write_0xFD1A0050 = "/amba_root@0/amba@0/loader_write_cpu0_0x5@0xFD1A0050";
		loader_write_0xF111010C = "/amba_root@0/amba@0/loader_write_cpu0_0xFF@0xF111010C";
		amba_lpd = "/amba_root@0/amba_lpd@0";
		smmu = "/amba_root@0/amba_lpd@0/smmu@0xfd800000";
		smmu_reg = "/amba_root@0/amba_lpd@0/smmu0@0xfd5f0000";
		xppu_lpd = "/amba_root@0/amba_lpd@0/xppu_lpd@0xff990000";
		gem0 = "/amba_root@0/amba_lpd@0/ethernet@0xff0c0000";
		gem1 = "/amba_root@0/amba_lpd@0/ethernet@0xff0d0000";
		serial0 = "/amba_root@0/amba_lpd@0/serial@0xff000000";
		serial1 = "/amba_root@0/amba_lpd@0/serial@0xff010000";
		canfdbus0 = "/amba_root@0/amba_lpd@0/canfdbus@0";
		can0 = "/amba_root@0/amba_lpd@0/can@0xff060000";
		can1 = "/amba_root@0/amba_lpd@0/can@0xff070000";
		crl = "/amba_root@0/amba_lpd@0/crl@0xff5e0000";
		lpd_iou_slcr = "/amba_root@0/amba_lpd@0/slcr@0xff080000";
		rpu_ctrl = "/amba_root@0/amba_lpd@0/rpu_ctrl@0xff9a0000";
		ipi = "/amba_root@0/amba_lpd@0/ipi@0xff300000";
		spi0 = "/amba_root@0/amba_lpd@0/spi@0xff040000";
		spi0_flash0 = "/amba_root@0/amba_lpd@0/spi@0xff040000/spi0_flash0@0";
		spi1 = "/amba_root@0/amba_lpd@0/spi@0xff050000";
		spi1_flash0 = "/amba_root@0/amba_lpd@0/spi@0xff050000/spi1_flash0@0";
		dwc3_0 = "/amba_root@0/amba_lpd@0/usb2@USB2_0_XHCI";
		ttc0 = "/amba_root@0/amba_lpd@0/timer@0xff0e0000";
		ttc1 = "/amba_root@0/amba_lpd@0/timer@0xff0f0000";
		ttc2 = "/amba_root@0/amba_lpd@0/timer@0xff100000";
		ttc3 = "/amba_root@0/amba_lpd@0/timer@0xff110000";
		adma0_mattr = "/amba_root@0/amba_lpd@0/adma0mattr";
		adma0 = "/amba_root@0/amba_lpd@0/dma-controller@0xffa80000";
		adma1_mattr = "/amba_root@0/amba_lpd@0/adma1mattr";
		adma1 = "/amba_root@0/amba_lpd@0/dma-controller@0xffa90000";
		adma2_mattr = "/amba_root@0/amba_lpd@0/adma2mattr";
		adma2 = "/amba_root@0/amba_lpd@0/dma-controller@0xffaa0000";
		adma3_mattr = "/amba_root@0/amba_lpd@0/adma3mattr";
		adma3 = "/amba_root@0/amba_lpd@0/dma-controller@0xffab0000";
		adma4_mattr = "/amba_root@0/amba_lpd@0/adma4mattr";
		adma4 = "/amba_root@0/amba_lpd@0/dma-controller@0xffac0000";
		adma5_mattr = "/amba_root@0/amba_lpd@0/adma5mattr";
		adma5 = "/amba_root@0/amba_lpd@0/dma-controller@0xffad0000";
		adma6_mattr = "/amba_root@0/amba_lpd@0/adma6mattr";
		adma6 = "/amba_root@0/amba_lpd@0/dma-controller@0xffae0000";
		adma7_mattr = "/amba_root@0/amba_lpd@0/adma7mattr";
		adma7 = "/amba_root@0/amba_lpd@0/dma-controller@0xffaf0000";
		ps_i2c0 = "/amba_root@0/amba_lpd@0/lpd_i2c_wrapper/ps_i2c@0xff020000";
		ps_i2c1 = "/amba_root@0/amba_lpd@0/lpd_i2c_wrapper/ps_i2c@0xff030000";
		ocm_ctrl0 = "/amba_root@0/amba_lpd@0/ocm_ctrl@OCM";
		lpd_slcr = "/amba_root@0/amba_lpd@0/lpd_slcr@0xff410000";
		lpd_slcr_secure = "/amba_root@0/amba_lpd@0/lpd_slcr_secure@0xff510000";
		lpd_iou_slcr_secure = "/amba_root@0/amba_lpd@0/lpd_iou_slcr_secure@0xff0a0000";
		lpd_wwdt0 = "/amba_root@0/amba_lpd@0/wwdt@0xff120000";
		lpd_gpio = "/amba_root@0/amba_lpd@0/lpd_gpio@0xff0b0000";
		intlpd = "/amba_root@0/amba_lpd@0/intlpd@0xfe600000";
		amba_fpd = "/amba_root@0/amba_fpd@0";
		apu_ctrl = "/amba_root@0/amba_fpd@0/apu_ctrl@0xfd5c0000";
		wwdt0 = "/amba_root@0/amba_fpd@0/watchdog@0xfd4d0000";
		intfpd = "/amba_root@0/amba_fpd@0/intfpd@0xfd370000";
		amba_pmc_internal = "/amba_root@0/amba_pmc_internal@0";
		xmpu_pmc = "/amba_root@0/amba_pmc_internal@0/xmpu_pmc@0";
		xppu_pmc_npi = "/amba_root@0/amba_pmc_internal@0/xppu_pmc_npi@0xf1300000";
		xppu_pmc = "/amba_root@0/amba_pmc_internal@0/xppu_pmc@0xf1310000";
		amba_pmc = "/amba_root@0/amba_pmc@0";
		amba_pmc_iou = "/amba_root@0/amba_pmc_iou@0";
		pmc_iou_slcr = "/amba_root@0/amba_pmc_iou@0/pmc_iou_slcr@0xf1060000";
		pmc_iou_slcr_secure = "/amba_root@0/amba_pmc_iou@0/pmc_iou_slcr_secure@0xf1070000";
		pmc_qspi_dma_0 = "/amba_root@0/amba_pmc_iou@0/pmc_qspi_dma@QSPI_DMA";
		pmc_qspi_0 = "/amba_root@0/amba_pmc_iou@0/pmc_qspi@0xf1030000";
		qspi_flash_lcs_lb = "/amba_root@0/amba_pmc_iou@0/pmc_qspi@0xf1030000/
qspi_flash_lcs_lb@0";
		qspi_flash_lcs_ub = "/amba_root@0/amba_pmc_iou@0/pmc_qspi@0xf1030000/
qspi_flash_lcs_ub@0";
		qspi_flash_ucs_lb = "/amba_root@0/amba_pmc_iou@0/pmc_qspi@0xf1030000/
qspi_flash_ucs_lb@0";
		qspi_flash_ucs_ub = "/amba_root@0/amba_pmc_iou@0/pmc_qspi@0xf1030000/
qspi_flash_ucs_ub@0";
		ospi_dma_dst = "/amba_root@0/amba_pmc_iou@0/ospi_dst_dma@0";
		ospi_dma_src = "/amba_root@0/amba_pmc_iou@0/ospi_src_dma@0";
		ospi = "/amba_root@0/amba_pmc_iou@0/spi@0xf1010000";
		ospi_flash_lcs_lb = "/amba_root@0/amba_pmc_iou@0/spi@0xf1010000/
ospi_flash_lcs_lb@0";
		ospi_flash_lcs_ub = "/amba_root@0/amba_pmc_iou@0/spi@0xf1010000/
ospi_flash_lcs_ub@0";
		ospi_flash_ucs_lb = "/amba_root@0/amba_pmc_iou@0/spi@0xf1010000/
ospi_flash_ucs_lb@0";
		ospi_flash_ucs_ub = "/amba_root@0/amba_pmc_iou@0/spi@0xf1010000/
ospi_flash_ucs_ub@0";
		gpio_mr_mux = "/amba_root@0/amba_pmc_iou@0/gpio_mr_mux@0xc0000000";
		pmc_gpio = "/amba_root@0/amba_pmc_iou@0/pmc_gpio@0xf1020000";
		sdhci0 = "/amba_root@0/amba_pmc_iou@0/mmc@0xf1040000";
		sdhci1 = "/amba_root@0/amba_pmc_iou@0/mmc@0xf1050000";
		pmc_tap = "/amba_root@0/amba_pmc_iou@0/pmc_tap@0xf11a0000";
		pmc_i2c = "/amba_root@0/amba_pmc_iou@0/pmc_i2c_wrapper/pmc_i2c@0xf1000000";
		amba_pmc_sec = "/amba_root@0/amba_pmc_sec@0";
		pmc_dma0_src = "/amba_root@0/amba_pmc_sec@0/pmc_dma0_src@0";
		pmc_dma0_dst = "/amba_root@0/amba_pmc_sec@0/pmc_dma0_dst@0";
		pmc_dma1_src = "/amba_root@0/amba_pmc_sec@0/pmc_dma1_src@0";
		pmc_dma1_dst = "/amba_root@0/amba_pmc_sec@0/pmc_dma1_dst@0";
		pmc_stream_switch = "/amba_root@0/amba_pmc_sec@0/pmc_stream_switch@0";
		pmc_sha3 = "/amba_root@0/amba_pmc_sec@0/pmc_sha@0xf1210000";
		pmc_aes = "/amba_root@0/amba_pmc_sec@0/pmc_aes@0xf11e0000";
		xlnx_aes = "/amba_root@0/amba_pmc_sec@0/pmc_aes@0xf11e0000/xlnx_aes@0";
		pmc_rsa = "/amba_root@0/amba_pmc_sec@0/pmc_rsa@0xf1200000";
		xlnx_pmc_efuse_cache = "/amba_root@0/amba_pmc_sec@0/
xlnx_pmc_efuse_cache@0xf1250000";
		pmc_puf_ctrl = "/amba_root@0/amba_pmc_sec@0/pmc_puf_ctrl@0";
		pmc_efuse = "/amba_root@0/amba_pmc_sec@0/pmc_efuse@0xf1240000";
		xlnx_efuse = "/amba_root@0/amba_pmc_sec@0/pmc_efuse@0xf1240000/xlnx_efuse@0";
		pmc_bbram_ctrl = "/amba_root@0/amba_pmc_sec@0/pmc_bbram@0xf11f0000";
		pmc_sbi = "/amba_root@0/amba_pmc_sec@0/pmc_sbi@0xf1220000";
		amba_pmc_ppu = "/amba_root@0/amba_pmc_ppu@0";
		pmc_gic_proxy = "/amba_root@0/amba_pmc_ppu@0/pmc_gic_proxy@0";
		amba_pmc_sys = "/amba_root@0/amba_pmc_sys@0";
		pmc_clk_rst = "/amba_root@0/amba_pmc_sys@0/pmc_clk_rst@0xf1260000";
		pmc_int = "/amba_root@0/amba_pmc_sys@0/pmc_int@0xf1330000";
		pmc_global = "/amba_root@0/amba_pmc_sys@0/pmc_global@0xf1110000";
		pmc_err_mng = "/amba_root@0/amba_pmc_sys@0/pmc_err_mng@0xF1130000";
		pmc_stream_zero = "/amba_root@0/amba_pmc_sys@0/pmc_stream_zero@";
		pmc_sysmon = "/amba_root@0/amba_pmc_sys@0/pmc_sysmon@0xf1270000";
		pmc_ams_sat0 = "/amba_root@0/amba_pmc_sys@0/pmc_ams_sat@0";
		pmc_ams_sat1 = "/amba_root@0/amba_pmc_sys@0/pmc_ams_sat@1";
		pmc_global_tamper = "/amba_root@0/amba_pmc_sys@0/versal_pmc_tamper@";
		amba_pmc_pl = "/amba_root@0/amba_pmc_pl@0";
		noc_npi_nir = "/amba_root@0/amba_pmc_pl@0/noc_npi_nir@0xf6000000";
		npi_ddrmc_ub0 = "/amba_root@0/amba_pmc_pl@0/npi_ddrmc_ub0@0xf6110000";
		npi_ddrmc_main0 = "/amba_root@0/amba_pmc_pl@0/npi_ddrmc_main0@0xf6150000";
		npi_ddrmc_noc0 = "/amba_root@0/amba_pmc_pl@0/npi_ddrmc_noc0@0xf6070000";
		npi_ddrmc_ub1 = "/amba_root@0/amba_pmc_pl@0/npi_ddrmc_ub1@0xf6280000";
		npi_ddrmc_main1 = "/amba_root@0/amba_pmc_pl@0/npi_ddrmc_main1@0xf62c0000";
		npi_ddrmc_noc1 = "/amba_root@0/amba_pmc_pl@0/npi_ddrmc_noc1@0xf6210000";
		npi_ddrmc_ub2 = "/amba_root@0/amba_pmc_pl@0/npi_ddrmc_ub2@0xf63f0000";
		npi_ddrmc_main2 = "/amba_root@0/amba_pmc_pl@0/npi_ddrmc_main2@0xf6430000";
		npi_ddrmc_noc2 = "/amba_root@0/amba_pmc_pl@0/npi_ddrmc_noc2@0xf6380000";
		npi_ddrmc_ub3 = "/amba_root@0/amba_pmc_pl@0/npi_ddrmc_ub3@0xf6560000";
		npi_ddrmc_main3 = "/amba_root@0/amba_pmc_pl@0/npi_ddrmc_main3@0xf65a0000";
		npi_ddrmc_noc3 = "/amba_root@0/amba_pmc_pl@0/npi_ddrmc_noc3@0xf64f0000";
		npi_ddrmc_xmpu0 = "/amba_root@0/amba_pmc_pl@0/npi_ddrmc_xmpu0@0xf6070000";
		npi_me = "/amba_root@0/amba_pmc_pl@0/npi_me@0xf70a0000";
		noc_npi_devs = "/amba_root@0/amba_pmc_pl@0/noc_npi_devs@0";
		cfu = "/amba_root@0/amba_pmc_pl@0/cfu@0xf12b0000";
		cfu_fdro = "/amba_root@0/amba_pmc_pl@0/cfu_fdro@0xf12c2000";
		cfu_sfr = "/amba_root@0/amba_pmc_pl@0/cfu_sfr@0xf12c1000";
		cframe0_reg = "/amba_root@0/amba_pmc_pl@0/cframe0_reg@0xf12d0000";
		cframe1_reg = "/amba_root@0/amba_pmc_pl@0/cframe1_reg@0xf12d2000";
		cframe2_reg = "/amba_root@0/amba_pmc_pl@0/cframe2_reg@0xf12d4000";
		cframe3_reg = "/amba_root@0/amba_pmc_pl@0/cframe3_reg@0xf12d6000";
		cframe4_reg = "/amba_root@0/amba_pmc_pl@0/cframe4_reg@0xf12d8000";
		cframe5_reg = "/amba_root@0/amba_pmc_pl@0/cframe5_reg@0xf12da000";
		cframe6_reg = "/amba_root@0/amba_pmc_pl@0/cframe6_reg@0xf12dc000";
		cframe7_reg = "/amba_root@0/amba_pmc_pl@0/cframe7_reg@0xf12de000";
		cframe8_reg = "/amba_root@0/amba_pmc_pl@0/cframe8_reg@0xf12e0000";
		cframe9_reg = "/amba_root@0/amba_pmc_pl@0/cframe9_reg@0xf12e2000";
		cframe10_reg = "/amba_root@0/amba_pmc_pl@0/cframe10_reg@0xf12e4000";
		cframe11_reg = "/amba_root@0/amba_pmc_pl@0/cframe11_reg@0xf12e6000";
		cframe12_reg = "/amba_root@0/amba_pmc_pl@0/cframe12_reg@0xf12e8000";
		cframe13_reg = "/amba_root@0/amba_pmc_pl@0/cframe13_reg@0xf12ea000";
		cframe14_reg = "/amba_root@0/amba_pmc_pl@0/cframe14_reg@0xf12ec000";
		cframe_bcast_reg = "/amba_root@0/amba_pmc_pl@0/cframe_bcast_reg@0xf12ee000";
		npi_gty0 = "/amba_root@0/amba_pmc_pl@0/npi_gty0@0xf6890000";
		npi_gty1 = "/amba_root@0/amba_pmc_pl@0/npi_gty1@0xf68f0000";
		npi_gty2 = "/amba_root@0/amba_pmc_pl@0/npi_gty2@0xf6940000";
		npi_gty3 = "/amba_root@0/amba_pmc_pl@0/npi_gty3@0xf6990000";
		npi_gty4 = "/amba_root@0/amba_pmc_pl@0/npi_gty4@0xf69e0000";
		npi_gty5 = "/amba_root@0/amba_pmc_pl@0/npi_gty5@0xf6a30000";
		npi_gty6 = "/amba_root@0/amba_pmc_pl@0/npi_gty6@0xf6a90000";
		npi_gty7 = "/amba_root@0/amba_pmc_pl@0/npi_gty7@0xf70e0000";
		npi_gty8 = "/amba_root@0/amba_pmc_pl@0/npi_gty8@0xf7150000";
		npi_gty9 = "/amba_root@0/amba_pmc_pl@0/npi_gty9@0xf71b0000";
		amba_pmc_bat = "/amba_root@0/amba_pmc_bat@0";
		rtc = "/amba_root@0/amba_pmc_bat@0/rtc@0xf12a0000";
		amba_psm = "/amba_root@0/amba_psm@0";
		psm_ram_instr = "/amba_root@0/amba_psm@0/psm_ram_instr@0xffc00000";
		psm_ram_data = "/amba_root@0/amba_psm@0/psm_ram_data@0xffc20000";
		psm_gic_proxy = "/amba_root@0/amba_psm@0/psm_gic_proxy@0";
		psm_global = "/amba_root@0/amba_psm@0/psm_global_reg@0xffc90000";
		psm_err_mng = "/amba_root@0/amba_psm@0/psm_err_mng@0xffc90000";
		amba_xram = "/amba_root@0/amba_xram@0";
		crf = "/amba_root@0/crf@0xfd1a0000";
		lmb_pmc_ppu0 = "/lmb_pmc_ppu0@0";
		pmc_rom = "/lmb_pmc_ppu0@0/pmc_rom@0xf0000000";
		pmc_ppu0_ram = "/lmb_pmc_ppu0@0/ppu0_ram@0xf0060000";
		pmc_ppu0_io_module = "/lmb_pmc_ppu0@0/io-module@00";
		pmc_ppu0_io_intc = "/lmb_pmc_ppu0@0/io-module@00/pmc_ppu0_intc@0C";
		pmc_ppu0_io_gpi1 = "/lmb_pmc_ppu0@0/io-module@00/pmc_ppu0_gpi@20";
		pmc_ppu0_io_gpi2 = "/lmb_pmc_ppu0@0/io-module@00/pmc_ppu0_gpi@24";
		pmc_ppu0_io_gpi3 = "/lmb_pmc_ppu0@0/io-module@00/pmc_ppu0_gpi@28";
		pmc_ppu0_io_gpi4 = "/lmb_pmc_ppu0@0/io-module@00/pmc_ppu0_gpi@2c";
		pmc_ppu0_io_gpo1 = "/lmb_pmc_ppu0@0/io-module@00/pmc_ppu0_gpo@10";
		pmc_ppu0_io_gpo2 = "/lmb_pmc_ppu0@0/io-module@00/pmc_ppu0_gpo@14";
		pmc_ppu0_io_gpo3 = "/lmb_pmc_ppu0@0/io-module@00/pmc_ppu0_gpo@18";
		pmc_ppu0_io_gpo4 = "/lmb_pmc_ppu0@0/io-module@00/pmc_ppu0_gpo@1c";
		pmc_ppu0_io_pit1 = "/lmb_pmc_ppu0@0/io-module@00/pmc_ppu0_pit@40";
		pmc_ppu0_io_pit2 = "/lmb_pmc_ppu0@0/io-module@00/pmc_ppu0_pit@50";
		pmc_ppu0_io_pit3 = "/lmb_pmc_ppu0@0/io-module@00/pmc_ppu0_pit@60";
		pmc_ppu0_io_pit4 = "/lmb_pmc_ppu0@0/io-module@00/pmc_ppu0_pit@70";
		lmb_pmc_ppu1 = "/lmb_pmc_ppu1@0";
		pmc_ppu1_io_module = "/lmb_pmc_ppu1@0/io-module@00";
		pmc_ppu1_io_intc = "/lmb_pmc_ppu1@0/io-module@00/pmc_ppu1_intc@0C";
		pmc_ppu1_io_gpi1 = "/lmb_pmc_ppu1@0/io-module@00/pmc_ppu1_gpi@20";
		pmc_ppu1_io_gpi2 = "/lmb_pmc_ppu1@0/io-module@00/pmc_ppu1_gpi@24";
		pmc_ppu1_io_gpi3 = "/lmb_pmc_ppu1@0/io-module@00/pmc_ppu1_gpi@28";
		pmc_ppu1_io_gpi4 = "/lmb_pmc_ppu1@0/io-module@00/pmc_ppu1_gpi@2c";
		pmc_ppu1_io_gpo1 = "/lmb_pmc_ppu1@0/io-module@00/pmc_ppu1_gpo@10";
		pmc_ppu1_io_gpo2 = "/lmb_pmc_ppu1@0/io-module@00/pmc_ppu1_gpo@14";
		pmc_ppu1_io_gpo3 = "/lmb_pmc_ppu1@0/io-module@00/pmc_ppu1_gpo@18";
		pmc_ppu1_io_gpo4 = "/lmb_pmc_ppu1@0/io-module@00/pmc_ppu1_gpo@1c";
		pmc_ppu1_io_pit1 = "/lmb_pmc_ppu1@0/io-module@00/pmc_ppu1_pit@40";
		pmc_ppu1_io_pit2 = "/lmb_pmc_ppu1@0/io-module@00/pmc_ppu1_pit@50";
		pmc_ppu1_io_pit3 = "/lmb_pmc_ppu1@0/io-module@00/pmc_ppu1_pit@60";
		pmc_ppu1_io_pit4 = "/lmb_pmc_ppu1@0/io-module@00/pmc_ppu1_pit@70";
		lmb_psm = "/lmb_psm@0";
		psm_0_io_module = "/lmb_psm@0/io-module@00";
		psm0_io_intc = "/lmb_psm@0/io-module@00/psm0_intc@0C";
		psm0_io_gpo1 = "/lmb_psm@0/io-module@00/psm0_gpo@10";
		psm0_io_pit1 = "/lmb_psm@0/io-module@00/psm0_pit@40";
		psm0_io_pit2 = "/lmb_psm@0/io-module@00/psm0_pit@50";
		psm0_io_pit3 = "/lmb_psm@0/io-module@00/psm0_pit@60";
		psm0_io_pit4 = "/lmb_psm@0/io-module@00/psm0_pit@70";
		psm_local = "/lmb_psm@0/psm_local_reg@0xffc88000";
		lmb_ddrmc0 = "/lmb_ddrmc@0";
		ddrmc0_ram_data = "/lmb_ddrmc@0/ddrmc0_ram_data@0x1c000";
		ddrmc0_ram_instr = "/lmb_ddrmc@0/ddrmc0_ram_instr@0x20000";
		ddrmc0_ram_exchange = "/lmb_ddrmc@0/ddrmc0_ram_exchange@0x08000";
		ddrmc_0_io_module = "/lmb_ddrmc@0/io-module@00";
		ddrmc0_io_intc = "/lmb_ddrmc@0/io-module@00/ddrmc0_intc@0C";
		ddrmc0_io_gpo1 = "/lmb_ddrmc@0/io-module@00/ddrmc0_gpo@10";
		ddrmc0_io_pit1 = "/lmb_ddrmc@0/io-module@00/ddrmc0_pit@40";
		ddrmc0_io_pit2 = "/lmb_ddrmc@0/io-module@00/ddrmc0_pit@50";
		ddrmc0_io_pit3 = "/lmb_ddrmc@0/io-module@00/ddrmc0_pit@60";
		ddrmc0_io_pit4 = "/lmb_ddrmc@0/io-module@00/ddrmc0_pit@70";
		ddrmc_uart0 = "/lmb_ddrmc@0/ddrmc_uart0@0";
		lmb_ddrmc1 = "/lmb_ddrmc@1";
		ddrmc1_ram_data = "/lmb_ddrmc@1/ddrmc1_ram_data@0x1c000";
		ddrmc1_ram_instr = "/lmb_ddrmc@1/ddrmc1_ram_instr@0x20000";
		ddrmc1_ram_exchange = "/lmb_ddrmc@1/ddrmc1_ram_exchange@0x08000";
		amba_rpu = "/amba_rpu@0";
		rpu_gic = "/amba_rpu@0/interrupt-controller@0xf9000000";
		amba_r5_0 = "/amba_r5@0";
		amba_r5_1 = "/amba_r5@1";
		dummy1 = "/dummy1@0";
		smmu_tbu0 = "/tbu0_slave@0";
		smmu_tbu1 = "/tbu1_slave@0";
		smmu_tbu2 = "/tbu2_slave@0";
		smmu_tbu3 = "/tbu3_slave@0";
		smmu_tbu4 = "/tbu4_slave@0";
		smmu_tbu5 = "/tbu5_slave@0";
		smmu_tbu6 = "/tbu6_slave@0";
		ddr_mem = "/memory@00000000";
		ddr_2_mem = "/memory@8_0000_0000";
		ddr_3_mem = "/memory@0x50000000000ULL";
		ocm_mem = "/ocm_mem@0xfffc0000";
		ocm_mem_bank_0 = "/ocm_mem_bank_0@";
		ocm_mem_bank_1 = "/ocm_mem_bank_1@";
		ocm_mem_bank_2 = "/ocm_mem_bank_2@";
		ocm_mem_bank_3 = "/ocm_mem_bank_3@";
		xram_mem = "/xram_mem@0xfe800000";
		xram_mem_bank_0 = "/xram_mem_bank_0@0x0";
		xram_mem_bank_1 = "/xram_mem_bank_1@0x200000";
		xram_mem_bank_2 = "/xram_mem_bank_2@0x400000";
		xram_mem_bank_3 = "/xram_mem_bank_3@0x600000";
		ipi_msgbuf = "/ipi_msgbuf@0";
		pmc_ram = "/pmc_ram@0xf2000000";
		pmc_ram_bank_0 = "/pmc_ram_bank_0@0x0";
		pmc_ppu1_insn_ram = "/pmc_ppu1_ram@0xf0200000";
		pmc_ppu1_data_ram = "/pmc_ppu1_ram@0xf0240000";
		lqspi_mr = "/lqspi_mr@0";
		lospi_mr = "/lospi_mr@0";
		cpu0 = "/cpus/apu_cpu@0";
		cpu1 = "/cpus/apu_cpu@1";
		cpu2 = "/cpus/apu_cpu@2";
		cpu3 = "/cpus/apu_cpu@3";
		rpu_cpu0 = "/cpus/rpu_cpu@0";
		rpu_cpu1 = "/cpus/rpu_cpu@1";
		amba_apu = "/amba_apu@0";
		amba_apu_gic = "/amba_apu_gic@0";
		gic = "/amba_apu_gic@0/interrupt-controller@APU_GIC_DIST";
		amba_alias = "/amba_alias@0";
		qemu_sysmem = "/qemu_sysmem@0";
		psm0 = "/dummy_ppu0@0";
		pmc_ppu0 = "/dummy_ppu0@0";
		pmc_ppu1 = "/dummy_ppu1@0";
		ddrmc_ub0 = "/dummy_ddrmc0@0";
		ddrmc_ub1 = "/dummy_ddrmc1@0";
		ddr = "/ddr@0x00000000";
		ddr_2 = "/ddr_2@0x800000000ULL";
		mdio0 = "/mdio";
		phy0 = "/mdio/phy@1";
		phy1 = "/mdio/phy@2";
		ddr_3 = "/ddr_3@0x50000000000ULL";
		ddr_4 = "/ddr_4@0x60000000000ULL";
	};
};
